VERSION ""

NS_ :

BS_:

BU_:
VAL_TABLE_ TIM_AuthErrorCode 39 "LwAPossibleBitMismatch" 38 "AuthenticationAbortedDueToGeneralPeerError" 37 "AuthenticationAbortedByPeerDueToError" 36 "ChallengeDataCorrupt" 35 "InvalidChallengeLength" 34 "FunctionFacilityNotCertified" 33 "RequestNotAllowed" 32 "Reserved_0x20" 31 "AuthenticationTimeout" 30 "CertificateTypeInvalid" 29 "DeviceCertificateRevoked" 28 "ManufacturerSeriesCertificateRevoked" 27 "ManufacturerCertificateRevoked" 26 "LabCertificateRevoked" 25 "RootCertificateRevoked" 24 "CertificateTypeMismatch" 23 "CertificateChainInvalid" 22 "ECU_CCID_Mismatch" 21 "NAME_Mismatch" 20 "ECC_PublicKeyValidationFailed" 19 "UnexpectedRestartAuthenticationBitSet" 18 "AuthenticationStatusInvalid" 17 "AuthenticationTypeNotSupported" 16 "AuthenticationStatusLost" 15 "DeviceCertificateDataCorrupt" 14 "ManufacturerSeriesCertificateDataCorrupt" 13 "ManufacturerCertificateDataCorrupt" 12 "TestLabCertificateDataCorrupt" 11 "RootCertificateDataCorrupt" 10 "InternalError" 9 "ChallengesDontMatch" 8 "DeviceCertificateSignatureInvalid" 7 "ManufacturerSeriesCertificateSignatureInvalid" 6 "ManufacturerCertificateSignatureInvalid" 5 "LabCertificateSignatureInvalid" 4 "RootCertificateSignatureInvalid" 3 "NotAuthenticationServerOrClient" 2 "CertificateFormatNotSupported" 1 "ParticipantBusy" 0 "NoError" ;
VAL_TABLE_ TIM_CertificateType 255 "NotAvailable" 6 "CRLCertificate" 5 "CRLSigningCertificate" 4 "DeviceCertificate" 3 "ManufacturerSeriesCertificate" 2 "ManufacturerCertificate" 1 "TestlabCertificate" 0 "AEFRootCertificate" ;
VAL_TABLE_ NetworkInterconnUnitParametrics 16 "NetworkInterconnectionUnitType" 15 "NumberOfPorts" 14 "UptimeSinceLastPowerOnReset " 13 "AverageNumOfMsgsFilteredPerSec" 12 "AverageNumOfMsgsForwardedPerSec" 11 "AverageNumOfMsgsReceivedPerSec" 10 "NumOfMsgsWithExcessTransitDelayTime " 9 "NumOfMsgsLostDueToBufferOverflow " 8 "AverageTransitDelayTime" 7 "MaxTransitDelayTime" 6 "MaxNumOfMsgsFilteredPerSec" 5 "MaxNumOfMsgsForwardedPerSec" 4 "MaxNumOfMsgsReceivedPerSec" 3 "NumberOfFilterDatabaseEntries" 2 "MaxFilterDatabaseSize" 1 "BufferSize" 0 "RequestAllParameters" ;
VAL_TABLE_ FMI 0 "Above normal (most severe)" 1 "Below normal (most severe)" 2 "Data erratic" 3 "Voltage above normal" 4 "Voltage below normal" 5 "Current below normal" 6 "Current above normal" 7 "Mechanical system not responding" 8 "Abnormal frequency" 9 "Abnormal update rate" 10 "Abnormal rate of change" 11 "Root cause not known" 12 "Bad intelligent device" 13 "Out of calibration" 14 "Special intstructions" 15 "Above normal (least severe)" 16 "Above normal (moderately severe)" 17 "Below normal (least severe)" 18 "Below normal (moderately severe)" 19 "Received network data in error" 31 "Not available" 20 "Data Drifted High" 21 "Data Drifted Low" ;

BO_ 2624585470 AUTH21: 16 Vector__XXX
 SG_ NumberOfAuthenticatedServers m9 : 8|8@1+ (1,0) [0|255] "" Vector__XXX
 SG_ LwAPossible m250 : 30|1@1+ (1,0) [0|0] "" Vector__XXX
 SG_ TestlabCertIsValid m250 : 29|1@1+ (1,0) [0|0] "" Vector__XXX
 SG_ ReStartAuth m250 : 31|1@1+ (1,0) [0|0] "" Vector__XXX
 SG_ ManufactSeriesCertIsValid m250 : 27|1@1+ (1,0) [0|0] "" Vector__XXX
 SG_ ManufactCertIsValid m250 : 28|1@1+ (1,0) [0|0] "" Vector__XXX
 SG_ DeviceCertIsValid m250 : 26|1@1+ (1,0) [0|0] "" Vector__XXX
 SG_ ChallengeSigned m250 : 25|1@1+ (1,0) [0|0] "" Vector__XXX
 SG_ AuthenticationStatus m250 : 16|4@1+ (1,0) [0|0] "" Vector__XXX
 SG_ ChallengeData m5 : 40|16@1+ (1,0) [0|0] "" Vector__XXX
 SG_ CertificateData m3 : 40|16@1+ (1,0) [0|0] "" Vector__XXX
 SG_ ErrorCode m3 : 8|8@1+ (1,0) [0|0] "" Vector__XXX
 SG_ CertType m2 : 32|8@1+ (1,0) [0|0] "" Vector__XXX
 SG_ CertificateFormat m2 : 24|8@1+ (1,0) [0|0] "" Vector__XXX
 SG_ AuthenticationType m2 : 20|4@1+ (1,0) [0|0] "" Vector__XXX
 SG_ MessageCode M : 0|8@1+ (1,0) [0|0] "" Vector__XXX

BO_ 2624651006 AUTH12: 16 Vector__XXX
 SG_ NumberOfAuthenticatedClients m8 : 8|8@1+ (1,0) [0|255] "" Vector__XXX
 SG_ AuthenticationStatus m249 : 16|4@1+ (1,0) [0|0] "" Vector__XXX
 SG_ ChallengeSigned m249 : 25|1@1+ (1,0) [0|0] "" Vector__XXX
 SG_ DeviceCertIsValid m249 : 26|1@1+ (1,0) [0|0] "" Vector__XXX
 SG_ ManufactSeriesCertIsValid m249 : 27|1@1+ (1,0) [0|0] "" Vector__XXX
 SG_ ManufactCertIsValid m249 : 28|1@1+ (1,0) [0|0] "" Vector__XXX
 SG_ TestlabCertIsValid m249 : 29|1@1+ (1,0) [0|0] "" Vector__XXX
 SG_ LwAPossible m249 : 30|1@1+ (1,0) [0|0] "" Vector__XXX
 SG_ ReStartAuth m249 : 31|1@1+ (1,0) [0|0] "" Vector__XXX
 SG_ ChallengeData m4 : 40|16@1+ (1,0) [0|0] "" Vector__XXX
 SG_ CertificateData m2 : 40|16@1+ (1,0) [0|0] "" Vector__XXX
 SG_ CertType m2 : 32|8@1+ (1,0) [0|0] "" Vector__XXX
 SG_ CertificateFormat m2 : 24|8@1+ (1,0) [0|0] "" Vector__XXX
 SG_ AuthenticationType m2 : 20|4@1+ (1,0) [0|0] "" Vector__XXX
 SG_ MessageCode M : 0|8@1+ (1,0) [0|0] "" Vector__XXX
 SG_ ErrorCode m2 : 8|8@1+ (1,0) [0|0] "" Vector__XXX

BO_ 2619670270 TIM21: 16 Vector__XXX
 SG_ CurvatureRequest m70 : 32|16@1+ (0.25,-8032) [-8032|8031.75] "1/km" Vector__XXX
 SG_ VehicleSpeedRequest m68 : 32|16@1+ (0.001,-32.128) [-32.127|32.127] "m/s" Vector__XXX
 SG_ HitchPosReq m66 : 32|16@1+ (0.01,0) [0|100] "%" Vector__XXX
 SG_ PTOSpeedRequest m64 : 32|16@1+ (0.125,-4016) [0|0] "1/min" Vector__XXX
 SG_ RequestCounter m1 : 8|4@1+ (1,0) [0|0] "" Vector__XXX
 SG_ AuxValveFlowReq m1 : 32|16@1+ (0.004,-128.512) [0|0] "%" Vector__XXX
 SG_ TIMClientState m249 : 20|4@1+ (1,0) [0|0] "" Vector__XXX
 SG_ ClientHearbeatCounter m249 : 8|8@1+ (1,0) [0|0] "" Vector__XXX
 SG_ TIMFunctionId_4 m245 : 64|8@1+ (1,0) [0|0] "" Vector__XXX
 SG_ TIMFunctionId_3 m245 : 48|8@1+ (1,0) [0|0] "" Vector__XXX
 SG_ TIMFunctionId_2 m245 : 32|8@1+ (1,0) [0|0] "" Vector__XXX
 SG_ TIMFunctionId_1 m245 : 16|8@1+ (1,0) [0|0] "" Vector__XXX
 SG_ NumOfTIMFunctions m245 : 8|8@1+ (1,0) [1|250] "" Vector__XXX
 SG_ RequestType_4 m245 : 77|3@1+ (1,0) [0|0] "" Vector__XXX
 SG_ RequestType_3 m245 : 61|3@1+ (1,0) [0|0] "" Vector__XXX
 SG_ RequestType_2 m245 : 45|3@1+ (1,0) [0|0] "" Vector__XXX
 SG_ RequestType_1 m245 : 29|3@1+ (1,0) [0|0] "" Vector__XXX
 SG_ MinimumTIMVersionNr m246 : 24|8@1+ (1,0) [0|0] "" Vector__XXX
 SG_ ImplementedTIMVersionNr m246 : 16|8@1+ (1,0) [0|0] "" Vector__XXX
 SG_ TIMMessageType m1 : 12|4@1+ (1,0) [0|0] "" Vector__XXX
 SG_ GroupFunctionValue M : 0|8@1+ (1,0) [0|0] "" Vector__XXX

BO_ 2619604734 TIM12: 16 Vector__XXX
 SG_ Curvature m70 : 32|16@1+ (0.25,-8032) [-8032|8031.75] "1/km" Vector__XXX
 SG_ GuidanceExitReasonCode m70 : 27|5@1+ (1,0) [0|0] "" Vector__XXX
 SG_ VehicleSpeed m68 : 32|16@1+ (0.001,-32.128) [-32.127|32.127] "m/s" Vector__XXX
 SG_ SpeedExitReasonCode m68 : 27|5@1+ (1,0) [0|0] "" Vector__XXX
 SG_ HitchPosition m66 : 32|16@1+ (0.01,0) [0|100] "%" Vector__XXX
 SG_ HitchExitReasonCode m66 : 27|5@1+ (1,0) [0|0] "" Vector__XXX
 SG_ PTOSpeed m64 : 32|16@1+ (0.125,-4016) [0|0] "1/min" Vector__XXX
 SG_ PTOExitReasonCode m64 : 27|5@1+ (1,0) [0|0] "" Vector__XXX
 SG_ TIMAuxValveFlow m1 : 32|16@1+ (0.004,-128.512) [0|0] "%" Vector__XXX
 SG_ FlowType m1 : 24|2@1+ (1,0) [0|0] "" Vector__XXX
 SG_ ReflectedRequestCounter m1 : 8|4@1+ (1,0) [0|0] "" Vector__XXX
 SG_ AuxValveExitReasonCode m1 : 27|5@1+ (1,0) [0|0] "" Vector__XXX
 SG_ AutomationStatus m1 : 16|4@1+ (1,0) [0|0] "" Vector__XXX
 SG_ TIMSystemOperationState m250 : 24|4@1+ (1,0) [0|15] "" Vector__XXX
 SG_ TIMServerState m250 : 28|4@1+ (1,0) [0|0] "" Vector__XXX
 SG_ TIMSystemState m250 : 16|4@1+ (1,0) [0|0] "" Vector__XXX
 SG_ TIMServerMasterIndication m250 : 20|4@1+ (1,0) [0|0] "" Vector__XXX
 SG_ ServerHeartbeatCounter m250 : 8|8@1+ (1,0) [0|0] "" Vector__XXX
 SG_ AssignmentResult_4 m245 : 77|3@1+ (1,0) [0|0] "" Vector__XXX
 SG_ AssignmentResult_3 m245 : 61|3@1+ (1,0) [0|0] "" Vector__XXX
 SG_ AssignmentResult_2 m245 : 45|3@1+ (1,0) [0|0] "" Vector__XXX
 SG_ AssignmentErrorReason_4 m245 : 72|5@1+ (1,0) [0|0] "" Vector__XXX
 SG_ AssignmentErrorReason_3 m245 : 56|5@1+ (1,0) [0|0] "" Vector__XXX
 SG_ AssignmentErrorReason_2 m245 : 40|5@1+ (1,0) [0|0] "" Vector__XXX
 SG_ AssignmentErrorReason_1 m245 : 24|5@1+ (1,0) [0|0] "" Vector__XXX
 SG_ AssignmentResult_1 m245 : 29|3@1+ (1,0) [0|0] "" Vector__XXX
 SG_ TIMFunctionId_4 m245 : 64|8@1+ (1,0) [0|0] "" Vector__XXX
 SG_ TIMFunctionId_3 m245 : 48|8@1+ (1,0) [0|0] "" Vector__XXX
 SG_ TIMFunctionId_2 m245 : 32|8@1+ (1,0) [0|0] "" Vector__XXX
 SG_ TIMFunctionId_1 m245 : 16|8@1+ (1,0) [0|0] "" Vector__XXX
 SG_ NumOfTIMFunctions m245 : 8|8@1+ (1,0) [1|250] "" Vector__XXX
 SG_ NumOfSuportedTIMFunctions m244 : 8|8@1+ (1,0) [1|250] "" Vector__XXX
 SG_ TIMConnectionVersion m246 : 16|8@1+ (1,0) [0|0] "" Vector__XXX
 SG_ ErrorCode m246 : 8|8@1+ (1,0) [0|0] "" Vector__XXX
 SG_ MinimumTIMVersionNr m248 : 24|8@1+ (1,0) [0|0] "" Vector__XXX
 SG_ ImplementedTIMVersionNr m248 : 16|8@1+ (1,0) [0|0] "" Vector__XXX
 SG_ BootTime m248 : 8|8@1+ (1,0) [0|0] "" Vector__XXX
 SG_ TIMMessageType m1 : 12|4@1+ (1,0) [0|0] "" Vector__XXX
 SG_ GroupFunctionValue M : 0|8@1+ (1,0) [0|0] "" Vector__XXX

BO_ 2314732542 GNSSPosDeltaHiPrecRapidUpdate: 8 Vector__XXX
 SG_ LongitudeDelta : 40|24@1- (10,0) [0|0] "µsec" Vector__XXX
 SG_ LatitudeDelta : 16|24@1- (10,0) [0|0] "µsec" Vector__XXX
 SG_ TimeDelta : 8|8@1+ (5,0) [0|0] "ms" Vector__XXX
 SG_ SequenceID : 0|8@1+ (1,0) [0|0] "" Vector__XXX

BO_ 2364597502 HB: 1 Vector__XXX
 SG_ HeartbeatSequenceNumber : 0|8@1+ (1,0) [0|0] "" Vector__XXX

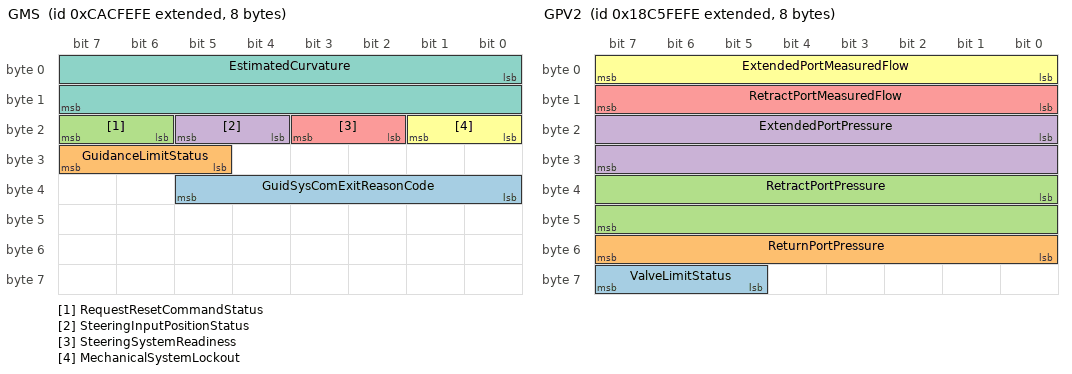
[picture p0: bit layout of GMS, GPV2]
BO_ 2360147710 GMS: 8 Vector__XXX
 SG_ GuidSysComExitReasonCode : 32|6@1+ (1,0) [0|63] "" Vector__XXX
 SG_ GuidanceLimitStatus : 29|3@1+ (1,0) [0|7] "" Vector__XXX
 SG_ RequestResetCommandStatus : 22|2@1+ (1,0) [0|3] "" Vector__XXX
 SG_ SteeringInputPositionStatus : 20|2@1+ (1,0) [0|3] "" Vector__XXX
 SG_ SteeringSystemReadiness : 18|2@1+ (1,0) [0|3] "" Vector__XXX
 SG_ MechanicalSystemLockout : 16|2@1+ (1,0) [0|3] "" Vector__XXX
 SG_ EstimatedCurvature : 0|16@1+ (0.25,-8032) [-8032|8031.75] "1/km" Vector__XXX

BO_ 2360213246 GSC: 8 Vector__XXX
 SG_ CurvatureCommandStatus : 16|2@1+ (1,0) [0|3] "" Vector__XXX
 SG_ CurvatureCommand : 0|16@1+ (0.25,-8032) [-8032|8031.75] "1/km" Vector__XXX

BO_ 2563047166 GPV3: 8 Vector__XXX
 SG_ FailSaveModeCmd : 22|2@1+ (1,0) [0|3] "" Vector__XXX
 SG_ StateCmd : 16|4@1+ (1,0) [0|15] "" Vector__XXX
 SG_ PortFlowCmd : 0|8@1+ (0.4,0) [0|100] "%" Vector__XXX

BO_ 2563112702 GPV2: 8 Vector__XXX
 SG_ ValveLimitStatus : 61|3@1+ (1,0) [0|7] "" Vector__XXX
 SG_ ReturnPortPressure : 48|8@1+ (16,0) [0|4000] "kPa" Vector__XXX
 SG_ RetractPortPressure : 32|16@1+ (5,0) [0|321275] "kPa" Vector__XXX
 SG_ ExtendedPortPressure : 16|16@1+ (5,0) [0|321275] "kPa" Vector__XXX
 SG_ RetractPortMeasuredFlow : 8|8@1+ (1,-125) [-125|125] "%" Vector__XXX
 SG_ ExtendedPortMeasuredFlow : 0|8@1+ (1,-125) [-125|125] "%" Vector__XXX

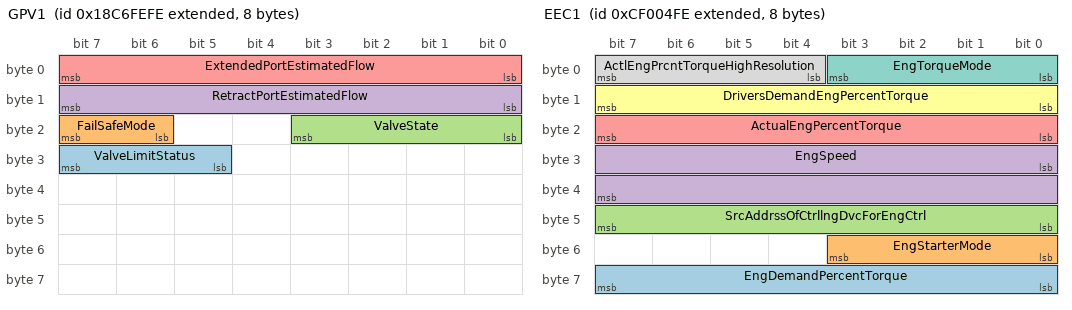
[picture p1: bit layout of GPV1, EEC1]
BO_ 2563178238 GPV1: 8 Vector__XXX
 SG_ ValveLimitStatus : 29|3@1+ (1,0) [0|7] "" Vector__XXX
 SG_ FailSafeMode : 22|2@1+ (1,0) [0|3] "" Vector__XXX
 SG_ ValveState : 16|4@1+ (1,0) [0|15] "" Vector__XXX
 SG_ RetractPortEstimatedFlow : 8|8@1+ (1,-125) [-125|125] "%" Vector__XXX
 SG_ ExtendedPortEstimatedFlow : 0|8@1+ (1,-125) [-125|125] "%" Vector__XXX

BO_ 2628452094 CFS: 9 Vector__XXX
 SG_ SA_ATTR_SupportsLongFilenames m51 : 21|1@1+ (1,0) [0|1] "" Vector__XXX
 SG_ SA_ATTR_VolumeSupportsHidden m51 : 18|1@1+ (1,0) [0|1] "" Vector__XXX
 SG_ SA_ATTR_VolumeIsRemovable m51 : 22|1@1+ (1,0) [0|1] "" Vector__XXX
 SG_ SA_ATTR_VolumeIsCaseSensitive m51 : 23|1@1+ (1,0) [0|1] "" Vector__XXX
 SG_ SA_ATTR_IsVolume m51 : 19|1@1+ (1,0) [0|1] "" Vector__XXX
 SG_ SA_ATTR_IsDirectory m51 : 20|1@1+ (1,0) [0|1] "" Vector__XXX
 SG_ VI_VolumeName m64 : 56|16@1+ (1,0) [0|65535] "" Vector__XXX
 SG_ VI_Flag_OverwriteExisting m64 : 48|1@1+ (1,0) [0|1] "" Vector__XXX
 SG_ MF_DestinationPathNameLength m48 : 40|16@1+ (1,0) [0|65535] "" Vector__XXX
 SG_ RF_ReportHiddenFiles m34 : 40|8@1+ (1,0) [0|255] "" Vector__XXX
 SG_ SF_Offset m33 : 32|32@1- (1,0) [-2147483648|2147483647] "" Vector__XXX
 SG_ RF_Count m34 : 24|16@1+ (1,0) [0|65535] "" Vector__XXX
 SG_ SF_PositionMode m33 : 24|8@1+ (1,0) [0|255] "" Vector__XXX
 SG_ OF_PathName m32 : 24|16@1+ (1,0) [0|65535] "" Vector__XXX
 SG_ MF_SourcePathNameLength m48 : 24|16@1+ (1,0) [0|65535] "" Vector__XXX
 SG_ WF_Count m35 : 24|16@1+ (1,0) [0|65535] "" Vector__XXX
 SG_ DF_PathName m49 : 24|16@1+ (1,0) [0|65535] "" Vector__XXX
 SG_ SA_PathName m51 : 24|16@1+ (1,0) [0|65535] "" Vector__XXX
 SG_ VI_Space m64 : 16|32@1+ (1,0) [0|4294967295] "" Vector__XXX
 SG_ OF_FlagExclusiveAccess m32 : 20|1@1+ (1,0) [0|1] "" Vector__XXX
 SG_ OF_FlagAppend m32 : 19|1@1+ (1,0) [0|1] "" Vector__XXX
 SG_ SA_ATTR_Hidden m51 : 17|1@1+ (1,0) [0|1] "" Vector__XXX
 SG_ OF_FlagCreateNew m32 : 18|1@1+ (1,0) [0|1] "" Vector__XXX
 SG_ MF_MoveModeRecursive m48 : 18|1@1+ (1,0) [0|1] "" Vector__XXX
 SG_ DF_DeleteModeRecursive m49 : 18|1@1+ (1,0) [0|1] "" Vector__XXX
 SG_ MF_MoveModeForce m48 : 17|1@1+ (1,0) [0|1] "" Vector__XXX
 SG_ DF_DeleteModeForce m49 : 17|1@1+ (1,0) [0|1] "" Vector__XXX
 SG_ VI_Flag_UsingSpaceSpecified m64 : 49|1@1+ (1,0) [0|1] "" Vector__XXX
 SG_ SA_ATTR_ReadOnly m51 : 16|1@1+ (1,0) [0|1] "" Vector__XXX
 SG_ CF_Handle m36 : 16|8@1+ (1,0) [0|255] "" Vector__XXX
 SG_ WF_Handle m35 : 16|8@1+ (1,0) [0|255] "" Vector__XXX
 SG_ RF_Handle m34 : 16|8@1+ (1,0) [0|255] "" Vector__XXX
 SG_ SF_Handle m33 : 16|8@1+ (1,0) [0|255] "" Vector__XXX
 SG_ OF_FlagReadWrite m32 : 16|2@1+ (1,0) [0|3] "" Vector__XXX
 SG_ CCD_PathName m17 : 16|16@1+ (1,0) [0|65535] "" Vector__XXX
 SG_ MF_MoveModeCopy m48 : 16|1@1+ (1,0) [0|1] "" Vector__XXX
 SG_ DF_DeleteMode m49 : 16|1@1+ (1,0) [0|1] "" Vector__XXX
 SG_ GA_PathName m50 : 16|16@1+ (1,0) [0|65535] "" Vector__XXX
 SG_ FDT_PathName m52 : 16|16@1+ (1,0) [0|65535] "" Vector__XXX
 SG_ VS_VolumeName m2 : 16|16@1+ (1,0) [0|0] "" Vector__XXX
 SG_ VS_RequestVolumeToPrepareForRemo m2 : 9|1@1- (1,0) [0|1] "" Vector__XXX
 SG_ CCD_TAN m17 : 8|8@1+ (1,0) [0|255] "" Vector__XXX
 SG_ GCD_TAN m16 : 8|8@1+ (1,0) [0|255] "" Vector__XXX
 SG_ FDT_TAN m52 : 8|8@1+ (1,0) [0|255] "" Vector__XXX
 SG_ SA_TAN m51 : 8|8@1+ (1,0) [0|255] "" Vector__XXX
 SG_ GA_TAN m50 : 8|8@1+ (1,0) [0|255] "" Vector__XXX
 SG_ RF_TAN m34 : 8|8@1+ (1,0) [0|255] "" Vector__XXX
 SG_ CF_TAN m36 : 8|8@1+ (1,0) [0|255] "" Vector__XXX
 SG_ WF_TAN m35 : 8|8@1+ (1,0) [0|255] "" Vector__XXX
 SG_ SF_TAN m33 : 8|8@1+ (1,0) [0|255] "" Vector__XXX
 SG_ OF_TAN m32 : 8|8@1+ (1,0) [0|255] "" Vector__XXX
 SG_ MF_TAN m48 : 8|8@1+ (1,0) [0|255] "" Vector__XXX
 SG_ DF_TAN m49 : 8|8@1+ (1,0) [0|255] "" Vector__XXX
 SG_ VI_TAN m64 : 8|8@1+ (1,0) [0|255] "" Vector__XXX
 SG_ VS_ReportVolumeUsedByClient m2 : 8|1@1+ (1,0) [0|1] "" Vector__XXX
 SG_ CM_VersionNumber m0 : 8|8@1+ (1,0) [0|255] "" Vector__XXX
 SG_ FSClientCommand M : 0|8@1+ (1,0) [0|255] "" Vector__XXX

BO_ 2628517630 FSC: 35 Vector__XXX
 SG_ OF_ATTR_VolumeSupportsHidden m32 : 34|1@1+ (1,0) [0|1] "" Vector__XXX
 SG_ GCD_PathName m16 : 88|16@1+ (1,0) [0|65535] "" Vector__XXX
 SG_ GCD_FreeSpace m16 : 56|32@1+ (512,0) [0|4294966744] "Bytes" Vector__XXX
 SG_ FDT_TimeHour m52 : 51|5@1+ (1,0) [0|23] "Hour" Vector__XXX
 SG_ FDT_TimeMinutes m52 : 45|6@1+ (1,0) [0|59] "Minutes" Vector__XXX
 SG_ FDT_TimeSeconds m52 : 40|5@1+ (2,0) [0|58] "Seconds" Vector__XXX
 SG_ OF_ATTR_VolumeIsCaseSensitive m32 : 39|1@1+ (1,0) [0|1] "" Vector__XXX
 SG_ OF_ATTR_VolumeIsRemovable m32 : 38|1@1+ (1,0) [0|1] "" Vector__XXX
 SG_ OF_ATTR_SupportsLongFilenames m32 : 37|1@1+ (1,0) [0|1] "" Vector__XXX
 SG_ OF_ATTR_IsDirectory m32 : 36|1@1+ (1,0) [0|1] "" Vector__XXX
 SG_ OF_ATTR_IsVolume m32 : 35|1@1+ (1,0) [0|1] "" Vector__XXX
 SG_ FDT_DateYear m52 : 33|7@1+ (1,1980) [1980|2107] "Year" Vector__XXX
 SG_ OF_ATTR_Hidden m32 : 33|1@1+ (1,0) [0|1] "" Vector__XXX
 SG_ SF_Position m33 : 32|32@1+ (1,0) [0|4294967295] "" Vector__XXX
 SG_ OF_ATTR_ReadOnly m32 : 32|1@1+ (1,0) [0|1] "" Vector__XXX
 SG_ GA_Size m50 : 32|32@1+ (1,0) [0|4294967295] "" Vector__XXX
 SG_ VS_VolumeName m2 : 32|16@1+ (1,0) [0|65535] "" Vector__XXX
 SG_ VI_VolumeIsCaseSensitive m64 : 31|1@1+ (1,0) [0|1] "" Vector__XXX
 SG_ GA_ATTR_VolumeIsCaseSensitive m50 : 31|1@1+ (1,0) [0|1] "" Vector__XXX
 SG_ VI_ATTR_VolumeRemovable m64 : 30|1@1+ (1,0) [0|1] "" Vector__XXX
 SG_ GA_ATTR_VolumeIsRemovable m50 : 30|1@1+ (1,0) [0|1] "" Vector__XXX
 SG_ VI_ATTR_SupportsLongFilenames m64 : 29|1@1+ (1,0) [0|1] "" Vector__XXX
 SG_ FDT_DateMonth m52 : 29|4@1+ (1,0) [0|12] "Month" Vector__XXX
 SG_ GA_ATTR_SupportsLongFilenames m50 : 29|1@1+ (1,0) [0|1] "" Vector__XXX
 SG_ GA_ATTR_IsDirectory m50 : 28|1@1+ (1,0) [0|1] "" Vector__XXX
 SG_ VI_ATTR_IsDirectory m64 : 28|1@1+ (1,0) [0|1] "" Vector__XXX
 SG_ VI_ATTR_IsVolume m64 : 27|1@1+ (1,0) [0|1] "" Vector__XXX
 SG_ GA_ATTR_IsVolume m50 : 27|1@1+ (1,0) [0|1] "" Vector__XXX
 SG_ VI_ATTR_VolumeSupportsHidden m64 : 26|1@1+ (1,0) [0|1] "" Vector__XXX
 SG_ GA_ATTR_VolumeSupportsHidden m50 : 26|1@1+ (1,0) [0|1] "" Vector__XXX
 SG_ VI_ATTR_Hidden m64 : 25|1@1+ (1,0) [0|1] "" Vector__XXX
 SG_ GA_ATTR_Hidden m50 : 25|1@1+ (1,0) [0|1] "" Vector__XXX
 SG_ VI_ATTR_ReadOnly m64 : 24|1@1+ (1,0) [0|1] "" Vector__XXX
 SG_ FDT_DateDay m52 : 24|5@1+ (1,0) [0|31] "Day" Vector__XXX
 SG_ GA_ATTR_ReadOnly m50 : 24|1@1+ (1,0) [0|1] "" Vector__XXX
 SG_ OF_Handle m32 : 24|8@1+ (1,0) [0|255] "" Vector__XXX
 SG_ GCD_TotalSpace m16 : 24|32@1+ (512,0) [0|4294966744] "Bytes" Vector__XXX
 SG_ RF_Count m34 : 24|16@1+ (1,0) [0|65535] "Bytes" Vector__XXX
 SG_ GSP_SupportMultipleVolumes m1 : 24|1@1+ (1,0) [0|255] "" Vector__XXX
 SG_ WF_Count m35 : 24|16@1+ (1,0) [0|65535] "" Vector__XXX
 SG_ VS_ErrorCode m2 : 24|8@1+ (1,0) [0|255] "" Vector__XXX
 SG_ FDT_ErrorCode m52 : 16|8@1+ (1,0) [0|255] "" Vector__XXX
 SG_ RF_ErrorCode m34 : 16|8@1+ (1,0) [0|255] "" Vector__XXX
 SG_ SF_ErrorCode m33 : 16|8@1+ (1,0) [0|255] "" Vector__XXX
 SG_ FSNumberOfOpenFiles m0 : 16|8@1- (1,0) [0|255] "" Vector__XXX
 SG_ OF_ErrorCode m32 : 16|8@1+ (1,0) [0|255] "" Vector__XXX
 SG_ WF_ErrorCode m35 : 16|8@1+ (1,0) [0|255] "" Vector__XXX
 SG_ CF_ErrorCode m36 : 16|8@1+ (1,0) [0|255] "" Vector__XXX
 SG_ MF_ErrorCode m48 : 16|8@1+ (1,0) [0|255] "" Vector__XXX
 SG_ GA_ErrorCode m50 : 16|8@1+ (1,0) [0|255] "" Vector__XXX
 SG_ SA_ErrorCode m51 : 16|8@1+ (1,0) [0|255] "" Vector__XXX
 SG_ GCD_ErrorCode m16 : 16|8@1+ (1,0) [0|255] "" Vector__XXX
 SG_ CCD_ErrorCode m17 : 16|8@1+ (1,0) [0|255] "" Vector__XXX
 SG_ GSP_MaxNrSimultaneousFilesOpen m1 : 16|8@1+ (1,0) [0|255] "" Vector__XXX
 SG_ DF_ErrorCode m49 : 16|8@1+ (1,0) [0|255] "" Vector__XXX
 SG_ VI_ErrorCode m64 : 16|8@1+ (1,0) [0|255] "" Vector__XXX
 SG_ VS_MaxTimeBeforeVolRemoval m2 : 16|8@1+ (1,0) [0|250] "min/bit" Vector__XXX
 SG_ FSBusyWriting m0 : 9|1@1+ (1,0) [0|1] "" Vector__XXX
 SG_ FSBusyReading m0 : 8|1@1+ (1,0) [0|1] "" Vector__XXX
 SG_ OF_TAN m32 : 8|8@1+ (1,0) [0|255] "" Vector__XXX
 SG_ SF_TAN m33 : 8|8@1+ (1,0) [0|255] "" Vector__XXX
 SG_ RF_TAN m34 : 8|8@1+ (1,0) [0|255] "" Vector__XXX
 SG_ WF_TAN m35 : 8|8@1+ (1,0) [0|255] "" Vector__XXX
 SG_ CF_TAN m36 : 8|8@1+ (1,0) [0|255] "" Vector__XXX
 SG_ MF_TAN m48 : 8|8@1+ (1,0) [0|255] "" Vector__XXX
 SG_ GA_TAN m50 : 8|8@1+ (1,0) [0|255] "" Vector__XXX
 SG_ SA_TAN m51 : 8|8@1+ (1,0) [0|255] "" Vector__XXX
 SG_ FDT_TAN m52 : 8|8@1+ (1,0) [0|255] "" Vector__XXX
 SG_ GCD_TAN m16 : 8|8@1+ (1,0) [0|255] "" Vector__XXX
 SG_ CCD_TAN m17 : 8|8@1+ (1,0) [0|255] "" Vector__XXX
 SG_ GSP_VersionNumber m1 : 8|8@1+ (1,0) [0|255] "" Vector__XXX
 SG_ DF_TAN m49 : 8|8@1+ (1,0) [0|255] "" Vector__XXX
 SG_ VI_TAN m64 : 8|8@1+ (1,0) [0|255] "" Vector__XXX
 SG_ VS_VolumeStatus m2 : 8|8@1+ (1,0) [0|3] "" Vector__XXX
 SG_ FSServerCommand M : 0|8@1+ (1,0) [0|255] "" Vector__XXX

BO_ 2364540158 EEC1: 8 Vector__XXX
 SG_ EngDemandPercentTorque : 56|8@1+ (1,-125) [-125|125] "%" Vector__XXX
 SG_ EngStarterMode : 48|4@1+ (1,0) [0|15] "" Vector__XXX
 SG_ SrcAddrssOfCtrllngDvcForEngCtrl : 40|8@1+ (1,0) [0|255] "" Vector__XXX
 SG_ EngSpeed : 24|16@1+ (0.125,0) [0|8031.875] "rpm" Vector__XXX
 SG_ ActualEngPercentTorque : 16|8@1+ (1,-125) [-125|125] "%" Vector__XXX
 SG_ DriversDemandEngPercentTorque : 8|8@1+ (1,-125) [-125|125] "%" Vector__XXX
 SG_ EngTorqueMode : 0|4@1+ (1,0) [0|15] "" Vector__XXX
 SG_ ActlEngPrcntTorqueHighResolution : 4|4@1+ (0.125,0) [0|0.875] "%" Vector__XXX

BO_ 2563243774 ETP_DT: 8 Vector__XXX
 SG_ Byte7 : 56|8@1+ (1,0) [0|255] "" Vector__XXX
 SG_ Byte6 : 48|8@1+ (1,0) [0|255] "" Vector__XXX
 SG_ Byte5 : 40|8@1+ (1,0) [0|255] "" Vector__XXX
 SG_ Byte4 : 32|8@1+ (1,0) [0|255] "" Vector__XXX
 SG_ Byte3 : 24|8@1+ (1,0) [0|255] "" Vector__XXX
 SG_ Byte2 : 16|8@1+ (1,0) [0|255] "" Vector__XXX
 SG_ Byte1 : 8|8@1+ (1,0) [0|255] "" Vector__XXX
 SG_ SequenceNumber : 0|8@1+ (1,0) [1|255] "" Vector__XXX

BO_ 2563309310 ETP_CM: 8 Vector__XXX
 SG_ PGNumber : 40|24@1+ (1,0) [0|16777200] "" Vector__XXX
 SG_ DataPacketOffset m22 : 16|24@1+ (1,0) [0|16777215] "" Vector__XXX
 SG_ NextPacketNumberToSend m21 : 16|24@1+ (1,0) [1|16777215] "" Vector__XXX
 SG_ NumberOfBytesTransfered m23 : 8|32@1+ (1,0) [1786|117440505] "" Vector__XXX
 SG_ NumberOfPacketsOffset m22 : 8|8@1+ (1,0) [1|255] "" Vector__XXX
 SG_ NumberOfPacketsToSend m21 : 8|8@1+ (1,0) [1|255] "" Vector__XXX
 SG_ NumberOfBytesToTransfer m20 : 8|32@1+ (1,0) [1786|117440505] "" Vector__XXX
 SG_ ControlByte M : 0|8@1+ (1,0) [0|255] "" Vector__XXX
 SG_ ConnectionAbortReason m255 : 8|8@1+ (1,0) [0|255] "" Vector__XXX

BO_ 2314732030 GNSSPositionRapidUpdate: 8 Vector__XXX
 SG_ Longitude : 32|32@1- (1E-007,0) [-180|180] "deg" Vector__XXX
 SG_ Latitude : 0|32@1- (1E-007,0) [-90|90] "deg" Vector__XXX

BO_ 2583168510 GNSSPositionData: 47 Vector__XXX
 SG_ AgeOfDGNSSCorrections1 : 360|16@1+ (0.01,0) [0|655.32] "sec" Vector__XXX
 SG_ ReferenceStationID1 : 348|12@1+ (1,0) [0|4095] "" Vector__XXX
 SG_ RefrenceStationType1 : 344|4@1+ (1,0) [0|15] "" Vector__XXX
 SG_ NumberOfReferenceStations : 336|8@1+ (1,0) [0|252] "" Vector__XXX
 SG_ GeoidalSeparation : 304|32@1- (0.01,0) [-21470000|21470000] "m" Vector__XXX
 SG_ PDOP : 288|16@1- (0.01,0) [-327.64|327.64] "" Vector__XXX
 SG_ HDOP : 272|16@1- (0.01,0) [-327.64|327.64] "" Vector__XXX
 SG_ NumberOfSVs : 264|8@1+ (1,0) [0|252] "" Vector__XXX
 SG_ GNSSIntegrity : 256|2@1+ (1,0) [0|3] "" Vector__XXX
 SG_ GNSSMethod : 252|4@1+ (1,0) [0|15] "" Vector__XXX
 SG_ TypeOfSystem : 248|4@1+ (1,0) [0|4] "" Vector__XXX
 SG_ Altitude : 184|64@1- (1E-006,0) [-9223372036854.78|9223372036854.78] "m" Vector__XXX
 SG_ Longitude : 120|64@1- (1E-016,0) [-180|180] "deg" Vector__XXX
 SG_ Latitude : 56|64@1- (1E-016,0) [-90|90] "deg" Vector__XXX
 SG_ PositionTime : 24|32@1+ (0.0001,0) [0|86401] "s" Vector__XXX
 SG_ PositionDate : 8|16@1+ (1,0) [0|65532] "day" Vector__XXX
 SG_ SequenceID : 0|8@1+ (1,0) [0|255] "" Vector__XXX

BO_ 2583299838 GNSSPseudoRangeNoiseStatistic: 15 Vector__XXX
 SG_ STDofAltError : 104|16@1+ (0.01,0) [0|655.32] "m" Vector__XXX
 SG_ STDofLonError : 88|16@1+ (0.01,0) [0|655.32] "m" Vector__XXX
 SG_ STDofLatError : 72|16@1+ (0.01,0) [0|655.32] "m" Vector__XXX
 SG_ OrientationOfMinorAxis : 56|16@1+ (0.0001,0) [0|6.2832] "rad" Vector__XXX
 SG_ STDofMinorAxis : 40|16@1+ (0.01,0) [0|655.32] "m" Vector__XXX
 SG_ STDofMajorAxis : 24|16@1+ (0.01,0) [0|655.32] "m" Vector__XXX
 SG_ RMSofPositionUncertainty : 8|16@1+ (0.01,0) [0|655.32] "m" Vector__XXX
 SG_ SequenceID : 0|8@1+ (1,0) [0|255] "" Vector__XXX

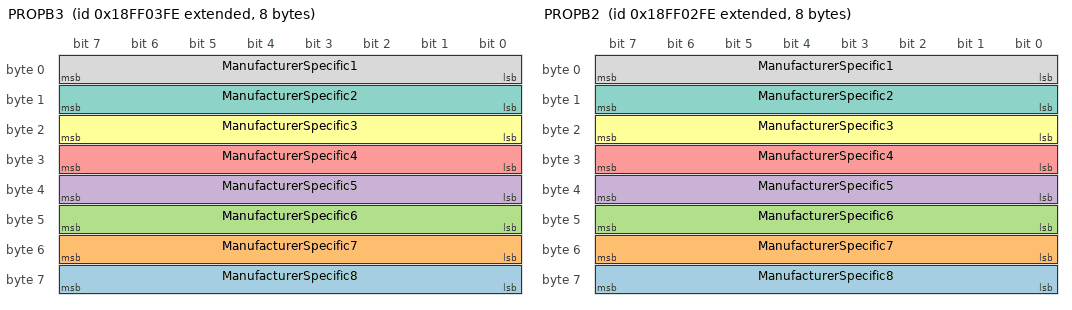
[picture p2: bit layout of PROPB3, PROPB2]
BO_ 2566849534 PROPB3: 8 Vector__XXX
 SG_ ManufacturerSpecific8 : 56|8@1+ (1,0) [0|255] "" Vector__XXX
 SG_ ManufacturerSpecific7 : 48|8@1+ (1,0) [0|255] "" Vector__XXX
 SG_ ManufacturerSpecific6 : 40|8@1+ (1,0) [0|255] "" Vector__XXX
 SG_ ManufacturerSpecific5 : 32|8@1+ (1,0) [0|255] "" Vector__XXX
 SG_ ManufacturerSpecific4 : 24|8@1+ (1,0) [0|255] "" Vector__XXX
 SG_ ManufacturerSpecific3 : 16|8@1+ (1,0) [0|255] "" Vector__XXX
 SG_ ManufacturerSpecific2 : 8|8@1+ (1,0) [0|255] "" Vector__XXX
 SG_ ManufacturerSpecific1 : 0|8@1+ (1,0) [0|255] "" Vector__XXX

BO_ 2566849278 PROPB2: 8 Vector__XXX
 SG_ ManufacturerSpecific8 : 56|8@1+ (1,0) [0|255] "" Vector__XXX
 SG_ ManufacturerSpecific7 : 48|8@1+ (1,0) [0|255] "" Vector__XXX
 SG_ ManufacturerSpecific6 : 40|8@1+ (1,0) [0|255] "" Vector__XXX
 SG_ ManufacturerSpecific5 : 32|8@1+ (1,0) [0|255] "" Vector__XXX
 SG_ ManufacturerSpecific4 : 24|8@1+ (1,0) [0|255] "" Vector__XXX
 SG_ ManufacturerSpecific3 : 16|8@1+ (1,0) [0|255] "" Vector__XXX
 SG_ ManufacturerSpecific2 : 8|8@1+ (1,0) [0|255] "" Vector__XXX
 SG_ ManufacturerSpecific1 : 0|8@1+ (1,0) [0|255] "" Vector__XXX

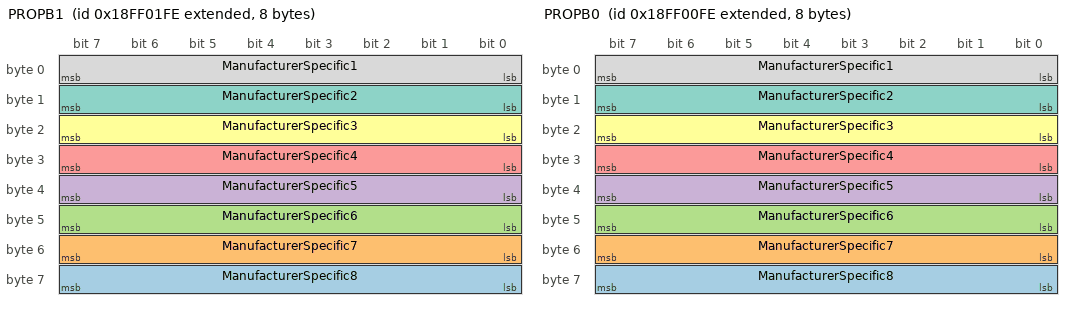
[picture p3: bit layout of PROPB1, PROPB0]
BO_ 2566849022 PROPB1: 8 Vector__XXX
 SG_ ManufacturerSpecific8 : 56|8@1+ (1,0) [0|255] "" Vector__XXX
 SG_ ManufacturerSpecific7 : 48|8@1+ (1,0) [0|255] "" Vector__XXX
 SG_ ManufacturerSpecific6 : 40|8@1+ (1,0) [0|255] "" Vector__XXX
 SG_ ManufacturerSpecific5 : 32|8@1+ (1,0) [0|255] "" Vector__XXX
 SG_ ManufacturerSpecific4 : 24|8@1+ (1,0) [0|255] "" Vector__XXX
 SG_ ManufacturerSpecific3 : 16|8@1+ (1,0) [0|255] "" Vector__XXX
 SG_ ManufacturerSpecific2 : 8|8@1+ (1,0) [0|255] "" Vector__XXX
 SG_ ManufacturerSpecific1 : 0|8@1+ (1,0) [0|255] "" Vector__XXX

BO_ 2566848766 PROPB0: 8 Vector__XXX
 SG_ ManufacturerSpecific8 : 56|8@1+ (1,0) [0|255] "" Vector__XXX
 SG_ ManufacturerSpecific7 : 48|8@1+ (1,0) [0|255] "" Vector__XXX
 SG_ ManufacturerSpecific6 : 40|8@1+ (1,0) [0|255] "" Vector__XXX
 SG_ ManufacturerSpecific5 : 32|8@1+ (1,0) [0|255] "" Vector__XXX
 SG_ ManufacturerSpecific4 : 24|8@1+ (1,0) [0|255] "" Vector__XXX
 SG_ ManufacturerSpecific3 : 16|8@1+ (1,0) [0|255] "" Vector__XXX
 SG_ ManufacturerSpecific2 : 8|8@1+ (1,0) [0|255] "" Vector__XXX
 SG_ ManufacturerSpecific1 : 0|8@1+ (1,0) [0|255] "" Vector__XXX

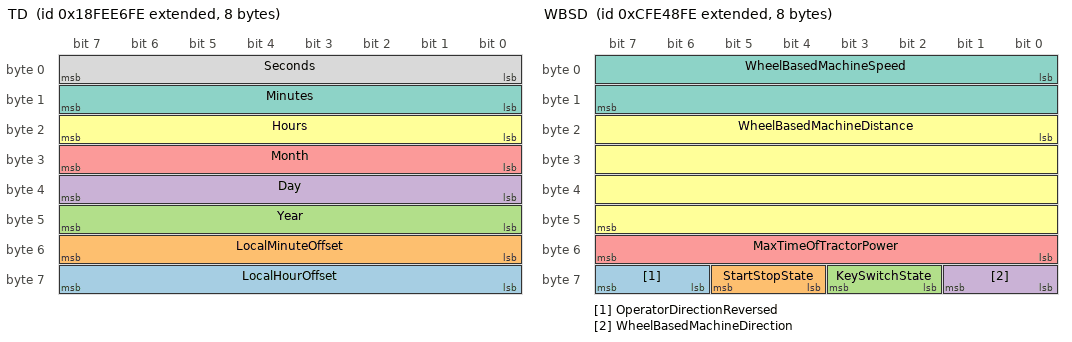
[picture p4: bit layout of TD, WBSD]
BO_ 2566842110 TD: 8 Vector__XXX
 SG_ LocalHourOffset : 56|8@1+ (1,-125) [-125|125] "hr" Vector__XXX
 SG_ LocalMinuteOffset : 48|8@1+ (1,-125) [-125|125] "mins" Vector__XXX
 SG_ Year : 40|8@1+ (1,1985) [1985|2235] "years" Vector__XXX
 SG_ Day : 32|8@1+ (0.25,0) [0|62.5] "days" Vector__XXX
 SG_ Month : 24|8@1+ (1,0) [0|250] "months" Vector__XXX
 SG_ Hours : 16|8@1+ (1,0) [0|250] "hr" Vector__XXX
 SG_ Minutes : 8|8@1+ (1,0) [0|250] "mins" Vector__XXX
 SG_ Seconds : 0|8@1+ (0.25,0) [0|62.5] "s" Vector__XXX

BO_ 2365475326 GBSD: 8 Vector__XXX
 SG_ GroundBasedMachineDirection : 56|2@1+ (1,0) [0|3] "" Vector__XXX
 SG_ GroundBasedMachineDistance : 16|32@1+ (0.001,0) [0|4211080] "m" Vector__XXX
 SG_ GroundBasedMachineSpeed : 0|16@1+ (0.001,0) [0|64.255] "m/s" Vector__XXX

BO_ 2365475070 WBSD: 8 Vector__XXX
 SG_ OperatorDirectionReversed : 62|2@1+ (1,0) [0|3] "" Vector__XXX
 SG_ StartStopState : 60|2@1+ (1,0) [0|4] "" Vector__XXX
 SG_ KeySwitchState : 58|2@1+ (1,0) [0|3] "" Vector__XXX
 SG_ WheelBasedMachineDirection : 56|2@1+ (1,0) [0|3] "" Vector__XXX
 SG_ MaxTimeOfTractorPower : 48|8@1+ (1,0) [0|250] "min" Vector__XXX
 SG_ WheelBasedMachineDistance : 16|32@1+ (0.001,0) [0|4211081.215] "m" Vector__XXX
 SG_ WheelBasedMachineSpeed : 0|16@1+ (0.001,0) [0|64.255] "m/s" Vector__XXX

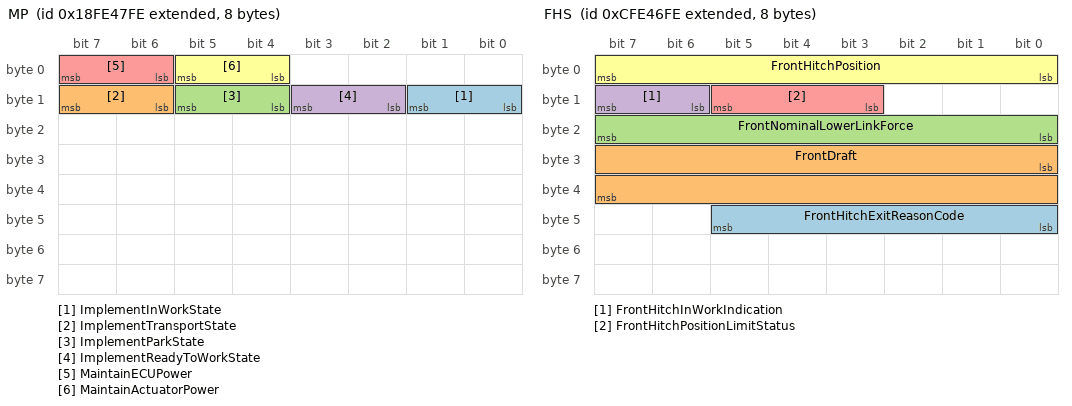
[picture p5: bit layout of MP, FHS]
BO_ 2566801406 MP: 8 Vector__XXX
 SG_ ImplementInWorkState : 8|2@1+ (1,0) [0|0] "" Vector__XXX
 SG_ ImplementTransportState : 14|2@1+ (1,0) [0|3] "" Vector__XXX
 SG_ ImplementParkState : 12|2@1+ (1,0) [0|3] "" Vector__XXX
 SG_ ImplementReadyToWorkState : 10|2@1+ (1,0) [0|3] "" Vector__XXX
 SG_ MaintainECUPower : 6|2@1+ (1,0) [0|0] "" Vector__XXX
 SG_ MaintainActuatorPower : 4|2@1+ (1,0) [0|3] "" Vector__XXX

BO_ 2365474558 FHS: 8 Vector__XXX
 SG_ FrontHitchExitReasonCode : 40|6@1+ (1,0) [0|63] "" Vector__XXX
 SG_ FrontDraft : 24|16@1+ (10,-320000) [-320000|322550] "N" Vector__XXX
 SG_ FrontNominalLowerLinkForce : 16|8@1+ (0.8,-100) [-100|100] "%" Vector__XXX
 SG_ FrontHitchInWorkIndication : 14|2@1+ (1,0) [0|3] "" Vector__XXX
 SG_ FrontHitchPositionLimitStatus : 11|3@1+ (1,0) [0|7] "" Vector__XXX
 SG_ FrontHitchPosition : 0|8@1+ (0.4,0) [0|100] "%" Vector__XXX

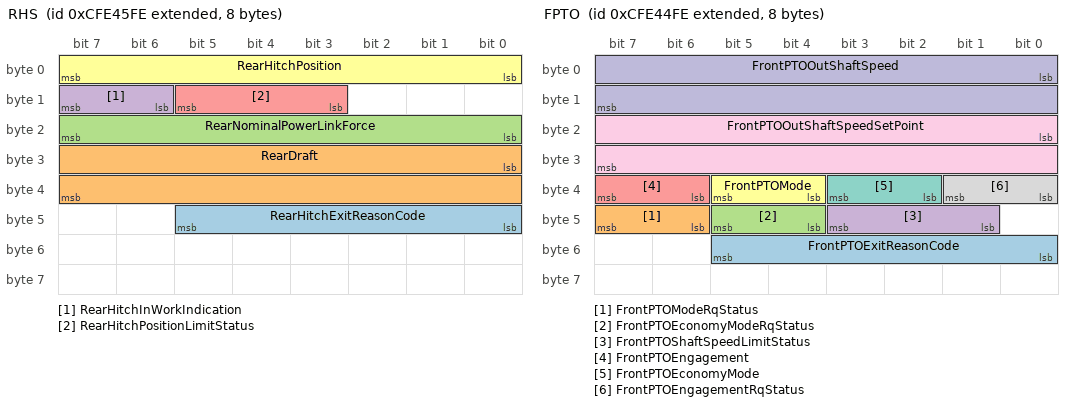
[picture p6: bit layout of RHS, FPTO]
BO_ 2365474302 RHS: 8 Vector__XXX
 SG_ RearHitchExitReasonCode : 40|6@1+ (1,0) [0|63] "" Vector__XXX
 SG_ RearDraft : 24|16@1+ (10,-320000) [-320000|322550] "N" Vector__XXX
 SG_ RearNominalPowerLinkForce : 16|8@1+ (0.8,-100) [-100|100] "%" Vector__XXX
 SG_ RearHitchInWorkIndication : 14|2@1+ (1,0) [0|3] "" Vector__XXX
 SG_ RearHitchPositionLimitStatus : 11|3@1+ (1,0) [0|7] "" Vector__XXX
 SG_ RearHitchPosition : 0|8@1+ (0.4,0) [0|100] "%" Vector__XXX

BO_ 2365474046 FPTO: 8 Vector__XXX
 SG_ FrontPTOExitReasonCode : 48|6@1+ (1,0) [0|63] "" Vector__XXX
 SG_ FrontPTOModeRqStatus : 46|2@1+ (1,0) [0|3] "" Vector__XXX
 SG_ FrontPTOEconomyModeRqStatus : 44|2@1+ (1,0) [0|3] "" Vector__XXX
 SG_ FrontPTOShaftSpeedLimitStatus : 41|3@1+ (1,0) [0|7] "" Vector__XXX
 SG_ FrontPTOEngagement : 38|2@1+ (1,0) [0|3] "" Vector__XXX
 SG_ FrontPTOMode : 36|2@1+ (1,0) [0|3] "" Vector__XXX
 SG_ FrontPTOEconomyMode : 34|2@1+ (1,0) [0|3] "" Vector__XXX
 SG_ FrontPTOEngagementRqStatus : 32|2@1+ (1,0) [0|3] "" Vector__XXX
 SG_ FrontPTOOutShaftSpeedSetPoint : 16|16@1+ (0.125,0) [0|8031.88] "1/min" Vector__XXX
 SG_ FrontPTOOutShaftSpeed : 0|16@1+ (0.125,0) [0|8031.88] "1/min" Vector__XXX

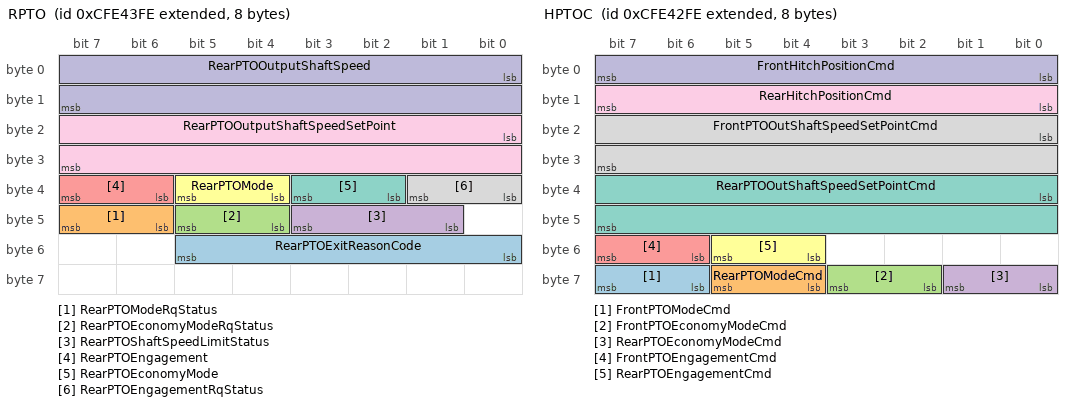
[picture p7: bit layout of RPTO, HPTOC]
BO_ 2365473790 RPTO: 8 Vector__XXX
 SG_ RearPTOExitReasonCode : 48|6@1+ (1,0) [0|63] "" Vector__XXX
 SG_ RearPTOModeRqStatus : 46|2@1+ (1,0) [0|3] "" Vector__XXX
 SG_ RearPTOEconomyModeRqStatus : 44|2@1+ (1,0) [0|3] "" Vector__XXX
 SG_ RearPTOShaftSpeedLimitStatus : 41|3@1+ (1,0) [0|7] "" Vector__XXX
 SG_ RearPTOEngagement : 38|2@1+ (1,0) [0|3] "" Vector__XXX
 SG_ RearPTOMode : 36|2@1+ (1,0) [0|3] "" Vector__XXX
 SG_ RearPTOEconomyMode : 34|2@1+ (1,0) [0|3] "" Vector__XXX
 SG_ RearPTOEngagementRqStatus : 32|2@1+ (1,0) [0|3] "" Vector__XXX
 SG_ RearPTOOutputShaftSpeedSetPoint : 16|16@1+ (0.125,0) [0|8031.88] "1/min" Vector__XXX
 SG_ RearPTOOutputShaftSpeed : 0|16@1+ (0.125,0) [0|8031.88] "1/min" Vector__XXX

BO_ 2365473534 HPTOC: 8 Vector__XXX
 SG_ FrontPTOModeCmd : 62|2@1+ (1,0) [0|3] "" Vector__XXX
 SG_ RearPTOModeCmd : 60|2@1+ (1,0) [0|3] "" Vector__XXX
 SG_ FrontPTOEconomyModeCmd : 58|2@1+ (1,0) [0|3] "" Vector__XXX
 SG_ RearPTOEconomyModeCmd : 56|2@1+ (1,0) [0|3] "" Vector__XXX
 SG_ FrontPTOEngagementCmd : 54|2@1+ (1,0) [0|3] "" Vector__XXX
 SG_ RearPTOEngagementCmd : 52|2@1+ (1,0) [0|3] "" Vector__XXX
 SG_ RearPTOOutShaftSpeedSetPointCmd : 32|16@1+ (0.125,0) [0|801.875] "1/min" Vector__XXX
 SG_ FrontPTOOutShaftSpeedSetPointCmd : 16|16@1+ (0.125,0) [0|8031.875] "1/min" Vector__XXX
 SG_ RearHitchPositionCmd : 8|8@1+ (0.4,0) [0|100] "%" Vector__XXX
 SG_ FrontHitchPositionCmd : 0|8@1+ (0.4,0) [0|100] "%" Vector__XXX

BO_ 2365473278 LCMD: 8 Vector__XXX
 SG_ ImplementRearWorkLightCmd : 62|2@1+ (1,0) [0|3] "" Vector__XXX
 SG_ ImplementLeftFacingWorkLightCmd : 60|2@1+ (1,0) [0|3] "" Vector__XXX
 SG_ ImplementRightFacingWorkLightCmd : 58|2@1+ (1,0) [0|3] "" Vector__XXX
 SG_ LightingDataRequestCmd : 56|2@1+ (1,0) [0|3] "" Vector__XXX
 SG_ ImplementLeftForwardLightCmd : 54|2@1+ (1,0) [0|3] "" Vector__XXX
 SG_ ImplementRightForwardLightCmd : 52|2@1+ (1,0) [0|3] "" Vector__XXX
 SG_ ImplementOEMOption1LightCmd : 50|2@1+ (1,0) [0|3] "" Vector__XXX
 SG_ ImplementOEMOption2LightCmd : 48|2@1+ (1,0) [0|3] "" Vector__XXX
 SG_ TractorFrontHighWorkLightCmd : 46|2@1+ (1,0) [0|3] "" Vector__XXX
 SG_ TractorFrontLowWorkLightCmd : 44|2@1+ (1,0) [0|3] "" Vector__XXX
 SG_ TractorSideHighWorkLightCmd : 42|2@1+ (1,0) [0|3] "" Vector__XXX
 SG_ TractorSideLowWorkLightCmd : 40|2@1+ (1,0) [0|3] "" Vector__XXX
 SG_ TractorRearHighWorkLightCmd : 38|2@1+ (1,0) [0|3] "" Vector__XXX
 SG_ TractorRearLowWorkLightCmd : 36|2@1+ (1,0) [0|3] "" Vector__XXX
 SG_ TractorUndersideWorkLightCmd : 34|2@1+ (1,0) [0|3] "" Vector__XXX
 SG_ RearFogLightCmd : 32|2@1+ (1,0) [0|3] "" Vector__XXX
 SG_ TractorMarkerLightCmd : 30|2@1+ (1,0) [0|3] "" Vector__XXX
 SG_ ImplementMarkerLightCmd : 28|2@1+ (1,0) [0|3] "" Vector__XXX
 SG_ TractorClearanceLightCmd : 26|2@1+ (1,0) [0|3] "" Vector__XXX
 SG_ ImplementClearanceLightCmd : 24|2@1+ (1,0) [0|3] "" Vector__XXX
 SG_ LeftStopLightCmd : 22|2@1+ (1,0) [0|3] "" Vector__XXX
 SG_ RightStopLightCmd : 20|2@1+ (1,0) [0|3] "" Vector__XXX
 SG_ CentreStopLightCmd : 18|2@1+ (1,0) [0|3] "" Vector__XXX
 SG_ BackUpLightAndAlarmHornCmd : 16|2@1+ (1,0) [0|3] "" Vector__XXX
 SG_ LeftTurnSignalLightCmd : 14|2@1+ (1,0) [0|3] "" Vector__XXX
 SG_ RightTurnSignalLightCmd : 12|2@1+ (1,0) [0|3] "" Vector__XXX
 SG_ RotatingBeaconLightCmd : 10|2@1+ (1,0) [0|3] "" Vector__XXX
 SG_ TractorFrontFogLightCmd : 8|2@1+ (1,0) [0|3] "" Vector__XXX
 SG_ HighBeamHeadLightCmd : 6|2@1+ (1,0) [0|3] "" Vector__XXX
 SG_ LowBeamHeadLightCmd : 4|2@1+ (1,0) [0|3] "" Vector__XXX
 SG_ AlternateHeadLightCmd : 2|2@1+ (1,0) [0|3] "" Vector__XXX
 SG_ DaytimeRunningLightCmd : 0|2@1+ (1,0) [0|3] "" Vector__XXX

BO_ 2566799614 LID: 8 Vector__XXX
 SG_ ImplementRearWorkLightData : 62|2@1+ (1,0) [0|3] "" Vector__XXX
 SG_ ImplLeftFacingWorkLightData : 60|2@1+ (1,0) [0|3] "" Vector__XXX
 SG_ ImplRightFacingWorkLightData : 58|2@1+ (1,0) [0|3] "" Vector__XXX
 SG_ ImplementLeftForwardLightData : 54|2@1+ (1,0) [0|3] "" Vector__XXX
 SG_ ImplementRightForwardLightData : 52|2@1+ (1,0) [0|3] "" Vector__XXX
 SG_ ImplementOEMOption1LightData : 50|2@1+ (1,0) [0|3] "" Vector__XXX
 SG_ ImplementOEMOption2LightData : 48|2@1+ (1,0) [0|3] "" Vector__XXX
 SG_ TractorFrontHighWorkLightData : 46|2@1+ (1,0) [0|3] "" Vector__XXX
 SG_ TractorFrontLowWorkLightData : 44|2@1+ (1,0) [0|3] "" Vector__XXX
 SG_ TractorSideHighWorkLightData : 42|2@1+ (1,0) [0|3] "" Vector__XXX
 SG_ TractorSideLowWorkLightData : 40|2@1+ (1,0) [0|3] "" Vector__XXX
 SG_ TractorRearHighWorkLightData : 38|2@1+ (1,0) [0|3] "" Vector__XXX
 SG_ TractorRearLowWorkLightData : 36|2@1+ (1,0) [0|3] "" Vector__XXX
 SG_ TractorUndersideWorkLightData : 34|2@1+ (1,0) [0|3] "" Vector__XXX
 SG_ RearFogLightData : 32|2@1+ (1,0) [0|3] "" Vector__XXX
 SG_ TractorMarkerLightData : 30|2@1+ (1,0) [0|3] "" Vector__XXX
 SG_ ImplementMarkerLightData : 28|2@1+ (1,0) [0|3] "" Vector__XXX
 SG_ TractorClearanceLightData : 26|2@1+ (1,0) [0|3] "" Vector__XXX
 SG_ ImplementClearanceLightData : 24|2@1+ (1,0) [0|3] "" Vector__XXX
 SG_ LefttStopLightData : 22|2@1+ (1,0) [0|3] "" Vector__XXX
 SG_ RightStopLightData : 20|2@1+ (1,0) [0|3] "" Vector__XXX
 SG_ CentreStopLightData : 18|2@1+ (1,0) [0|3] "" Vector__XXX
 SG_ BackUpLightAndAlarmHornData : 16|2@1+ (1,0) [0|3] "" Vector__XXX
 SG_ LeftTurnSignalLightData : 14|2@1+ (1,0) [0|3] "" Vector__XXX
 SG_ RightTurnSignalLightData : 12|2@1+ (1,0) [0|3] "" Vector__XXX
 SG_ RotationBeaconLightData : 10|2@1+ (1,0) [0|3] "" Vector__XXX
 SG_ TractorFrontFogLightData : 8|2@1+ (1,0) [0|3] "" Vector__XXX
 SG_ HighBeamHeadLightData : 6|2@1+ (1,0) [0|3] "" Vector__XXX
 SG_ LowBeamHeadLightData : 4|2@1+ (1,0) [0|3] "" Vector__XXX
 SG_ AlternateHeadLightData : 2|2@1+ (1,0) [0|3] "" Vector__XXX
 SG_ DaytimeRunningLightData : 0|2@1+ (1,0) [0|3] "" Vector__XXX

BO_ 2365472766 AV15C: 8 Vector__XXX
 SG_ Valve15FailSaveModeCmd : 22|2@1+ (1,0) [0|3] "" Vector__XXX
 SG_ Valve15StateCmd : 16|4@1+ (1,0) [0|15] "" Vector__XXX
 SG_ Valve15PortFlowCmd : 0|8@1+ (0.4,0) [0|100] "%" Vector__XXX

BO_ 2365472510 AV14C: 8 Vector__XXX
 SG_ Valve14FailSaveModeCmd : 22|2@1+ (1,0) [0|3] "" Vector__XXX
 SG_ Valve14StateCmd : 16|4@1+ (1,0) [0|15] "" Vector__XXX
 SG_ Valve14PortFlowCmd : 0|8@1+ (0.4,0) [0|100] "%" Vector__XXX

BO_ 2365472254 AV13C: 8 Vector__XXX
 SG_ Valve13FailSaveModeCmd : 22|2@1+ (1,0) [0|3] "" Vector__XXX
 SG_ Valve13StateCmd : 16|4@1+ (1,0) [0|15] "" Vector__XXX
 SG_ Valve13PortFlowCmd : 0|8@1+ (0.4,0) [0|100] "%" Vector__XXX

BO_ 2365471998 AV12C: 8 Vector__XXX
 SG_ Valve12FailSaveModeCmd : 22|2@1+ (1,0) [0|3] "" Vector__XXX
 SG_ Valve12StateCmd : 16|4@1+ (1,0) [0|15] "" Vector__XXX
 SG_ Valve12PortFlowCmd : 0|8@1+ (0.4,0) [0|100] "%" Vector__XXX

BO_ 2365471742 AV11C: 8 Vector__XXX
 SG_ Valve11FailSaveModeCmd : 22|2@1+ (1,0) [0|3] "" Vector__XXX
 SG_ Valve11StateCmd : 16|4@1+ (1,0) [0|15] "" Vector__XXX
 SG_ Valve11PortFlowCmd : 0|8@1+ (0.4,0) [0|100] "%" Vector__XXX

BO_ 2365471486 AV10C: 8 Vector__XXX
 SG_ Valve10FailSaveModeCmd : 22|2@1+ (1,0) [0|3] "" Vector__XXX
 SG_ Valve10StateCmd : 16|4@1+ (1,0) [0|15] "" Vector__XXX
 SG_ Valve10PortFlowCmd : 0|8@1+ (0.4,0) [0|100] "%" Vector__XXX

BO_ 2365471230 AV09C: 8 Vector__XXX
 SG_ Valve9FailSaveModeCmd : 22|2@1+ (1,0) [0|3] "" Vector__XXX
 SG_ Valve9StateCmd : 16|4@1+ (1,0) [0|15] "" Vector__XXX
 SG_ Valve9PortFlowCmd : 0|8@1+ (0.4,0) [0|100] "%" Vector__XXX

BO_ 2365470974 AV08C: 8 Vector__XXX
 SG_ Valve8FailSaveModeCmd : 22|2@1+ (1,0) [0|3] "" Vector__XXX
 SG_ Valve8StateCmd : 16|4@1+ (1,0) [0|15] "" Vector__XXX
 SG_ Valve8PortFlowCmd : 0|8@1+ (0.4,0) [0|100] "%" Vector__XXX

BO_ 2365470718 AV07C: 8 Vector__XXX
 SG_ Valve7FailSaveModeCmd : 22|2@1+ (1,0) [0|3] "" Vector__XXX
 SG_ Valve7StateCmd : 16|4@1+ (1,0) [0|15] "" Vector__XXX
 SG_ Valve7PortFlowCmd : 0|8@1+ (0.4,0) [0|100] "%" Vector__XXX

BO_ 2365470462 AV06C: 8 Vector__XXX
 SG_ Valve6FailSaveModeCmd : 22|2@1+ (1,0) [0|3] "" Vector__XXX
 SG_ Valve6StateCmd : 16|4@1+ (1,0) [0|15] "" Vector__XXX
 SG_ Valve6PortFlowCmd : 0|8@1+ (0.4,0) [0|100] "%" Vector__XXX

BO_ 2365470206 AV05C: 8 Vector__XXX
 SG_ Valve5FailSaveModeCmd : 22|2@1+ (1,0) [0|3] "" Vector__XXX
 SG_ Valve5StateCmd : 16|4@1+ (1,0) [0|15] "" Vector__XXX
 SG_ Valve5PortFlowCmd : 0|8@1+ (0.4,0) [0|100] "%" Vector__XXX

BO_ 2365469950 AV04C: 8 Vector__XXX
 SG_ Valve4FailSaveModeCmd : 22|2@1+ (1,0) [0|3] "" Vector__XXX
 SG_ Valve4StateCmd : 16|4@1+ (1,0) [0|15] "" Vector__XXX
 SG_ Valve4PortFlowCmd : 0|8@1+ (0.4,0) [0|100] "%" Vector__XXX

BO_ 2365469694 AV03C: 8 Vector__XXX
 SG_ Valve3FailSaveModeCmd : 22|2@1+ (1,0) [0|3] "" Vector__XXX
 SG_ Valve3StateCmd : 16|4@1+ (1,0) [0|15] "" Vector__XXX
 SG_ Valve3PortFlowCmd : 0|8@1+ (0.4,0) [0|100] "%" Vector__XXX

BO_ 2365469438 AV02C: 8 Vector__XXX
 SG_ Valve2FailSaveModeCmd : 22|2@1+ (1,0) [0|3] "" Vector__XXX
 SG_ Valve2StateCmd : 16|4@1+ (1,0) [0|15] "" Vector__XXX
 SG_ Valve2PortFlowCmd : 0|8@1+ (0.4,0) [0|100] "%" Vector__XXX

BO_ 2365469182 AV01C: 8 Vector__XXX
 SG_ Valve1FailSaveModeCmd : 22|2@1+ (1,0) [0|3] "" Vector__XXX
 SG_ Valve1StateCmd : 16|4@1+ (1,0) [0|15] "" Vector__XXX
 SG_ Valve1PortFlowCmd : 0|8@1+ (0.4,0) [0|100] "%" Vector__XXX

BO_ 2365468926 AV00C: 8 Vector__XXX
 SG_ Valve0FailSaveModeCmd : 22|2@1+ (1,0) [0|3] "" Vector__XXX
 SG_ Valve0StateCmd : 16|4@1+ (1,0) [0|15] "" Vector__XXX
 SG_ Valve0PortFlowCmd : 0|8@1+ (0.4,0) [0|100] "%" Vector__XXX

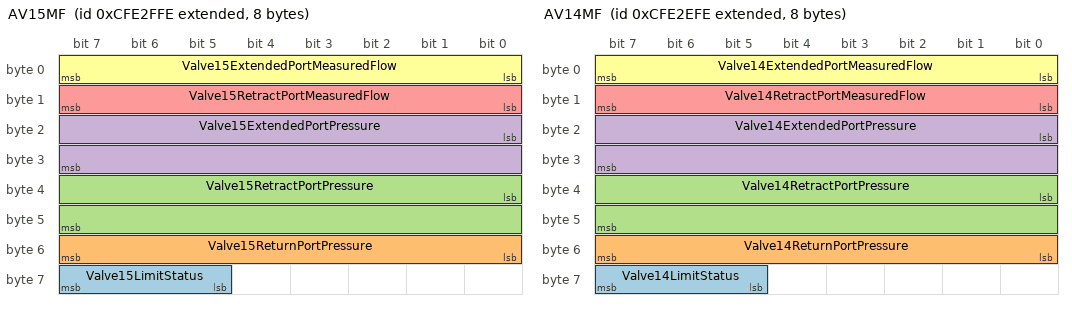
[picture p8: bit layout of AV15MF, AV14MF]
BO_ 2365468670 AV15MF: 8 Vector__XXX
 SG_ Valve15LimitStatus : 61|3@1+ (1,0) [0|7] "" Vector__XXX
 SG_ Valve15ReturnPortPressure : 48|8@1+ (16,0) [0|4000] "kPa" Vector__XXX
 SG_ Valve15RetractPortPressure : 32|16@1+ (5,0) [0|321275] "kPa" Vector__XXX
 SG_ Valve15ExtendedPortPressure : 16|16@1+ (5,0) [0|321275] "kPa" Vector__XXX
 SG_ Valve15RetractPortMeasuredFlow : 8|8@1+ (1,-125) [-125|125] "%" Vector__XXX
 SG_ Valve15ExtendedPortMeasuredFlow : 0|8@1+ (1,-125) [-125|125] "%" Vector__XXX

BO_ 2365468414 AV14MF: 8 Vector__XXX
 SG_ Valve14LimitStatus : 61|3@1+ (1,0) [0|7] "" Vector__XXX
 SG_ Valve14ReturnPortPressure : 48|8@1+ (16,0) [0|4000] "kPa" Vector__XXX
 SG_ Valve14RetractPortPressure : 32|16@1+ (5,0) [0|321275] "kPa" Vector__XXX
 SG_ Valve14ExtendedPortPressure : 16|16@1+ (5,0) [0|321275] "kPa" Vector__XXX
 SG_ Valve14RetractPortMeasuredFlow : 8|8@1+ (1,-125) [-125|125] "%" Vector__XXX
 SG_ Valve14ExtendedPortMeasuredFlow : 0|8@1+ (1,-125) [-125|125] "%" Vector__XXX

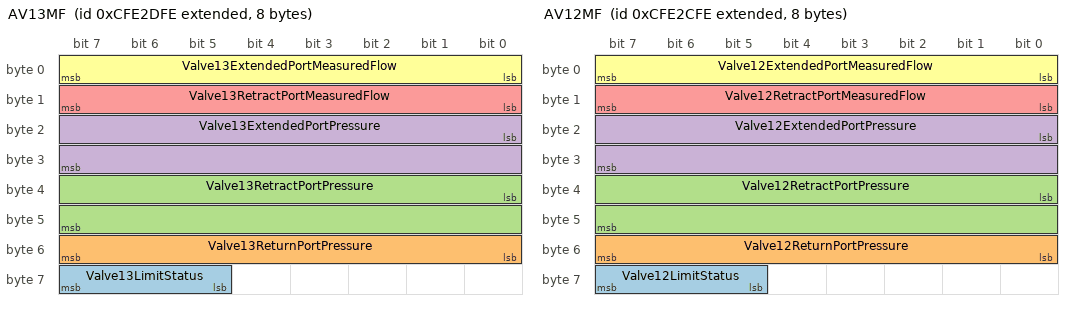
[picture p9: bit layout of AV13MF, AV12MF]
BO_ 2365468158 AV13MF: 8 Vector__XXX
 SG_ Valve13LimitStatus : 61|3@1+ (1,0) [0|7] "" Vector__XXX
 SG_ Valve13ReturnPortPressure : 48|8@1+ (16,0) [0|4000] "kPa" Vector__XXX
 SG_ Valve13RetractPortPressure : 32|16@1+ (5,0) [0|321275] "kPa" Vector__XXX
 SG_ Valve13ExtendedPortPressure : 16|16@1+ (5,0) [0|321275] "kPa" Vector__XXX
 SG_ Valve13RetractPortMeasuredFlow : 8|8@1+ (1,-125) [-125|125] "%" Vector__XXX
 SG_ Valve13ExtendedPortMeasuredFlow : 0|8@1+ (1,-125) [-125|125] "%" Vector__XXX

BO_ 2365467902 AV12MF: 8 Vector__XXX
 SG_ Valve12LimitStatus : 61|3@1+ (1,0) [0|7] "" Vector__XXX
 SG_ Valve12ReturnPortPressure : 48|8@1+ (16,0) [0|4000] "kPa" Vector__XXX
 SG_ Valve12RetractPortPressure : 32|16@1+ (5,0) [0|321275] "kPa" Vector__XXX
 SG_ Valve12ExtendedPortPressure : 16|16@1+ (5,0) [0|321275] "kPa" Vector__XXX
 SG_ Valve12RetractPortMeasuredFlow : 8|8@1+ (1,-125) [-125|125] "%" Vector__XXX
 SG_ Valve12ExtendedPortMeasuredFlow : 0|8@1+ (1,-125) [-125|125] "%" Vector__XXX

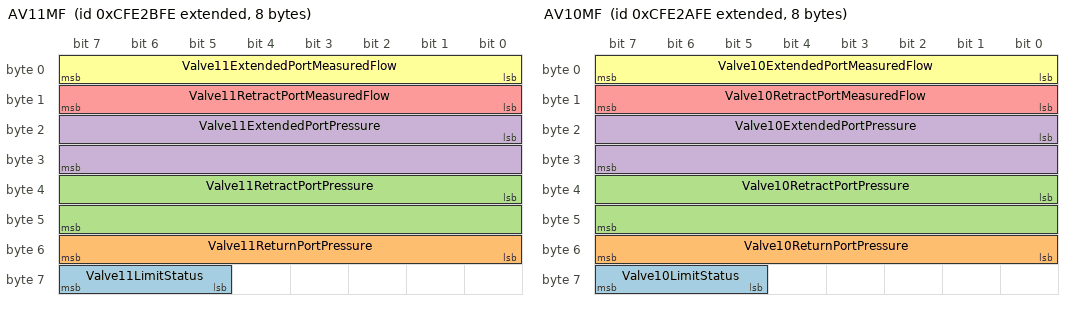
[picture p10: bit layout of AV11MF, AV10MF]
BO_ 2365467646 AV11MF: 8 Vector__XXX
 SG_ Valve11LimitStatus : 61|3@1+ (1,0) [0|7] "" Vector__XXX
 SG_ Valve11ReturnPortPressure : 48|8@1+ (16,0) [0|4000] "kPa" Vector__XXX
 SG_ Valve11RetractPortPressure : 32|16@1+ (5,0) [0|321275] "kPa" Vector__XXX
 SG_ Valve11ExtendedPortPressure : 16|16@1+ (5,0) [0|321275] "kPa" Vector__XXX
 SG_ Valve11RetractPortMeasuredFlow : 8|8@1+ (1,-125) [-125|125] "%" Vector__XXX
 SG_ Valve11ExtendedPortMeasuredFlow : 0|8@1+ (1,-125) [-125|125] "%" Vector__XXX

BO_ 2365467390 AV10MF: 8 Vector__XXX
 SG_ Valve10LimitStatus : 61|3@1+ (1,0) [0|7] "" Vector__XXX
 SG_ Valve10ReturnPortPressure : 48|8@1+ (16,0) [0|4000] "kPa" Vector__XXX
 SG_ Valve10RetractPortPressure : 32|16@1+ (5,0) [0|321275] "kPa" Vector__XXX
 SG_ Valve10ExtendedPortPressure : 16|16@1+ (5,0) [0|321275] "kPa" Vector__XXX
 SG_ Valve10RetractPortMeasuredFlow : 8|8@1+ (1,-125) [-125|125] "%" Vector__XXX
 SG_ Valve10ExtendedPortMeasuredFlow : 0|8@1+ (1,-125) [-125|125] "%" Vector__XXX

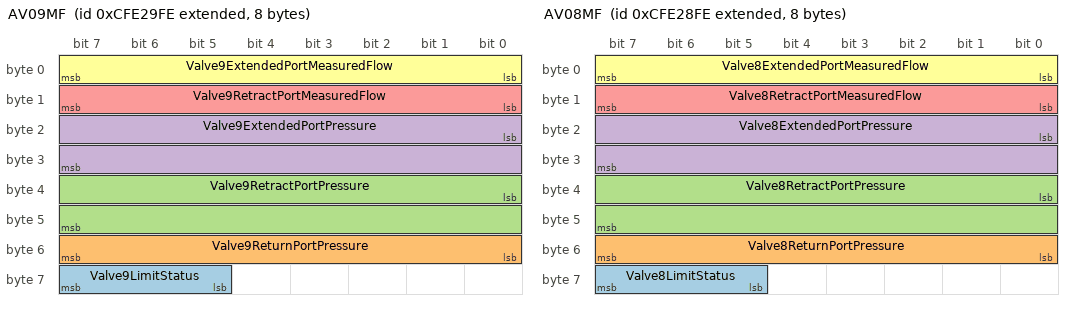
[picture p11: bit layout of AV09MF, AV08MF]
BO_ 2365467134 AV09MF: 8 Vector__XXX
 SG_ Valve9LimitStatus : 61|3@1+ (1,0) [0|7] "" Vector__XXX
 SG_ Valve9ReturnPortPressure : 48|8@1+ (16,0) [0|4000] "kPa" Vector__XXX
 SG_ Valve9RetractPortPressure : 32|16@1+ (5,0) [0|321275] "kPa" Vector__XXX
 SG_ Valve9ExtendedPortPressure : 16|16@1+ (5,0) [0|321275] "kPa" Vector__XXX
 SG_ Valve9RetractPortMeasuredFlow : 8|8@1+ (1,-125) [-125|125] "%" Vector__XXX
 SG_ Valve9ExtendedPortMeasuredFlow : 0|8@1+ (1,-125) [-125|125] "%" Vector__XXX

BO_ 2365466878 AV08MF: 8 Vector__XXX
 SG_ Valve8LimitStatus : 61|3@1+ (1,0) [0|7] "" Vector__XXX
 SG_ Valve8ReturnPortPressure : 48|8@1+ (16,0) [0|4000] "kPa" Vector__XXX
 SG_ Valve8RetractPortPressure : 32|16@1+ (5,0) [0|321275] "kPa" Vector__XXX
 SG_ Valve8ExtendedPortPressure : 16|16@1+ (5,0) [0|321275] "kPa" Vector__XXX
 SG_ Valve8RetractPortMeasuredFlow : 8|8@1+ (1,-125) [-125|125] "%" Vector__XXX
 SG_ Valve8ExtendedPortMeasuredFlow : 0|8@1+ (1,-125) [-125|125] "%" Vector__XXX

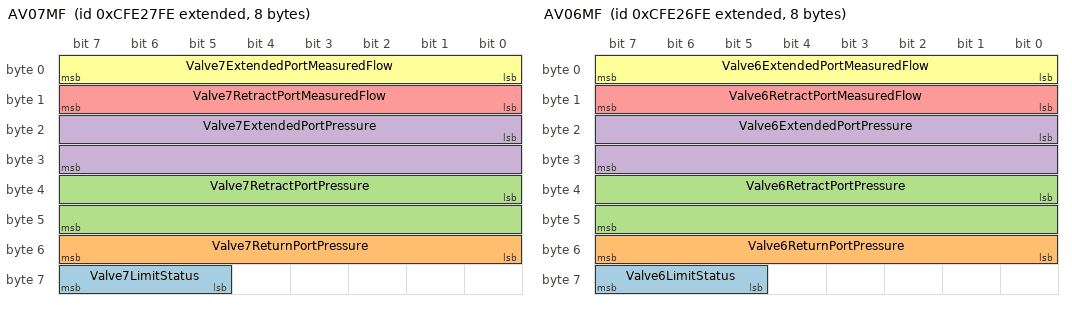
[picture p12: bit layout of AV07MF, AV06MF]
BO_ 2365466622 AV07MF: 8 Vector__XXX
 SG_ Valve7LimitStatus : 61|3@1+ (1,0) [0|7] "" Vector__XXX
 SG_ Valve7ReturnPortPressure : 48|8@1+ (16,0) [0|4000] "kPa" Vector__XXX
 SG_ Valve7RetractPortPressure : 32|16@1+ (5,0) [0|321275] "kPa" Vector__XXX
 SG_ Valve7ExtendedPortPressure : 16|16@1+ (5,0) [0|321275] "kPa" Vector__XXX
 SG_ Valve7RetractPortMeasuredFlow : 8|8@1+ (1,-125) [-125|125] "%" Vector__XXX
 SG_ Valve7ExtendedPortMeasuredFlow : 0|8@1+ (1,-125) [-125|125] "%" Vector__XXX

BO_ 2365466366 AV06MF: 8 Vector__XXX
 SG_ Valve6LimitStatus : 61|3@1+ (1,0) [0|7] "" Vector__XXX
 SG_ Valve6ReturnPortPressure : 48|8@1+ (16,0) [0|4000] "kPa" Vector__XXX
 SG_ Valve6RetractPortPressure : 32|16@1+ (5,0) [0|321275] "kPa" Vector__XXX
 SG_ Valve6ExtendedPortPressure : 16|16@1+ (5,0) [0|321275] "kPa" Vector__XXX
 SG_ Valve6RetractPortMeasuredFlow : 8|8@1+ (1,-125) [-125|125] "%" Vector__XXX
 SG_ Valve6ExtendedPortMeasuredFlow : 0|8@1+ (1,-125) [-125|125] "%" Vector__XXX

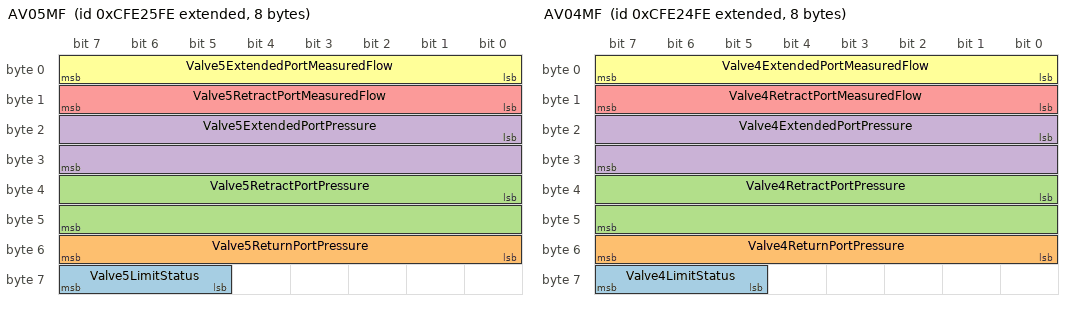
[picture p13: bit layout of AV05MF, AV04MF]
BO_ 2365466110 AV05MF: 8 Vector__XXX
 SG_ Valve5LimitStatus : 61|3@1+ (1,0) [0|7] "" Vector__XXX
 SG_ Valve5ReturnPortPressure : 48|8@1+ (16,0) [0|4000] "kPa" Vector__XXX
 SG_ Valve5RetractPortPressure : 32|16@1+ (5,0) [0|321275] "kPa" Vector__XXX
 SG_ Valve5ExtendedPortPressure : 16|16@1+ (5,0) [0|321275] "kPa" Vector__XXX
 SG_ Valve5RetractPortMeasuredFlow : 8|8@1+ (1,-125) [-125|125] "%" Vector__XXX
 SG_ Valve5ExtendedPortMeasuredFlow : 0|8@1+ (1,-125) [-125|125] "%" Vector__XXX

BO_ 2365465854 AV04MF: 8 Vector__XXX
 SG_ Valve4LimitStatus : 61|3@1+ (1,0) [0|7] "" Vector__XXX
 SG_ Valve4ReturnPortPressure : 48|8@1+ (16,0) [0|4000] "kPa" Vector__XXX
 SG_ Valve4RetractPortPressure : 32|16@1+ (5,0) [0|321275] "kPa" Vector__XXX
 SG_ Valve4ExtendedPortPressure : 16|16@1+ (5,0) [0|321275] "kPa" Vector__XXX
 SG_ Valve4RetractPortMeasuredFlow : 8|8@1+ (1,-125) [-125|125] "%" Vector__XXX
 SG_ Valve4ExtendedPortMeasuredFlow : 0|8@1+ (1,-125) [-125|125] "%" Vector__XXX

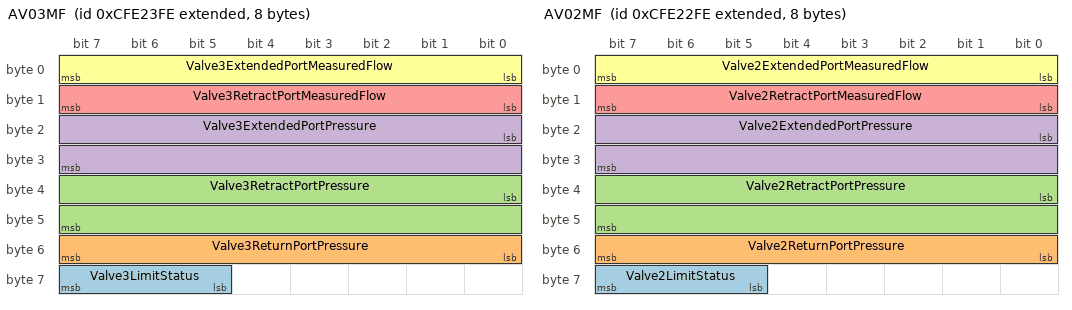
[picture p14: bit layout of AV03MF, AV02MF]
BO_ 2365465598 AV03MF: 8 Vector__XXX
 SG_ Valve3LimitStatus : 61|3@1+ (1,0) [0|7] "" Vector__XXX
 SG_ Valve3ReturnPortPressure : 48|8@1+ (16,0) [0|4000] "kPa" Vector__XXX
 SG_ Valve3RetractPortPressure : 32|16@1+ (5,0) [0|321275] "kPa" Vector__XXX
 SG_ Valve3ExtendedPortPressure : 16|16@1+ (5,0) [0|321275] "kPa" Vector__XXX
 SG_ Valve3RetractPortMeasuredFlow : 8|8@1+ (1,-125) [-125|125] "%" Vector__XXX
 SG_ Valve3ExtendedPortMeasuredFlow : 0|8@1+ (1,-125) [-125|125] "%" Vector__XXX

BO_ 2365465342 AV02MF: 8 Vector__XXX
 SG_ Valve2LimitStatus : 61|3@1+ (1,0) [0|7] "" Vector__XXX
 SG_ Valve2ReturnPortPressure : 48|8@1+ (16,0) [0|4000] "kPa" Vector__XXX
 SG_ Valve2RetractPortPressure : 32|16@1+ (5,0) [0|321275] "kPa" Vector__XXX
 SG_ Valve2ExtendedPortPressure : 16|16@1+ (5,0) [0|321275] "kPa" Vector__XXX
 SG_ Valve2RetractPortMeasuredFlow : 8|8@1+ (1,-125) [-125|125] "%" Vector__XXX
 SG_ Valve2ExtendedPortMeasuredFlow : 0|8@1+ (1,-125) [-125|125] "%" Vector__XXX

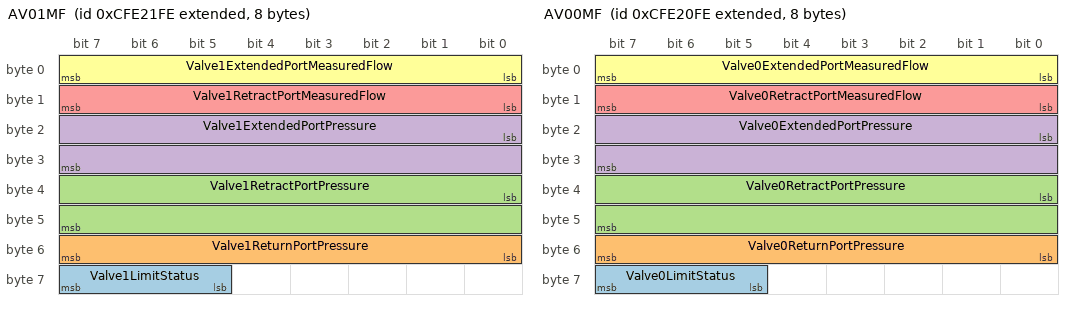
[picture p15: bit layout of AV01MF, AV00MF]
BO_ 2365465086 AV01MF: 8 Vector__XXX
 SG_ Valve1LimitStatus : 61|3@1+ (1,0) [0|7] "" Vector__XXX
 SG_ Valve1ReturnPortPressure : 48|8@1+ (16,0) [0|4000] "kPa" Vector__XXX
 SG_ Valve1RetractPortPressure : 32|16@1+ (5,0) [0|321275] "kPa" Vector__XXX
 SG_ Valve1ExtendedPortPressure : 16|16@1+ (5,0) [0|321275] "kPa" Vector__XXX
 SG_ Valve1RetractPortMeasuredFlow : 8|8@1+ (1,-125) [-125|125] "%" Vector__XXX
 SG_ Valve1ExtendedPortMeasuredFlow : 0|8@1+ (1,-125) [-125|125] "%" Vector__XXX

BO_ 2365464830 AV00MF: 8 Vector__XXX
 SG_ Valve0LimitStatus : 61|3@1+ (1,0) [0|7] "" Vector__XXX
 SG_ Valve0ReturnPortPressure : 48|8@1+ (16,0) [0|4000] "kPa" Vector__XXX
 SG_ Valve0RetractPortPressure : 32|16@1+ (5,0) [0|321275] "kPa" Vector__XXX
 SG_ Valve0ExtendedPortPressure : 16|16@1+ (5,0) [0|321275] "kPa" Vector__XXX
 SG_ Valve0RetractPortMeasuredFlow : 8|8@1+ (1,-125) [-125|125] "%" Vector__XXX
 SG_ Valve0ExtendedPortMeasuredFlow : 0|8@1+ (1,-125) [-125|125] "%" Vector__XXX

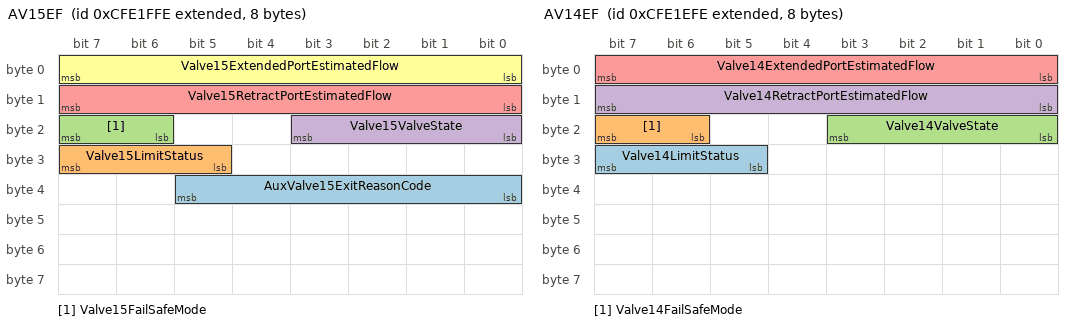
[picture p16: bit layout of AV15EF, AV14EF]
BO_ 2365464574 AV15EF: 8 Vector__XXX
 SG_ AuxValve15ExitReasonCode : 32|6@1+ (1,0) [0|63] "" Vector__XXX
 SG_ Valve15LimitStatus : 29|3@1+ (1,0) [0|7] "" Vector__XXX
 SG_ Valve15FailSafeMode : 22|2@1+ (1,0) [0|3] "" Vector__XXX
 SG_ Valve15ValveState : 16|4@1+ (1,0) [0|15] "" Vector__XXX
 SG_ Valve15RetractPortEstimatedFlow : 8|8@1+ (1,-125) [-125|125] "%" Vector__XXX
 SG_ Valve15ExtendedPortEstimatedFlow : 0|8@1+ (1,-125) [-125|125] "%" Vector__XXX

BO_ 2365464318 AV14EF: 8 Vector__XXX
 SG_ Valve14LimitStatus : 29|3@1+ (1,0) [0|7] "" Vector__XXX
 SG_ Valve14FailSafeMode : 22|2@1+ (1,0) [0|3] "" Vector__XXX
 SG_ Valve14ValveState : 16|4@1+ (1,0) [0|15] "" Vector__XXX
 SG_ Valve14RetractPortEstimatedFlow : 8|8@1+ (1,-125) [-125|125] "%" Vector__XXX
 SG_ Valve14ExtendedPortEstimatedFlow : 0|8@1+ (1,-125) [-125|125] "%" Vector__XXX

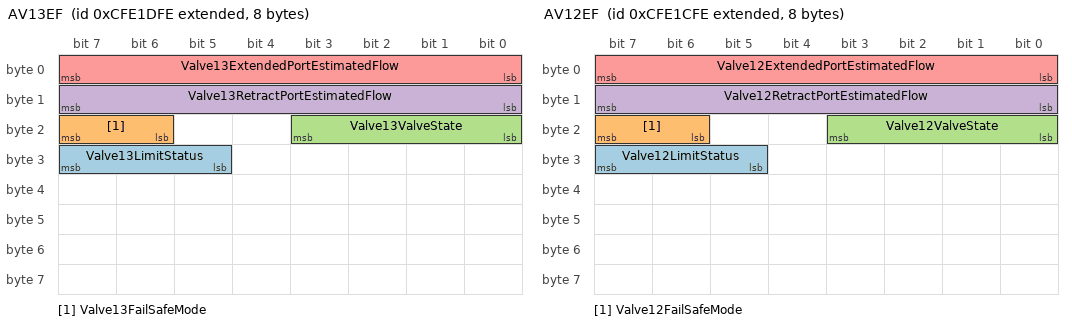
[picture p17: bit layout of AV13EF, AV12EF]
BO_ 2365464062 AV13EF: 8 Vector__XXX
 SG_ Valve13LimitStatus : 29|3@1+ (1,0) [0|7] "" Vector__XXX
 SG_ Valve13FailSafeMode : 22|2@1+ (1,0) [0|3] "" Vector__XXX
 SG_ Valve13ValveState : 16|4@1+ (1,0) [0|15] "" Vector__XXX
 SG_ Valve13RetractPortEstimatedFlow : 8|8@1+ (1,-125) [-125|125] "%" Vector__XXX
 SG_ Valve13ExtendedPortEstimatedFlow : 0|8@1+ (1,-125) [-125|125] "%" Vector__XXX

BO_ 2365463806 AV12EF: 8 Vector__XXX
 SG_ Valve12LimitStatus : 29|3@1+ (1,0) [0|7] "" Vector__XXX
 SG_ Valve12FailSafeMode : 22|2@1+ (1,0) [0|3] "" Vector__XXX
 SG_ Valve12ValveState : 16|4@1+ (1,0) [0|15] "" Vector__XXX
 SG_ Valve12RetractPortEstimatedFlow : 8|8@1+ (1,-125) [-125|125] "%" Vector__XXX
 SG_ Valve12ExtendedPortEstimatedFlow : 0|8@1+ (1,-125) [-125|125] "%" Vector__XXX

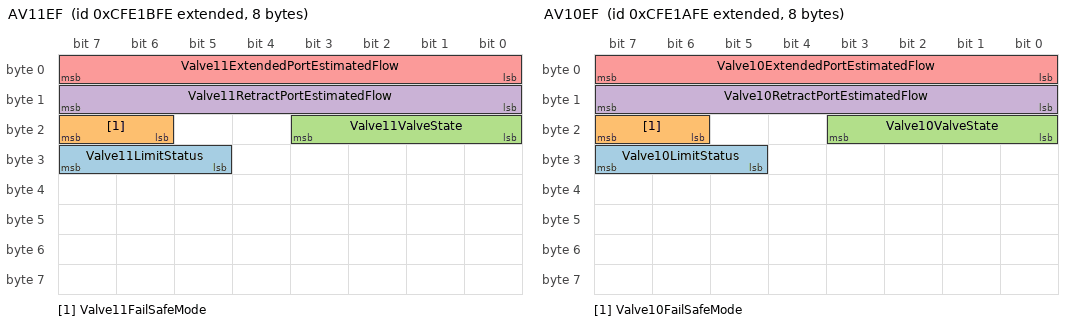
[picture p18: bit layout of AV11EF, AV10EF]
BO_ 2365463550 AV11EF: 8 Vector__XXX
 SG_ Valve11LimitStatus : 29|3@1+ (1,0) [0|7] "" Vector__XXX
 SG_ Valve11FailSafeMode : 22|2@1+ (1,0) [0|3] "" Vector__XXX
 SG_ Valve11ValveState : 16|4@1+ (1,0) [0|15] "" Vector__XXX
 SG_ Valve11RetractPortEstimatedFlow : 8|8@1+ (1,-125) [-125|125] "%" Vector__XXX
 SG_ Valve11ExtendedPortEstimatedFlow : 0|8@1+ (1,-125) [-125|125] "%" Vector__XXX

BO_ 2365463294 AV10EF: 8 Vector__XXX
 SG_ Valve10LimitStatus : 29|3@1+ (1,0) [0|7] "" Vector__XXX
 SG_ Valve10FailSafeMode : 22|2@1+ (1,0) [0|3] "" Vector__XXX
 SG_ Valve10ValveState : 16|4@1+ (1,0) [0|15] "" Vector__XXX
 SG_ Valve10RetractPortEstimatedFlow : 8|8@1+ (1,-125) [-125|125] "%" Vector__XXX
 SG_ Valve10ExtendedPortEstimatedFlow : 0|8@1+ (1,-125) [-125|125] "%" Vector__XXX

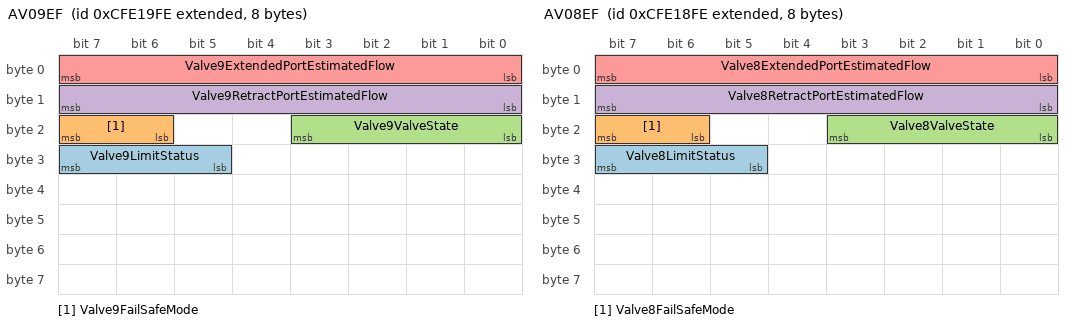
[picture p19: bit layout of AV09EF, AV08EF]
BO_ 2365463038 AV09EF: 8 Vector__XXX
 SG_ Valve9LimitStatus : 29|3@1+ (1,0) [0|7] "" Vector__XXX
 SG_ Valve9FailSafeMode : 22|2@1+ (1,0) [0|3] "" Vector__XXX
 SG_ Valve9ValveState : 16|4@1+ (1,0) [0|15] "" Vector__XXX
 SG_ Valve9RetractPortEstimatedFlow : 8|8@1+ (1,-125) [-125|125] "%" Vector__XXX
 SG_ Valve9ExtendedPortEstimatedFlow : 0|8@1+ (1,-125) [-125|125] "%" Vector__XXX

BO_ 2365462782 AV08EF: 8 Vector__XXX
 SG_ Valve8LimitStatus : 29|3@1+ (1,0) [0|7] "" Vector__XXX
 SG_ Valve8FailSafeMode : 22|2@1+ (1,0) [0|3] "" Vector__XXX
 SG_ Valve8ValveState : 16|4@1+ (1,0) [0|15] "" Vector__XXX
 SG_ Valve8RetractPortEstimatedFlow : 8|8@1+ (1,-125) [-125|125] "%" Vector__XXX
 SG_ Valve8ExtendedPortEstimatedFlow : 0|8@1+ (1,-125) [-125|125] "%" Vector__XXX

BO_ 2365462526 AV07EF: 8 Vector__XXX
 SG_ Valve7LimitStatus : 29|3@1+ (1,0) [0|7] "" Vector__XXX
 SG_ Valve7FailSafeMode : 22|2@1+ (1,0) [0|3] "" Vector__XXX
 SG_ Valve7ValveState : 16|4@1+ (1,0) [0|15] "" Vector__XXX
 SG_ Valve7RetractPortEstimatedFlow : 8|8@1+ (1,-125) [-125|125] "%" Vector__XXX
 SG_ Valve7ExtendedPortEstimatedFlow : 0|8@1+ (1,-125) [-125|125] "%" Vector__XXX

BO_ 2365462270 AV06EF: 8 Vector__XXX
 SG_ Valve6LimitStatus : 29|3@1+ (1,0) [0|7] "" Vector__XXX
 SG_ Valve6FailSafeMode : 22|2@1+ (1,0) [0|3] "" Vector__XXX
 SG_ Valve6ValveState : 16|4@1+ (1,0) [0|15] "" Vector__XXX
 SG_ Valve6RetractPortEstimatedFlow : 8|8@1+ (1,-125) [-125|125] "%" Vector__XXX
 SG_ Valve6ExtendedPortEstimatedFlow : 0|8@1+ (1,-125) [-125|125] "%" Vector__XXX

BO_ 2365462014 AV05EF: 8 Vector__XXX
 SG_ Valve5LimitStatus : 29|3@1+ (1,0) [0|7] "" Vector__XXX
 SG_ Valve5FailSafeMode : 22|2@1+ (1,0) [0|3] "" Vector__XXX
 SG_ Valve5ValveState : 16|4@1+ (1,0) [0|15] "" Vector__XXX
 SG_ Valve5RetractPortEstimatedFlow : 8|8@1+ (1,-125) [-125|125] "%" Vector__XXX
 SG_ Valve5ExtendedPortEstimatedFlow : 0|8@1+ (1,-125) [-125|125] "%" Vector__XXX

BO_ 2365461758 AV04EF: 8 Vector__XXX
 SG_ Valve4LimitStatus : 29|3@1+ (1,0) [0|7] "" Vector__XXX
 SG_ Valve4FailSafeMode : 22|2@1+ (1,0) [0|3] "" Vector__XXX
 SG_ Valve4ValveState : 16|4@1+ (1,0) [0|15] "" Vector__XXX
 SG_ Valve4RetractPortEstimatedFlow : 8|8@1+ (1,-125) [-125|125] "%" Vector__XXX
 SG_ Valve4ExtendedPortEstimatedFlow : 0|8@1+ (1,-125) [-125|125] "%" Vector__XXX

BO_ 2365461502 AV03EF: 8 Vector__XXX
 SG_ Valve3LimitStatus : 29|3@1+ (1,0) [0|7] "" Vector__XXX
 SG_ Valve3FailSafeMode : 22|2@1+ (1,0) [0|3] "" Vector__XXX
 SG_ Valve3ValveState : 16|4@1+ (1,0) [0|15] "" Vector__XXX
 SG_ Valve3RetractPortEstimatedFlow : 8|8@1+ (1,-125) [-125|125] "%" Vector__XXX
 SG_ Valve3ExtendedPortEstimatedFlow : 0|8@1+ (1,-125) [-125|125] "%" Vector__XXX

BO_ 2365461246 AV02EF: 8 Vector__XXX
 SG_ Valve2LimitStatus : 29|3@1+ (1,0) [0|7] "" Vector__XXX
 SG_ Valve2FailSafeMode : 22|2@1+ (1,0) [0|3] "" Vector__XXX
 SG_ Valve2ValveState : 16|4@1+ (1,0) [0|15] "" Vector__XXX
 SG_ Valve2RetractPortEstimatedFlow : 8|8@1+ (1,-125) [-125|125] "%" Vector__XXX
 SG_ Valve2ExtendedPortEstimatedFlow : 0|8@1+ (1,-125) [-125|125] "%" Vector__XXX

CM_ BO_ 2624585470 "TIM message: Authentication client to Authentication server";
CM_ BO_ 2624651006 "TIM message: Authentication server to Authentication client";
CM_ BO_ 2619670270 "TIM message: TIM client to TIM server";
CM_ BO_ 2619604734 "TIM message: TIM server to TIM client";
CM_ BO_ 2314732542 "This PGN is intended for applications where very high precision and very fast update rates are needed for position data 
and only has meaning when it is associated (via the Sequence ID field) with another PGN.";
CM_ SG_ 2314732542 SequenceID "An upward counting number used to tie related information together between different PGNs.";
CM_ BO_ 2360147710 "Guidance Machine Status: It provides information and status from the steering control system to the guidance system.";
CM_ SG_ 2360147710 GuidSysComExitReasonCode "Parameter used to indicate why the guidance system cannot currently accept remote commands or has most 
recently stopped accepting remote commands. ";
CM_ SG_ 2360147710 GuidanceLimitStatus "Parameter used to report the Tractor ECU's present limit status associated with guidance commands that are 
persistent (i.e. not transient/temporary/one-shot). ";
CM_ SG_ 2360147710 RequestResetCommandStatus "The machine steering system request to the automatic guidance system to change Curvature Command Status state.";
CM_ SG_ 2360147710 SteeringInputPositionStatus "The machine steering system indicates if manual steering is in correct position for guidance to function.";
CM_ SG_ 2360147710 SteeringSystemReadiness "The machine steering system indicates that it is free from faults that would preclude guidance system operation.";
CM_ SG_ 2360147710 MechanicalSystemLockout "The state of a lockout switch that allows operators to disable automatic steering system functions.";
CM_ SG_ 2360147710 EstimatedCurvature "The machine steering system's estimate of the curvature of the current turn.";
CM_ BO_ 2360213246 "Guidance System Command";
CM_ SG_ 2360213246 CurvatureCommandStatus "This parameter indicates whether the guidance system is attempting to control steering with this command.";
CM_ SG_ 2360213246 CurvatureCommand "Desired course curvature over ground that a machine's steering system is required to achieve.";
CM_ BO_ 2563047166 "General Purpose valve command";
CM_ BO_ 2563112702 "General Purpose valve measured flow";
CM_ SG_ 2563112702 ValveLimitStatus "Parameter used to report the tractor ECUs present limit status associated with a parameter whose commands are persistent";
CM_ BO_ 2563178238 "General purpose valve estimated flow";
CM_ SG_ 2563178238 ValveLimitStatus "Parameter used to report the tractor ECUs present limit status associated with a parameter whose commands are persistent";
CM_ BO_ 2628452094 "Client (ECU) to File Server message";
CM_ SG_ 2628452094 SA_ATTR_SupportsLongFilenames "SetFile Attribute 'Volume supports long filenames'";
CM_ SG_ 2628452094 SA_ATTR_VolumeSupportsHidden "SetFile Attribute 'Volume supports hidden attribute'";
CM_ SG_ 2628452094 SA_ATTR_VolumeIsRemovable "SetFile Attribute 'Volume is not removable'";
CM_ SG_ 2628452094 SA_ATTR_VolumeIsCaseSensitive "SetFile Attribute 'Volume is case-sensitive'";
CM_ SG_ 2628452094 SA_ATTR_IsVolume "SetFile Attribute 'Handle specifies a volume'";
CM_ SG_ 2628452094 SA_ATTR_IsDirectory "SetFile Attribute 'Handle specifies a directory'";
CM_ SG_ 2628452094 VI_VolumeName "Length of path name string for Initailize Volume Request";
CM_ SG_ 2628452094 VI_Flag_OverwriteExisting "Create a new volume if not yet existing (fails if existing volume)";
CM_ SG_ 2628452094 MF_DestinationPathNameLength "Length of destination path name string for Move File";
CM_ SG_ 2628452094 RF_ReportHiddenFiles "Report Hidden Files";
CM_ SG_ 2628452094 SF_Offset "Offset for Seek File";
CM_ SG_ 2628452094 RF_Count "Number of bytes or number of directory entries to be read";
CM_ SG_ 2628452094 SF_PositionMode "Position Mode for Seek File";
CM_ SG_ 2628452094 OF_PathName "Length of path name string for Open File";
CM_ SG_ 2628452094 MF_SourcePathNameLength "Length of source path name string for Move File";
CM_ SG_ 2628452094 WF_Count "Byte count of data to be written to file";
CM_ SG_ 2628452094 DF_PathName "Length of path name string for Delete File";
CM_ SG_ 2628452094 SA_PathName "Length of path name string for Set File Attributes";
CM_ SG_ 2628452094 VI_Space "The space in units of 512";
CM_ SG_ 2628452094 OF_FlagExclusiveAccess "Open file with exclusive access (fails if already open)";
CM_ SG_ 2628452094 OF_FlagAppend "Open file for appending data to the end of the file";
CM_ SG_ 2628452094 SA_ATTR_Hidden "SetFile Attribute 'Hidden'";
CM_ SG_ 2628452094 OF_FlagCreateNew "Create a new file if not yet existing";
CM_ SG_ 2628452094 MF_MoveModeRecursive "Recursive mode for Move File";
CM_ SG_ 2628452094 DF_DeleteModeRecursive "Recursive mode for Move File";
CM_ SG_ 2628452094 MF_MoveModeForce "Force mode for Move File";
CM_ SG_ 2628452094 DF_DeleteModeForce "Force mode for Move File";
CM_ SG_ 2628452094 VI_Flag_UsingSpaceSpecified "Create volume using space specified";
CM_ SG_ 2628452094 SA_ATTR_ReadOnly "SetFile Attribute Read-Only";
CM_ SG_ 2628452094 CF_Handle "Handle for Close File";
CM_ SG_ 2628452094 WF_Handle "Handle for Write File";
CM_ SG_ 2628452094 RF_Handle "Handle for Read File";
CM_ SG_ 2628452094 SF_Handle "Handle for Seek File";
CM_ SG_ 2628452094 OF_FlagReadWrite "Read/Write/Both/Directory Flag for Open File";
CM_ SG_ 2628452094 CCD_PathName "Length of path name string for Change Current Directory";
CM_ SG_ 2628452094 MF_MoveModeCopy "Copy mode for Move File";
CM_ SG_ 2628452094 DF_DeleteMode "Copy mode for Move File";
CM_ SG_ 2628452094 GA_PathName "Length of path name string for Get File Attributes";
CM_ SG_ 2628452094 FDT_PathName "Length of path name string for Get File Date and Time";
CM_ SG_ 2628452094 CCD_TAN "Transaction Number for Change Default Directory";
CM_ SG_ 2628452094 GCD_TAN "Transaction Number for Get Default Directory";
CM_ SG_ 2628452094 FDT_TAN "Transaction Number for Get File Data & Time";
CM_ SG_ 2628452094 SA_TAN "Transaction Number for Set File Attribute";
CM_ SG_ 2628452094 GA_TAN "Transaction Number for Get File Attribute";
CM_ SG_ 2628452094 RF_TAN "Transaction Number for Read File";
CM_ SG_ 2628452094 CF_TAN "Transaction Number for Close File";
CM_ SG_ 2628452094 WF_TAN "Transaction Number for Write File";
CM_ SG_ 2628452094 SF_TAN "Transaction Number for Seek File";
CM_ SG_ 2628452094 OF_TAN "Transaction Number for Open File";
CM_ SG_ 2628452094 MF_TAN "Transaction Number for Move File";
CM_ SG_ 2628452094 DF_TAN "Transaction Number for Delete File";
CM_ SG_ 2628452094 VI_TAN "Transaction Number for Initailize Volume Request";
CM_ SG_ 2628452094 FSClientCommand "File Server - Client Command";
CM_ BO_ 2628517630 "File Server to Client (ECU) message";
CM_ SG_ 2628517630 GCD_PathName "Length of path name string for Get Current Directory";
CM_ SG_ 2628517630 GCD_FreeSpace "Free Volume Space for Get Current Directory";
CM_ SG_ 2628517630 FDT_TimeHour "Hour of File Time";
CM_ SG_ 2628517630 FDT_TimeMinutes "Minutes of File Time";
CM_ SG_ 2628517630 FDT_TimeSeconds "Day of File Time";
CM_ SG_ 2628517630 FDT_DateYear "Year of File Date";
CM_ SG_ 2628517630 SF_Position "Position of Seek File response";
CM_ SG_ 2628517630 GA_Size "The number of bytes in a file.";
CM_ SG_ 2628517630 GA_ATTR_VolumeIsCaseSensitive "GetFileAttribute attribute 'Volume is case-sensitive'";
CM_ SG_ 2628517630 GA_ATTR_VolumeIsRemovable "GetFileAttribute attribute 'Volume is not removable'";
CM_ SG_ 2628517630 FDT_DateMonth "Month of File Date";
CM_ SG_ 2628517630 GA_ATTR_SupportsLongFilenames "GetFileAttribute attribute 'Volume supports long filenames'";
CM_ SG_ 2628517630 GA_ATTR_IsDirectory "GetFileAttribute attribute 'Handle specifies a directory'";
CM_ SG_ 2628517630 VI_ATTR_IsDirectory "File Attribute DirectoryFile Attribute DirectoryFile Attribute DirectoryFile Attribute Directory";
CM_ SG_ 2628517630 GA_ATTR_IsVolume "GetFileAttribute attribute 'Handle specifies a volume'";
CM_ SG_ 2628517630 GA_ATTR_VolumeSupportsHidden "GetFileAttribute attribute 'Volume supports hidden attribute'";
CM_ SG_ 2628517630 GA_ATTR_Hidden "GetFileAttribute attribute 'Hidden'";
CM_ SG_ 2628517630 FDT_DateDay "Day of File Date";
CM_ SG_ 2628517630 GA_ATTR_ReadOnly "GetFileAttribute attribute 'Read-Only'";
CM_ SG_ 2628517630 OF_Handle "Handle for Open File";
CM_ SG_ 2628517630 GCD_TotalSpace "Total Volume Space for Get Current Directory";
CM_ SG_ 2628517630 RF_Count "Number of read bytes or number of read directory entries";
CM_ SG_ 2628517630 GSP_SupportMultipleVolumes "File Server Capabilities for Get File Server Properties";
CM_ SG_ 2628517630 WF_Count "Number of written bytes";
CM_ SG_ 2628517630 FDT_ErrorCode "Error Code for Get File Data & Time";
CM_ SG_ 2628517630 RF_ErrorCode "Error Code for Read File";
CM_ SG_ 2628517630 SF_ErrorCode "ErrorCode for Seek File";
CM_ SG_ 2628517630 FSNumberOfOpenFiles "Number of open files";
CM_ SG_ 2628517630 OF_ErrorCode "Error Code for Open File";
CM_ SG_ 2628517630 WF_ErrorCode "Error Code for Write File";
CM_ SG_ 2628517630 CF_ErrorCode "Error Code for Close File";
CM_ SG_ 2628517630 MF_ErrorCode "Error Code for Move File";
CM_ SG_ 2628517630 GA_ErrorCode "Error Code for Get File Attribute";
CM_ SG_ 2628517630 SA_ErrorCode "Error Code for Set File Attribute";
CM_ SG_ 2628517630 GCD_ErrorCode "ErrorCode for Get Current Directory";
CM_ SG_ 2628517630 CCD_ErrorCode "Error Code for Change Current Directory";
CM_ SG_ 2628517630 GSP_MaxNrSimultaneousFilesOpen "The number of files that can maximally be opened simultaneous at the File Server.";
CM_ SG_ 2628517630 DF_ErrorCode "Error Code for Delete File";
CM_ SG_ 2628517630 VI_ErrorCode "Error Code for Volume Initialization";
CM_ SG_ 2628517630 FSBusyWriting "Busy writing";
CM_ SG_ 2628517630 FSBusyReading "Busy reading";
CM_ SG_ 2628517630 OF_TAN "Transaction Number for Open File";
CM_ SG_ 2628517630 SF_TAN "Transaction Number for Seek File";
CM_ SG_ 2628517630 RF_TAN "Transaction Number for Rename File";
CM_ SG_ 2628517630 WF_TAN "Transaction Number for Write File";
CM_ SG_ 2628517630 CF_TAN "Transaction Number for Close File";
CM_ SG_ 2628517630 MF_TAN "Transaction Number for Move File";
CM_ SG_ 2628517630 GA_TAN "Transaction Number for Get File Attributes";
CM_ SG_ 2628517630 SA_TAN "Transaction Number for Set File Attributes";
CM_ SG_ 2628517630 FDT_TAN "Transaction Number for Get File Data & Time";
CM_ SG_ 2628517630 GCD_TAN "Transaction Number for Get Current Directory";
CM_ SG_ 2628517630 CCD_TAN "Transaction Number for Change Current Directory";
CM_ SG_ 2628517630 GSP_VersionNumber "The version of ISO11783-13 that this File Server meets.";
CM_ SG_ 2628517630 DF_TAN "Transaction Number for Delete File";
CM_ SG_ 2628517630 VI_TAN "Transaction Number for Volume Initialization";
CM_ SG_ 2628517630 FSServerCommand "File Server Command";
CM_ BO_ 2364540158 "Electronic Engine Controller #1";
CM_ SG_ 2364540158 EngStarterMode "There are several phases in a starting action and different reasons why a start cannot take place.";
CM_ SG_ 2364540158 SrcAddrssOfCtrllngDvcForEngCtrl "The source address of the SAE J1939 device currently controlling the engine.";
CM_ SG_ 2364540158 ActualEngPercentTorque "The calculated output torque of the engine.";
CM_ SG_ 2364540158 DriversDemandEngPercentTorque "The requested torque output of the engine by the driver.";
CM_ SG_ 2364540158 EngTorqueMode "State signal which indicates which engine torque mode is currently generating, limiting, or controlling the torque.";
CM_ SG_ 2364540158 ActlEngPrcntTorqueHighResolution "This parameter displays an additional torque in percent of the reference engine torque.";
CM_ BO_ 2563243774 "Extended TP (Data)";
CM_ BO_ 2563309310 "Extended TP (Command)";
CM_ BO_ 2314732030 "This PGN provides latitude and longitude referenced to WGS84";
CM_ BO_ 2583168510 "This PGN conveys a comprehensive set of Global Navigation Satellite System (GNSS) parameters, including position 
information
";
CM_ SG_ 2583168510 AgeOfDGNSSCorrections1 "Age of Differential corrections";
CM_ SG_ 2583168510 ReferenceStationID1 "Reference Station ID";
CM_ SG_ 2583168510 NumberOfReferenceStations "Numeric count, event counter, sequence counter";
CM_ SG_ 2583168510 GeoidalSeparation "The difference between the earth ellipsoid and mean-sea-level (geoid) defined by the reference datum used in the position solution ' -' = mean-sea-level below ellipsoid
";
CM_ SG_ 2583168510 PDOP "Dilution of Precision (DOP) indicates the contribution of satellite configuration geometry to positioning error
";
CM_ SG_ 2583168510 HDOP "Dilution of Precision (DOP) indicates the contribution of satellite configuration geometry to positioning error
";
CM_ SG_ 2583168510 NumberOfSVs "Numeric count, event counter, sequence counter";
CM_ SG_ 2583168510 Altitude "Altitude referenced to WGS-84";
CM_ SG_ 2583168510 Longitude "Longitude referenced to WGS-84";
CM_ SG_ 2583168510 Latitude "Latitude referenced to WGS-84";
CM_ SG_ 2583168510 PositionTime "24 hour clock, 0 =  midnight,  time is in UTC";
CM_ SG_ 2583168510 PositionDate "Days since January 1, 1970,  Date is relative to UTC Time";
CM_ SG_ 2583168510 SequenceID "An upward counting number used to tie related information together between different PGNs.
";
CM_ BO_ 2583299838 "GNSS pseudorange measurement noise statistics can be translated in the position domain in order to give statistical measures 
of the quality of the position solution. Intended for use with a Receiver Autonomous Integrity Monitoring (RAIM) application.
";
CM_ SG_ 2583299838 STDofAltError "Error distances expressed in meters";
CM_ SG_ 2583299838 STDofLonError "Error distances expressed in meters";
CM_ SG_ 2583299838 STDofLatError "Error distances expressed in meters.";
CM_ SG_ 2583299838 OrientationOfMinorAxis "Degrees clockwise relative to True North.";
CM_ SG_ 2583299838 STDofMinorAxis "Error distances expressed in meters.";
CM_ SG_ 2583299838 STDofMajorAxis "Error distances expressed in meters.";
CM_ SG_ 2583299838 RMSofPositionUncertainty "Error distances expressed in meters.";
CM_ SG_ 2583299838 SequenceID "An upward counting number used to tie related information together between different PGNs.
";
CM_ BO_ 2566849534 "Proprietary B3";
CM_ BO_ 2566849278 "Proprietary B2";
CM_ BO_ 2566849022 "Proprietary B1";
CM_ BO_ 2566848766 "Proprietary B0";
CM_ BO_ 2566842110 "Time/Date";
CM_ SG_ 2566842110 LocalHourOffset "The hour component of the offset between the UTC (Universal Time Coordinate) time and date and a local time zone time ...";
CM_ SG_ 2566842110 LocalMinuteOffset "The minute component of the offset between the UTC time and date and a local time zone time and date.  This is the ...";
CM_ SG_ 2566842110 Day "The day component of the current calendar date.  This should be reported as the day component of the current date at ...";
CM_ SG_ 2566842110 Hours "The hour component of the current time of day.  This should be reported as the hour component of the current time at ...";
CM_ SG_ 2566842110 Minutes "The minutes component of the current time of day.  This should be reported as the minutes component of the current time ...";
CM_ BO_ 2365475326 "Ground-based Speed and Distance";
CM_ BO_ 2365475070 "Wheel-based Speed and Distance";
CM_ SG_ 2365475070 OperatorDirectionReversed "This parameter indicates whether the reported direction is reversed from the perspective of the operator.";
CM_ BO_ 2566801406 "Message sent by any ECU connected to the implement bus requesting that the Tractor ECU not switch off 
the power for 2 s after it has received the wheel-based speed and distance message indicating that the 
ignition has been switched off. ";
CM_ SG_ 2566801406 ImplementInWorkState "Indicates that an implement is connected to a tractor or power unit and is in work state.";
CM_ BO_ 2365474558 "Secondary or Front Hitch Status";
CM_ SG_ 2365474558 FrontHitchExitReasonCode "This parameter is used to indicate why the front hitch cannot accept remote commands or has most recently 
stopped accepting remote commands. ";
CM_ SG_ 2365474558 FrontHitchPositionLimitStatus "Parameter used to report the tractor ECUs present limit status associated with a parameter whose commands are persistent";
CM_ BO_ 2365474302 "Primary or Rear Hitch Status";
CM_ SG_ 2365474302 RearHitchExitReasonCode "This parameter is used to indicate why the rear hitch cannot accept remote commands or has most recently 
stopped accepting remote commands. ";
CM_ SG_ 2365474302 RearHitchPositionLimitStatus "Parameter used to report the tractor ECUs present limit status associated with a parameter whose commands are persistent";
CM_ BO_ 2365474046 "Pprovides the measurement of the current secondary or front power take-off (PTO) output shaft parameters.";
CM_ SG_ 2365474046 FrontPTOExitReasonCode "This parameter is used to indicate why the front PTO cannot accept remote commands or has most recently 
stopped accepting remote commands.";
CM_ SG_ 2365474046 FrontPTOModeRqStatus "Parameter used to report the tractor ECUs status associated with a parameter whose requests are transient.";
CM_ SG_ 2365474046 FrontPTOEconomyModeRqStatus "Parameter used to report the tractor ECUs status associated with a parameter whose requests are transient.";
CM_ SG_ 2365474046 FrontPTOShaftSpeedLimitStatus "Parameter used to report the tractor ECUs present limit status associated with a parameter whose commands are persistent";
CM_ SG_ 2365474046 FrontPTOEngagementRqStatus "Parameter used to report the tractor ECUs status associated with a parameter whose requests are transient.";
CM_ BO_ 2365473790 "Provides the measurement of the current primary or rear power take-off (PTO) output shaft parameters.
";
CM_ SG_ 2365473790 RearPTOExitReasonCode "This parameter is used to indicate why the rear PTO cannot accept remote commands or has most recently 
stopped accepting remote commands.";
CM_ SG_ 2365473790 RearPTOModeRqStatus "Parameter used to report the tractor ECUs status associated with a parameter whose requests are transient.";
CM_ SG_ 2365473790 RearPTOEconomyModeRqStatus "Parameter used to report the tractor ECUs status associated with a parameter whose requests are transient.";
CM_ SG_ 2365473790 RearPTOShaftSpeedLimitStatus "Parameter used to report the tractor ECUs present limit status associated with a parameter whose commands are persistent";
CM_ SG_ 2365473790 RearPTOEngagementRqStatus "Parameter used to report the tractor ECUs status associated with a parameter whose requests are transient.";
CM_ BO_ 2365473534 "Hitch and PTO Commands";
CM_ BO_ 2365473278 "Lighting Command";
CM_ BO_ 2566799614 "Lighting Data";
CM_ BO_ 2365472766 "Auxiliary Valve Command";
CM_ BO_ 2365472510 "Auxiliary Valve Command";
CM_ BO_ 2365472254 "Auxiliary Valve Command";
CM_ BO_ 2365471998 "Auxiliary Valve Command";
CM_ BO_ 2365471742 "Auxiliary Valve Command";
CM_ BO_ 2365471486 "Auxiliary Valve Command";
CM_ BO_ 2365471230 "Auxiliary Valve Command";
CM_ BO_ 2365470974 "Auxiliary Valve Command";
CM_ BO_ 2365470718 "Auxiliary Valve Command";
CM_ BO_ 2365470462 "Auxiliary Valve Command";
CM_ BO_ 2365470206 "Auxiliary Valve Command";
CM_ BO_ 2365469950 "Auxiliary Valve Command";
CM_ BO_ 2365469694 "Auxiliary Valve Command";
CM_ BO_ 2365469438 "Auxiliary Valve Command";
CM_ BO_ 2365469182 "Auxiliary Valve Command";
CM_ BO_ 2365468926 "Auxiliary Valve Command";
CM_ BO_ 2365468670 "Auxiliary valve measured flow";
CM_ SG_ 2365468670 Valve15LimitStatus "Parameter used to report the tractor ECUs present limit status associated with a parameter whose commands are persistent";
CM_ BO_ 2365468414 "Auxiliary valve measured flow";
CM_ SG_ 2365468414 Valve14LimitStatus "Parameter used to report the tractor ECUs present limit status associated with a parameter whose commands are persistent";
CM_ BO_ 2365468158 "Auxiliary valve measured flow";
CM_ SG_ 2365468158 Valve13LimitStatus "Parameter used to report the tractor ECUs present limit status associated with a parameter whose commands are persistent";
CM_ BO_ 2365467902 "Auxiliary valve measured flow";
CM_ SG_ 2365467902 Valve12LimitStatus "Parameter used to report the tractor ECUs present limit status associated with a parameter whose commands are persistent";
CM_ BO_ 2365467646 "Auxiliary valve measured flow";
CM_ SG_ 2365467646 Valve11LimitStatus "Parameter used to report the tractor ECUs present limit status associated with a parameter whose commands are persistent";
CM_ BO_ 2365467390 "Auxiliary valve measured flow";
CM_ SG_ 2365467390 Valve10LimitStatus "Parameter used to report the tractor ECUs present limit status associated with a parameter whose commands are persistent";
CM_ BO_ 2365467134 "Auxiliary valve measured flow";
CM_ SG_ 2365467134 Valve9LimitStatus "Parameter used to report the tractor ECUs present limit status associated with a parameter whose commands are persistent";
CM_ BO_ 2365466878 "Auxiliary valve measured flow";
CM_ SG_ 2365466878 Valve8LimitStatus "Parameter used to report the tractor ECUs present limit status associated with a parameter whose commands are persistent";
CM_ BO_ 2365466622 "Auxiliary valve measured flow";
CM_ SG_ 2365466622 Valve7LimitStatus "Parameter used to report the tractor ECUs present limit status associated with a parameter whose commands are persistent";
CM_ BO_ 2365466366 "Auxiliary valve measured flow";
CM_ SG_ 2365466366 Valve6LimitStatus "Parameter used to report the tractor ECUs present limit status associated with a parameter whose commands are persistent";
CM_ BO_ 2365466110 "Auxiliary valve measured flow";
CM_ SG_ 2365466110 Valve5LimitStatus "Parameter used to report the tractor ECUs present limit status associated with a parameter whose commands are persistent";
CM_ BO_ 2365465854 "Auxiliary valve measured flow";
CM_ SG_ 2365465854 Valve4LimitStatus "Parameter used to report the tractor ECUs present limit status associated with a parameter whose commands are persistent";
CM_ BO_ 2365465598 "Auxiliary valve measured flow";
CM_ SG_ 2365465598 Valve3LimitStatus "Parameter used to report the tractor ECUs present limit status associated with a parameter whose commands are persistent";
CM_ BO_ 2365465342 "Auxiliary valve measured flow";
CM_ SG_ 2365465342 Valve2LimitStatus "Parameter used to report the tractor ECUs present limit status associated with a parameter whose commands are persistent";
CM_ BO_ 2365465086 "Auxiliary valve measured flow";
CM_ SG_ 2365465086 Valve1LimitStatus "Parameter used to report the tractor ECUs present limit status associated with a parameter whose commands are persistent";
CM_ BO_ 2365464830 "Auxiliary valve measured flow";
CM_ SG_ 2365464830 Valve0LimitStatus "Parameter used to report the tractor ECUs present limit status associated with a parameter whose commands are persistent";
CM_ BO_ 2365464574 "Esimated flow of auxiliary valve number 0 ";
CM_ SG_ 2365464574 AuxValve15ExitReasonCode "This parameter is used to indicate why the auxiliary valve 15 cannot accept remote commands or has most 
recently stopped accepting remote commands.";
CM_ SG_ 2365464574 Valve15LimitStatus "Parameter used to report the tractor ECUs present limit status associated with a parameter whose commands are persistent";
CM_ BO_ 2365464318 "Esimated flow of auxiliary valve number 0 ";
CM_ SG_ 2365464318 Valve14LimitStatus "Parameter used to report the tractor ECUs present limit status associated with a parameter whose commands are persistent";
CM_ BO_ 2365464062 "Esimated flow of auxiliary valve number 0 ";
CM_ SG_ 2365464062 Valve13LimitStatus "Parameter used to report the tractor ECUs present limit status associated with a parameter whose commands are persistent";
CM_ BO_ 2365463806 "Esimated flow of auxiliary valve number 0 ";
CM_ SG_ 2365463806 Valve12LimitStatus "Parameter used to report the tractor ECUs present limit status associated with a parameter whose commands are persistent";
CM_ BO_ 2365463550 "Esimated flow of auxiliary valve number 0 ";
CM_ SG_ 2365463550 Valve11LimitStatus "Parameter used to report the tractor ECUs present limit status associated with a parameter whose commands are persistent";
CM_ BO_ 2365463294 "Esimated flow of auxiliary valve number 0 ";
CM_ SG_ 2365463294 Valve10LimitStatus "Parameter used to report the tractor ECUs present limit status associated with a parameter whose commands are persistent";
CM_ BO_ 2365463038 "Esimated flow of auxiliary valve number 0 ";
CM_ SG_ 2365463038 Valve9LimitStatus "Parameter used to report the tractor ECUs present limit status associated with a parameter whose commands are persistent";
CM_ BO_ 2365462782 "Esimated flow of auxiliary valve number 0 ";
CM_ SG_ 2365462782 Valve8LimitStatus "Parameter used to report the tractor ECUs present limit status associated with a parameter whose commands are persistent";
CM_ BO_ 2365462526 "Esimated flow of auxiliary valve number 0 ";
CM_ SG_ 2365462526 Valve7LimitStatus "Parameter used to report the tractor ECUs present limit status associated with a parameter whose commands are persistent";
CM_ BO_ 2365462270 "Esimated flow of auxiliary valve number 0 ";
CM_ SG_ 2365462270 Valve6LimitStatus "Parameter used to report the tractor ECUs present limit status associated with a parameter whose commands are persistent";
CM_ BO_ 2365462014 "Esimated flow of auxiliary valve number 0 ";
CM_ SG_ 2365462014 Valve5LimitStatus "Parameter used to report the tractor ECUs present limit status associated with a parameter whose commands are persistent";
CM_ BO_ 2365461758 "Esimated flow of auxiliary valve number 0 ";
CM_ SG_ 2365461758 Valve4LimitStatus "Parameter used to report the tractor ECUs present limit status associated with a parameter whose commands are persistent";
CM_ BO_ 2365461502 "Esimated flow of auxiliary valve number 0 ";
CM_ SG_ 2365461502 Valve3LimitStatus "Parameter used to report the tractor ECUs present limit status associated with a parameter whose commands are persistent";
CM_ BO_ 2365461246 "Esimated flow of auxiliary valve number 0 ";
CM_ SG_ 2365461246 Valve2LimitStatus "Parameter used to report the tractor ECUs present limit status associated with a parameter whose commands are persistent";
BA_DEF_  "ISO11783_11_SpecVersion" STRING ;
BA_DEF_  "ISO11783_7_SpecVersion" STRING ;
BA_DEF_  "ISO11783_6_SpecVersion" STRING ;
BA_DEF_ SG_  "DDI" INT 0 65535;
BA_DEF_ BO_  "SingleFrame" INT 0 1;
BA_DEF_  "ProtocolType" STRING ;
BA_DEF_  "BusType" STRING ;
BA_DEF_  "ISO11783_TIM_SpecVersion" STRING ;
BA_DEF_ BU_  "NmStationAddress" INT 0 255;
BA_DEF_ BO_  "VFrameFormat" ENUM  "StandardCAN","ExtendedCAN","reserved","J1939PG","vector_leerstring";
BA_DEF_ BO_  "GenMsgSendType" ENUM  "cyclic","NotUsed","IfActive","NotUsed","NotUsed","NotUsed","NotUsed","NotUsed","noMsgSendType","vector_leerstring";
BA_DEF_ BO_  "GenMsgCycleTime" INT 0 3600000;
BA_DEF_ BO_  "GenMsgRequestable" INT 0 1;
BA_DEF_ BO_  "GenMsgCycleTimeFast" INT 0 3600000;
BA_DEF_ SG_  "SPN" INT 0 524287;
BA_DEF_  "DatabaseVersion" STRING ;
BA_DEF_ SG_  "GenSigSendType" ENUM  "Cyclic","OnWrite","OnWriteWithRepetition","OnChange","OnChangeWithRepetition","IfActive","IfActiveWithRepetition","NoSigSendType";
BA_DEF_ SG_  "SigType" ENUM  "Default","Range","RangeSigned","ASCII","Discrete","Control","ReferencePGN","DTC","StringDelimiter","StringLength","StringLengthControl","MessageCounter","MessageChecksum";
BA_DEF_  "ISO11783_12_SpecVersion" STRING ;
BA_DEF_  "ISO11783_13_SpecVersion" STRING ;
BA_DEF_ SG_  "GenSigStartValue" INT -2147483648 2147483647;
BA_DEF_ BU_  "ISO11783IOPVersion" ENUM  "0","1","2","3","4";
BA_DEF_ BU_  "ISO11783PDDVersion" ENUM  "0","1","2","3";
BA_DEF_ SG_  "SystemSignalLongSymbol" STRING ;
BA_DEF_DEF_  "ISO11783_11_SpecVersion" "";
BA_DEF_DEF_  "ISO11783_7_SpecVersion" "";
BA_DEF_DEF_  "ISO11783_6_SpecVersion" "";
BA_DEF_DEF_  "DDI" 0;
BA_DEF_DEF_  "SingleFrame" 1;
BA_DEF_DEF_  "ProtocolType" "";
BA_DEF_DEF_  "BusType" "";
BA_DEF_DEF_  "ISO11783_TIM_SpecVersion" "";
BA_DEF_DEF_  "NmStationAddress" 254;
BA_DEF_DEF_  "VFrameFormat" "J1939PG";
BA_DEF_DEF_  "GenMsgSendType" "noMsgSendType";
BA_DEF_DEF_  "GenMsgCycleTime" 0;
BA_DEF_DEF_  "GenMsgRequestable" 1;
BA_DEF_DEF_  "GenMsgCycleTimeFast" 0;
BA_DEF_DEF_  "SPN" 0;
BA_DEF_DEF_  "DatabaseVersion" "";
BA_DEF_DEF_  "GenSigSendType" "NoSigSendType";
BA_DEF_DEF_  "SigType" "Default";
BA_DEF_DEF_  "ISO11783_12_SpecVersion" "";
BA_DEF_DEF_  "ISO11783_13_SpecVersion" "";
BA_DEF_DEF_  "GenSigStartValue" 0;
BA_DEF_DEF_  "ISO11783IOPVersion" "3";
BA_DEF_DEF_  "ISO11783PDDVersion" "3";
BA_DEF_DEF_  "SystemSignalLongSymbol" "";
BA_ "ISO11783_12_SpecVersion" "2013-01-29 IS (ISO/TC 23/SC 19)";
BA_ "DatabaseVersion" "7.5 SP2";
BA_ "ProtocolType" "ISO11783";
BA_ "ISO11783_6_SpecVersion" "2010-05-11 FDIS";
BA_ "ISO11783_7_SpecVersion" "2009-01-29 FDIS";
BA_ "ISO11783_11_SpecVersion" "2007-04-01 IS";
BA_ "BusType" "CAN";
BA_ "ISO11783_13_SpecVersion" "2010-01-29 2007 With Amendments ";
BA_ "ISO11783_TIM_SpecVersion" "AEF 023 DIG 0_07 ISOBUS - ISOBUS Automation Principles";
BA_ "GenMsgSendType" BO_ 2364597502 0;
BA_ "GenMsgCycleTime" BO_ 2364597502 100;
BA_ "GenMsgSendType" BO_ 2360147710 8.48332452797837E-317;
BA_ "GenMsgCycleTime" BO_ 2360147710 100;
BA_ "GenMsgSendType" BO_ 2360213246 8.48390950170305E-317;
BA_ "GenMsgCycleTime" BO_ 2360213246 100;
BA_ "GenMsgSendType" BO_ 2563047166 8.48466048148473E-317;
BA_ "GenMsgCycleTime" BO_ 2563047166 1000;
BA_ "GenMsgSendType" BO_ 2563112702 8.48555770469758E-317;
BA_ "GenMsgCycleTime" BO_ 2563112702 100;
BA_ "GenMsgSendType" BO_ 2563178238 8.48652212083826E-317;
BA_ "GenMsgCycleTime" BO_ 2563178238 100;
BA_ "GenMsgSendType" BO_ 2314732030 8.51951780093012E-317;
BA_ "GenMsgCycleTime" BO_ 2314732030 100;
BA_ "GenMsgSendType" BO_ 2583168510 8.52390115134002E-317;
BA_ "GenMsgCycleTime" BO_ 2583168510 100;
BA_ "SingleFrame" BO_ 2583168510 0;
BA_ "GenMsgSendType" BO_ 2583299838 8.52558097453588E-317;
BA_ "GenMsgCycleTime" BO_ 2583299838 1000;
BA_ "SingleFrame" BO_ 2583299838 0;
BA_ "GenMsgSendType" BO_ 2566849534 8.52715012702708E-317;
BA_ "GenMsgCycleTime" BO_ 2566849534 100;
BA_ "GenMsgSendType" BO_ 2566849278 8.52871927951827E-317;
BA_ "GenMsgCycleTime" BO_ 2566849278 100;
BA_ "GenMsgSendType" BO_ 2566849022 8.53028843200946E-317;
BA_ "GenMsgCycleTime" BO_ 2566849022 100;
BA_ "GenMsgSendType" BO_ 2566848766 8.53185758450065E-317;
BA_ "GenMsgCycleTime" BO_ 2566848766 100;
BA_ "GenMsgSendType" BO_ 2365475326 8.53594844804822E-317;
BA_ "GenMsgCycleTime" BO_ 2365475326 100;
BA_ "GenMsgSendType" BO_ 2365475070 8.53733973690691E-317;
BA_ "GenMsgCycleTime" BO_ 2365475070 100;
BA_ "GenMsgCycleTime" BO_ 2566801406 100;
BA_ "GenMsgSendType" BO_ 2365474558 8.53967963180561E-317;
BA_ "GenMsgCycleTime" BO_ 2365474558 100;
BA_ "GenMsgSendType" BO_ 2365474302 8.54054523481712E-317;
BA_ "GenMsgCycleTime" BO_ 2365474302 100;
BA_ "GenMsgSendType" BO_ 2365474046 2;
BA_ "GenMsgCycleTime" BO_ 2365474046 100;
BA_ "GenMsgSendType" BO_ 2365473790 2;
BA_ "GenMsgCycleTime" BO_ 2365473790 100;
BA_ "GenMsgSendType" BO_ 2365473534 8.54526850239137E-317;
BA_ "GenMsgCycleTime" BO_ 2365473534 1000;
BA_ "GenMsgCycleTime" BO_ 2365473278 100;
BA_ "GenMsgCycleTime" BO_ 2566799614 100;
BA_ "GenMsgSendType" BO_ 2365472766 8.56219716768047E-317;
BA_ "GenMsgCycleTime" BO_ 2365472766 1000;
BA_ "GenMsgSendType" BO_ 2365472510 8.56296395756282E-317;
BA_ "GenMsgCycleTime" BO_ 2365472510 1000;
BA_ "GenMsgSendType" BO_ 2365472254 8.56373074744516E-317;
BA_ "GenMsgCycleTime" BO_ 2365472254 1000;
BA_ "GenMsgSendType" BO_ 2365471998 8.56449753732751E-317;
BA_ "GenMsgCycleTime" BO_ 2365471998 1000;
BA_ "GenMsgSendType" BO_ 2365471742 8.56526432720985E-317;
BA_ "GenMsgCycleTime" BO_ 2365471742 1000;
BA_ "GenMsgSendType" BO_ 2365471486 8.5660311170922E-317;
BA_ "GenMsgCycleTime" BO_ 2365471486 1000;
BA_ "GenMsgSendType" BO_ 2365471230 8.56679790697454E-317;
BA_ "GenMsgCycleTime" BO_ 2365471230 1000;
BA_ "GenMsgSendType" BO_ 2365470974 8.56756469685689E-317;
BA_ "GenMsgCycleTime" BO_ 2365470974 1000;
BA_ "GenMsgSendType" BO_ 2365470718 8.5683354392644E-317;
BA_ "GenMsgCycleTime" BO_ 2365470718 1000;
BA_ "GenMsgSendType" BO_ 2365470462 8.56910222914675E-317;
BA_ "GenMsgCycleTime" BO_ 2365470462 1000;
BA_ "GenMsgSendType" BO_ 2365470206 8.56986901902909E-317;
BA_ "GenMsgCycleTime" BO_ 2365470206 1000;
BA_ "GenMsgSendType" BO_ 2365469950 8.57063976143661E-317;
BA_ "GenMsgCycleTime" BO_ 2365469950 1000;
BA_ "GenMsgSendType" BO_ 2365469694 8.57140655131895E-317;
BA_ "GenMsgCycleTime" BO_ 2365469694 1000;
BA_ "GenMsgSendType" BO_ 2365469438 8.5721733412013E-317;
BA_ "GenMsgCycleTime" BO_ 2365469438 1000;
BA_ "GenMsgSendType" BO_ 2365469182 8.57294013108364E-317;
BA_ "GenMsgCycleTime" BO_ 2365469182 1000;
BA_ "GenMsgSendType" BO_ 2365468926 8.57370692096599E-317;
BA_ "GenMsgCycleTime" BO_ 2365468926 1000;
BA_ "GenMsgSendType" BO_ 2365468670 8.5746199542795E-317;
BA_ "GenMsgCycleTime" BO_ 2365468670 100;
BA_ "GenMsgSendType" BO_ 2365468414 8.57553298759302E-317;
BA_ "GenMsgCycleTime" BO_ 2365468414 100;
BA_ "GenMsgSendType" BO_ 2365468158 8.5764499734317E-317;
BA_ "GenMsgCycleTime" BO_ 2365468158 100;
BA_ "GenMsgSendType" BO_ 2365467902 8.57736300674521E-317;
BA_ "GenMsgCycleTime" BO_ 2365467902 100;
BA_ "GenMsgSendType" BO_ 2365467646 8.57827604005873E-317;
BA_ "GenMsgCycleTime" BO_ 2365467646 100;
BA_ "GenMsgSendType" BO_ 2365467390 8.57918907337224E-317;
BA_ "GenMsgCycleTime" BO_ 2365467390 100;
BA_ "GenMsgSendType" BO_ 2365467134 8.58010210668576E-317;
BA_ "GenMsgCycleTime" BO_ 2365467134 100;
BA_ "GenMsgSendType" BO_ 2365466878 8.58101513999927E-317;
BA_ "GenMsgCycleTime" BO_ 2365466878 100;
BA_ "GenMsgSendType" BO_ 2365466622 8.58192817331279E-317;
BA_ "GenMsgCycleTime" BO_ 2365466622 100;
BA_ "GenMsgSendType" BO_ 2365466366 8.58284515915147E-317;
BA_ "GenMsgCycleTime" BO_ 2365466366 100;
BA_ "GenMsgSendType" BO_ 2365466110 8.58375819246498E-317;
BA_ "GenMsgCycleTime" BO_ 2365466110 100;
BA_ "GenMsgSendType" BO_ 2365465854 8.5846712257785E-317;
BA_ "GenMsgCycleTime" BO_ 2365465854 100;
BA_ "GenMsgSendType" BO_ 2365465598 8.58558425909201E-317;
BA_ "GenMsgCycleTime" BO_ 2365465598 100;
BA_ "GenMsgSendType" BO_ 2365465342 8.58649729240553E-317;
BA_ "GenMsgCycleTime" BO_ 2365465342 100;
BA_ "GenMsgSendType" BO_ 2365465086 8.58741032571904E-317;
BA_ "GenMsgCycleTime" BO_ 2365465086 100;
BA_ "GenMsgSendType" BO_ 2365464830 8.58832335903256E-317;
BA_ "GenMsgCycleTime" BO_ 2365464830 100;
BA_ "GenMsgSendType" BO_ 2365464574 8.5893154428494E-317;
BA_ "GenMsgCycleTime" BO_ 2365464574 100;
BA_ "GenMsgSendType" BO_ 2365464318 8.59030752666625E-317;
BA_ "GenMsgCycleTime" BO_ 2365464318 100;
BA_ "GenMsgSendType" BO_ 2365464062 8.5912996104831E-317;
BA_ "GenMsgCycleTime" BO_ 2365464062 100;
BA_ "GenMsgSendType" BO_ 2365463806 8.59229169429995E-317;
BA_ "GenMsgCycleTime" BO_ 2365463806 100;
BA_ "GenMsgSendType" BO_ 2365463550 8.5932837781168E-317;
BA_ "GenMsgCycleTime" BO_ 2365463550 100;
BA_ "GenMsgSendType" BO_ 2365463294 8.59427586193365E-317;
BA_ "GenMsgCycleTime" BO_ 2365463294 100;
BA_ "GenMsgSendType" BO_ 2365463038 8.5952679457505E-317;
BA_ "GenMsgCycleTime" BO_ 2365463038 100;
BA_ "GenMsgSendType" BO_ 2365462782 8.59626002956735E-317;
BA_ "GenMsgCycleTime" BO_ 2365462782 100;
BA_ "GenMsgSendType" BO_ 2365462526 8.5972521133842E-317;
BA_ "GenMsgCycleTime" BO_ 2365462526 100;
BA_ "GenMsgSendType" BO_ 2365462270 8.59824419720105E-317;
BA_ "GenMsgCycleTime" BO_ 2365462270 100;
BA_ "GenMsgSendType" BO_ 2365462014 8.5992362810179E-317;
BA_ "GenMsgCycleTime" BO_ 2365462014 100;
BA_ "GenMsgSendType" BO_ 2365461758 8.60022836483475E-317;
BA_ "GenMsgCycleTime" BO_ 2365461758 100;
BA_ "GenMsgSendType" BO_ 2365461502 8.60122044865159E-317;
BA_ "GenMsgCycleTime" BO_ 2365461502 100;
BA_ "GenMsgSendType" BO_ 2365461246 8.60221253246844E-317;
BA_ "GenMsgCycleTime" BO_ 2365461246 100;
BA_ "SigType" SG_ 2624585470 ChallengeData 9;
BA_ "SigType" SG_ 2624585470 CertificateData 9;
BA_ "SigType" SG_ 2624651006 ChallengeData 9;
BA_ "SigType" SG_ 2624651006 CertificateData 9;
BA_ "SigType" SG_ 2619670270 CurvatureRequest 1;
BA_ "GenSigStartValue" SG_ 2619670270 CurvatureRequest 32128;
BA_ "SigType" SG_ 2619670270 VehicleSpeedRequest 1;
BA_ "GenSigStartValue" SG_ 2619670270 VehicleSpeedRequest 32128;
BA_ "SigType" SG_ 2619670270 HitchPosReq 1;
BA_ "SigType" SG_ 2619670270 PTOSpeedRequest 1;
BA_ "GenSigStartValue" SG_ 2619670270 PTOSpeedRequest 32128;
BA_ "SigType" SG_ 2619670270 AuxValveFlowReq 1;
BA_ "GenSigStartValue" SG_ 2619670270 AuxValveFlowReq 32128;
BA_ "GenSigStartValue" SG_ 2619670270 NumOfTIMFunctions 1;
BA_ "SigType" SG_ 2619604734 Curvature 1;
BA_ "GenSigStartValue" SG_ 2619604734 Curvature 32128;
BA_ "SigType" SG_ 2619604734 VehicleSpeed 1;
BA_ "GenSigStartValue" SG_ 2619604734 VehicleSpeed 32128;
BA_ "SigType" SG_ 2619604734 HitchPosition 1;
BA_ "SigType" SG_ 2619604734 PTOSpeed 1;
BA_ "GenSigStartValue" SG_ 2619604734 PTOSpeed 32128;
BA_ "SigType" SG_ 2619604734 TIMAuxValveFlow 1;
BA_ "GenSigStartValue" SG_ 2619604734 TIMAuxValveFlow 32128;
BA_ "GenSigStartValue" SG_ 2619604734 NumOfTIMFunctions 1;
BA_ "GenSigStartValue" SG_ 2619604734 NumOfSuportedTIMFunctions 1;
BA_ "SPN" SG_ 2364597502 HeartbeatSequenceNumber 7345;
BA_ "SigType" SG_ 2364597502 HeartbeatSequenceNumber 1;
BA_ "SPN" SG_ 2360147710 GuidSysComExitReasonCode 5725;
BA_ "SPN" SG_ 2360147710 GuidanceLimitStatus 5726;
BA_ "SigType" SG_ 2360147710 RequestResetCommandStatus 4;
BA_ "SPN" SG_ 2360147710 RequestResetCommandStatus 5240;
BA_ "SigType" SG_ 2360147710 SteeringInputPositionStatus 4;
BA_ "SPN" SG_ 2360147710 SteeringInputPositionStatus 5241;
BA_ "SigType" SG_ 2360147710 SteeringSystemReadiness 4;
BA_ "SPN" SG_ 2360147710 SteeringSystemReadiness 5242;
BA_ "SigType" SG_ 2360147710 MechanicalSystemLockout 4;
BA_ "SPN" SG_ 2360147710 MechanicalSystemLockout 5243;
BA_ "SigType" SG_ 2360147710 EstimatedCurvature 1;
BA_ "SPN" SG_ 2360147710 EstimatedCurvature 5238;
BA_ "SigType" SG_ 2360213246 CurvatureCommandStatus 4;
BA_ "SPN" SG_ 2360213246 CurvatureCommandStatus 5239;
BA_ "SigType" SG_ 2360213246 CurvatureCommand 1;
BA_ "SPN" SG_ 2360213246 CurvatureCommand 5237;
BA_ "SigType" SG_ 2563047166 FailSaveModeCmd 4;
BA_ "SPN" SG_ 2563047166 StateCmd 2933;
BA_ "SPN" SG_ 2563047166 PortFlowCmd 2944;
BA_ "SigType" SG_ 2563047166 PortFlowCmd 1;
BA_ "SPN" SG_ 2563112702 ValveLimitStatus 5192;
BA_ "SPN" SG_ 2563112702 ReturnPortPressure 2943;
BA_ "SigType" SG_ 2563112702 ReturnPortPressure 1;
BA_ "SPN" SG_ 2563112702 RetractPortPressure 2942;
BA_ "SigType" SG_ 2563112702 RetractPortPressure 1;
BA_ "SPN" SG_ 2563112702 ExtendedPortPressure 2941;
BA_ "SigType" SG_ 2563112702 ExtendedPortPressure 1;
BA_ "SPN" SG_ 2563112702 RetractPortMeasuredFlow 2938;
BA_ "SigType" SG_ 2563112702 RetractPortMeasuredFlow 1;
BA_ "SPN" SG_ 2563112702 ExtendedPortMeasuredFlow 2937;
BA_ "SigType" SG_ 2563112702 ExtendedPortMeasuredFlow 1;
BA_ "SPN" SG_ 2563178238 ValveLimitStatus 5193;
BA_ "SPN" SG_ 2563178238 FailSafeMode 2934;
BA_ "SigType" SG_ 2563178238 FailSafeMode 4;
BA_ "SPN" SG_ 2563178238 ValveState 2932;
BA_ "SPN" SG_ 2563178238 RetractPortEstimatedFlow 2940;
BA_ "SigType" SG_ 2563178238 RetractPortEstimatedFlow 1;
BA_ "SPN" SG_ 2563178238 ExtendedPortEstimatedFlow 2939;
BA_ "SigType" SG_ 2563178238 ExtendedPortEstimatedFlow 1;
BA_ "SigType" SG_ 2628452094 VI_VolumeName 9;
BA_ "SigType" SG_ 2628452094 OF_PathName 9;
BA_ "SigType" SG_ 2628452094 DF_PathName 9;
BA_ "SigType" SG_ 2628452094 SA_PathName 9;
BA_ "SigType" SG_ 2628452094 CCD_PathName 9;
BA_ "SigType" SG_ 2628452094 GA_PathName 9;
BA_ "SigType" SG_ 2628452094 FDT_PathName 9;
BA_ "SigType" SG_ 2628452094 VS_VolumeName 8;
BA_ "SystemSignalLongSymbol" SG_ 2628452094 VS_RequestVolumeToPrepareForRemo "VS_RequestVolumeToPrepareForRemoval";
BA_ "SigType" SG_ 2628517630 GCD_PathName 9;
BA_ "SigType" SG_ 2628517630 VS_VolumeName 9;
BA_ "SPN" SG_ 2364540158 EngDemandPercentTorque 2432;
BA_ "SigType" SG_ 2364540158 EngDemandPercentTorque 1;
BA_ "SPN" SG_ 2364540158 EngStarterMode 1675;
BA_ "SPN" SG_ 2364540158 SrcAddrssOfCtrllngDvcForEngCtrl 1483;
BA_ "SPN" SG_ 2364540158 EngSpeed 190;
BA_ "SigType" SG_ 2364540158 EngSpeed 1;
BA_ "SPN" SG_ 2364540158 ActualEngPercentTorque 513;
BA_ "SigType" SG_ 2364540158 ActualEngPercentTorque 1;
BA_ "SPN" SG_ 2364540158 DriversDemandEngPercentTorque 512;
BA_ "SigType" SG_ 2364540158 DriversDemandEngPercentTorque 1;
BA_ "SPN" SG_ 2364540158 EngTorqueMode 899;
BA_ "SPN" SG_ 2364540158 ActlEngPrcntTorqueHighResolution 4154;
BA_ "SigType" SG_ 2563243774 Byte7 1;
BA_ "SigType" SG_ 2563243774 Byte6 1;
BA_ "SigType" SG_ 2563243774 Byte5 1;
BA_ "SigType" SG_ 2563243774 Byte4 1;
BA_ "SigType" SG_ 2563243774 Byte3 1;
BA_ "SigType" SG_ 2563243774 Byte2 1;
BA_ "SigType" SG_ 2563243774 Byte1 1;
BA_ "SigType" SG_ 2563243774 SequenceNumber 1;
BA_ "GenSigStartValue" SG_ 2563243774 SequenceNumber 1;
BA_ "SigType" SG_ 2563309310 PGNumber 6;
BA_ "SigType" SG_ 2563309310 DataPacketOffset 1;
BA_ "SigType" SG_ 2563309310 NextPacketNumberToSend 1;
BA_ "GenSigStartValue" SG_ 2563309310 NextPacketNumberToSend 1;
BA_ "SigType" SG_ 2563309310 NumberOfBytesTransfered 1;
BA_ "GenSigStartValue" SG_ 2563309310 NumberOfBytesTransfered 1786;
BA_ "SigType" SG_ 2563309310 NumberOfPacketsOffset 1;
BA_ "GenSigStartValue" SG_ 2563309310 NumberOfPacketsOffset 1;
BA_ "SigType" SG_ 2563309310 NumberOfPacketsToSend 1;
BA_ "GenSigStartValue" SG_ 2563309310 NumberOfPacketsToSend 1;
BA_ "SigType" SG_ 2563309310 NumberOfBytesToTransfer 1;
BA_ "GenSigStartValue" SG_ 2563309310 NumberOfBytesToTransfer 1786;
BA_ "SigType" SG_ 2563309310 ControlByte 1;
BA_ "SigType" SG_ 2583168510 AgeOfDGNSSCorrections1 1;
BA_ "SigType" SG_ 2583168510 ReferenceStationID1 1;
BA_ "SigType" SG_ 2583168510 NumberOfReferenceStations 1;
BA_ "SigType" SG_ 2583168510 GeoidalSeparation 2;
BA_ "SigType" SG_ 2583168510 PDOP 2;
BA_ "SigType" SG_ 2583168510 HDOP 2;
BA_ "SigType" SG_ 2583168510 NumberOfSVs 1;
BA_ "SigType" SG_ 2583168510 GNSSIntegrity 4;
BA_ "SigType" SG_ 2583168510 PositionTime 1;
BA_ "SigType" SG_ 2583168510 PositionDate 1;
BA_ "SigType" SG_ 2583168510 SequenceID 1;
BA_ "SigType" SG_ 2583299838 STDofAltError 1;
BA_ "SigType" SG_ 2583299838 STDofLonError 1;
BA_ "SigType" SG_ 2583299838 STDofLatError 1;
BA_ "SigType" SG_ 2583299838 OrientationOfMinorAxis 1;
BA_ "SigType" SG_ 2583299838 STDofMinorAxis 1;
BA_ "SigType" SG_ 2583299838 STDofMajorAxis 1;
BA_ "SigType" SG_ 2583299838 RMSofPositionUncertainty 1;
BA_ "SigType" SG_ 2583299838 SequenceID 1;
BA_ "SigType" SG_ 2566849534 ManufacturerSpecific8 1;
BA_ "SigType" SG_ 2566849534 ManufacturerSpecific7 1;
BA_ "SigType" SG_ 2566849534 ManufacturerSpecific6 1;
BA_ "SigType" SG_ 2566849534 ManufacturerSpecific5 1;
BA_ "SigType" SG_ 2566849534 ManufacturerSpecific4 1;
BA_ "SigType" SG_ 2566849534 ManufacturerSpecific3 1;
BA_ "SigType" SG_ 2566849534 ManufacturerSpecific2 1;
BA_ "SigType" SG_ 2566849534 ManufacturerSpecific1 1;
BA_ "SigType" SG_ 2566849278 ManufacturerSpecific8 1;
BA_ "SigType" SG_ 2566849278 ManufacturerSpecific7 1;
BA_ "SigType" SG_ 2566849278 ManufacturerSpecific6 1;
BA_ "SigType" SG_ 2566849278 ManufacturerSpecific5 1;
BA_ "SigType" SG_ 2566849278 ManufacturerSpecific4 1;
BA_ "SigType" SG_ 2566849278 ManufacturerSpecific3 1;
BA_ "SigType" SG_ 2566849278 ManufacturerSpecific2 1;
BA_ "SigType" SG_ 2566849278 ManufacturerSpecific1 1;
BA_ "SigType" SG_ 2566849022 ManufacturerSpecific8 1;
BA_ "SigType" SG_ 2566849022 ManufacturerSpecific7 1;
BA_ "SigType" SG_ 2566849022 ManufacturerSpecific6 1;
BA_ "SigType" SG_ 2566849022 ManufacturerSpecific5 1;
BA_ "SigType" SG_ 2566849022 ManufacturerSpecific4 1;
BA_ "SigType" SG_ 2566849022 ManufacturerSpecific3 1;
BA_ "SigType" SG_ 2566849022 ManufacturerSpecific2 1;
BA_ "SigType" SG_ 2566849022 ManufacturerSpecific1 1;
BA_ "SigType" SG_ 2566848766 ManufacturerSpecific8 1;
BA_ "SigType" SG_ 2566848766 ManufacturerSpecific7 1;
BA_ "SigType" SG_ 2566848766 ManufacturerSpecific6 1;
BA_ "SigType" SG_ 2566848766 ManufacturerSpecific5 1;
BA_ "SigType" SG_ 2566848766 ManufacturerSpecific4 1;
BA_ "SigType" SG_ 2566848766 ManufacturerSpecific3 1;
BA_ "SigType" SG_ 2566848766 ManufacturerSpecific2 1;
BA_ "SigType" SG_ 2566848766 ManufacturerSpecific1 1;
BA_ "SigType" SG_ 2566842110 LocalHourOffset 1;
BA_ "SPN" SG_ 2566842110 LocalHourOffset 1602;
BA_ "SigType" SG_ 2566842110 LocalMinuteOffset 1;
BA_ "SPN" SG_ 2566842110 LocalMinuteOffset 1601;
BA_ "SigType" SG_ 2566842110 Year 1;
BA_ "SPN" SG_ 2566842110 Year 964;
BA_ "SigType" SG_ 2566842110 Day 1;
BA_ "SPN" SG_ 2566842110 Day 962;
BA_ "SigType" SG_ 2566842110 Month 1;
BA_ "SPN" SG_ 2566842110 Month 963;
BA_ "SigType" SG_ 2566842110 Hours 1;
BA_ "SPN" SG_ 2566842110 Hours 961;
BA_ "SigType" SG_ 2566842110 Minutes 1;
BA_ "SPN" SG_ 2566842110 Minutes 960;
BA_ "SigType" SG_ 2566842110 Seconds 1;
BA_ "SPN" SG_ 2566842110 Seconds 959;
BA_ "SigType" SG_ 2365475326 GroundBasedMachineDirection 4;
BA_ "SPN" SG_ 2365475326 GroundBasedMachineDirection 1861;
BA_ "SigType" SG_ 2365475326 GroundBasedMachineDistance 1;
BA_ "SPN" SG_ 2365475326 GroundBasedMachineDistance 1860;
BA_ "SigType" SG_ 2365475326 GroundBasedMachineSpeed 1;
BA_ "SPN" SG_ 2365475326 GroundBasedMachineSpeed 1859;
BA_ "SigType" SG_ 2365475070 OperatorDirectionReversed 5;
BA_ "SPN" SG_ 2365475070 OperatorDirectionReversed 5244;
BA_ "SigType" SG_ 2365475070 StartStopState 4;
BA_ "SPN" SG_ 2365475070 StartStopState 5203;
BA_ "SigType" SG_ 2365475070 KeySwitchState 4;
BA_ "SPN" SG_ 2365475070 KeySwitchState 1865;
BA_ "SigType" SG_ 2365475070 WheelBasedMachineDirection 4;
BA_ "SPN" SG_ 2365475070 WheelBasedMachineDirection 1864;
BA_ "SigType" SG_ 2365475070 MaxTimeOfTractorPower 1;
BA_ "SPN" SG_ 2365475070 MaxTimeOfTractorPower 1866;
BA_ "SigType" SG_ 2365475070 WheelBasedMachineDistance 1;
BA_ "SPN" SG_ 2365475070 WheelBasedMachineDistance 1863;
BA_ "SigType" SG_ 2365475070 WheelBasedMachineSpeed 1;
BA_ "SPN" SG_ 2365475070 WheelBasedMachineSpeed 1862;
BA_ "SPN" SG_ 2566801406 ImplementInWorkState 7447;
BA_ "SigType" SG_ 2566801406 ImplementInWorkState 4;
BA_ "SigType" SG_ 2566801406 ImplementTransportState 4;
BA_ "SPN" SG_ 2566801406 ImplementTransportState 1869;
BA_ "SigType" SG_ 2566801406 ImplementParkState 4;
BA_ "SPN" SG_ 2566801406 ImplementParkState 1870;
BA_ "SigType" SG_ 2566801406 ImplementReadyToWorkState 4;
BA_ "SPN" SG_ 2566801406 ImplementReadyToWorkState 1871;
BA_ "SigType" SG_ 2566801406 MaintainECUPower 4;
BA_ "SPN" SG_ 2566801406 MaintainECUPower 1867;
BA_ "SigType" SG_ 2566801406 MaintainActuatorPower 4;
BA_ "SPN" SG_ 2566801406 MaintainActuatorPower 1868;
BA_ "SPN" SG_ 2365474558 FrontHitchExitReasonCode 5816;
BA_ "SigType" SG_ 2365474558 FrontDraft 1;
BA_ "SPN" SG_ 2365474558 FrontDraft 1878;
BA_ "SigType" SG_ 2365474558 FrontNominalLowerLinkForce 1;
BA_ "SPN" SG_ 2365474558 FrontNominalLowerLinkForce 1880;
BA_ "SigType" SG_ 2365474558 FrontHitchInWorkIndication 4;
BA_ "SPN" SG_ 2365474558 FrontHitchInWorkIndication 1876;
BA_ "SPN" SG_ 2365474558 FrontHitchPositionLimitStatus 5150;
BA_ "SigType" SG_ 2365474558 FrontHitchPosition 1;
BA_ "SPN" SG_ 2365474558 FrontHitchPosition 1872;
BA_ "SPN" SG_ 2365474302 RearHitchExitReasonCode 5819;
BA_ "SigType" SG_ 2365474302 RearDraft 1;
BA_ "SPN" SG_ 2365474302 RearDraft 1879;
BA_ "SigType" SG_ 2365474302 RearNominalPowerLinkForce 1;
BA_ "SPN" SG_ 2365474302 RearNominalPowerLinkForce 1881;
BA_ "SigType" SG_ 2365474302 RearHitchInWorkIndication 4;
BA_ "SPN" SG_ 2365474302 RearHitchInWorkIndication 1877;
BA_ "SPN" SG_ 2365474302 RearHitchPositionLimitStatus 5151;
BA_ "SigType" SG_ 2365474302 RearHitchPosition 1;
BA_ "SPN" SG_ 2365474302 RearHitchPosition 1873;
BA_ "SPN" SG_ 2365474046 FrontPTOExitReasonCode 5817;
BA_ "SigType" SG_ 2365474046 FrontPTOModeRqStatus 4;
BA_ "SPN" SG_ 2365474046 FrontPTOModeRqStatus 5153;
BA_ "SigType" SG_ 2365474046 FrontPTOEconomyModeRqStatus 4;
BA_ "SPN" SG_ 2365474046 FrontPTOEconomyModeRqStatus 5154;
BA_ "SPN" SG_ 2365474046 FrontPTOShaftSpeedLimitStatus 5155;
BA_ "SigType" SG_ 2365474046 FrontPTOEngagement 4;
BA_ "SPN" SG_ 2365474046 FrontPTOEngagement 1888;
BA_ "SigType" SG_ 2365474046 FrontPTOMode 4;
BA_ "SPN" SG_ 2365474046 FrontPTOMode 1889;
BA_ "SigType" SG_ 2365474046 FrontPTOEconomyMode 4;
BA_ "SPN" SG_ 2365474046 FrontPTOEconomyMode 1891;
BA_ "SigType" SG_ 2365474046 FrontPTOEngagementRqStatus 4;
BA_ "SPN" SG_ 2365474046 FrontPTOEngagementRqStatus 5152;
BA_ "SigType" SG_ 2365474046 FrontPTOOutShaftSpeedSetPoint 1;
BA_ "SPN" SG_ 2365474046 FrontPTOOutShaftSpeedSetPoint 1884;
BA_ "SigType" SG_ 2365474046 FrontPTOOutShaftSpeed 1;
BA_ "SPN" SG_ 2365474046 FrontPTOOutShaftSpeed 1882;
BA_ "SPN" SG_ 2365473790 RearPTOExitReasonCode 5820;
BA_ "SigType" SG_ 2365473790 RearPTOModeRqStatus 4;
BA_ "SPN" SG_ 2365473790 RearPTOModeRqStatus 5157;
BA_ "SigType" SG_ 2365473790 RearPTOEconomyModeRqStatus 4;
BA_ "SPN" SG_ 2365473790 RearPTOEconomyModeRqStatus 5158;
BA_ "SPN" SG_ 2365473790 RearPTOShaftSpeedLimitStatus 5159;
BA_ "SigType" SG_ 2365473790 RearPTOEngagement 4;
BA_ "SPN" SG_ 2365473790 RearPTOEngagement 2408;
BA_ "SigType" SG_ 2365473790 RearPTOMode 4;
BA_ "SPN" SG_ 2365473790 RearPTOMode 1890;
BA_ "SigType" SG_ 2365473790 RearPTOEconomyMode 4;
BA_ "SPN" SG_ 2365473790 RearPTOEconomyMode 1892;
BA_ "SigType" SG_ 2365473790 RearPTOEngagementRqStatus 4;
BA_ "SPN" SG_ 2365473790 RearPTOEngagementRqStatus 5156;
BA_ "SigType" SG_ 2365473790 RearPTOOutputShaftSpeedSetPoint 1;
BA_ "SPN" SG_ 2365473790 RearPTOOutputShaftSpeedSetPoint 1885;
BA_ "SigType" SG_ 2365473790 RearPTOOutputShaftSpeed 1;
BA_ "SPN" SG_ 2365473790 RearPTOOutputShaftSpeed 1883;
BA_ "SigType" SG_ 2365473534 FrontPTOModeCmd 4;
BA_ "SPN" SG_ 2365473534 FrontPTOModeCmd 1895;
BA_ "SigType" SG_ 2365473534 RearPTOModeCmd 4;
BA_ "SPN" SG_ 2365473534 RearPTOModeCmd 1896;
BA_ "SigType" SG_ 2365473534 FrontPTOEconomyModeCmd 4;
BA_ "SPN" SG_ 2365473534 FrontPTOEconomyModeCmd 1897;
BA_ "SigType" SG_ 2365473534 RearPTOEconomyModeCmd 4;
BA_ "SPN" SG_ 2365473534 RearPTOEconomyModeCmd 1898;
BA_ "SigType" SG_ 2365473534 FrontPTOEngagementCmd 4;
BA_ "SPN" SG_ 2365473534 FrontPTOEngagementCmd 1893;
BA_ "SigType" SG_ 2365473534 RearPTOEngagementCmd 4;
BA_ "SPN" SG_ 2365473534 RearPTOEngagementCmd 1894;
BA_ "SigType" SG_ 2365473534 RearPTOOutShaftSpeedSetPointCmd 1;
BA_ "SPN" SG_ 2365473534 RearPTOOutShaftSpeedSetPointCmd 1887;
BA_ "SigType" SG_ 2365473534 FrontPTOOutShaftSpeedSetPointCmd 1;
BA_ "SPN" SG_ 2365473534 FrontPTOOutShaftSpeedSetPointCmd 1886;
BA_ "SigType" SG_ 2365473534 RearHitchPositionCmd 1;
BA_ "SPN" SG_ 2365473534 RearHitchPositionCmd 1875;
BA_ "SigType" SG_ 2365473534 FrontHitchPositionCmd 1;
BA_ "SPN" SG_ 2365473534 FrontHitchPositionCmd 1874;
BA_ "SPN" SG_ 2365473278 ImplementRearWorkLightCmd 2405;
BA_ "SigType" SG_ 2365473278 ImplementRearWorkLightCmd 4;
BA_ "SPN" SG_ 2365473278 ImplementLeftFacingWorkLightCmd 2399;
BA_ "SigType" SG_ 2365473278 ImplementLeftFacingWorkLightCmd 4;
BA_ "SPN" SG_ 2365473278 ImplementRightFacingWorkLightCmd 2401;
BA_ "SigType" SG_ 2365473278 ImplementRightFacingWorkLightCmd 4;
BA_ "SPN" SG_ 2365473278 LightingDataRequestCmd 2393;
BA_ "SigType" SG_ 2365473278 LightingDataRequestCmd 4;
BA_ "SPN" SG_ 2365473278 ImplementLeftForwardLightCmd 2597;
BA_ "SigType" SG_ 2365473278 ImplementLeftForwardLightCmd 4;
BA_ "SPN" SG_ 2365473278 ImplementRightForwardLightCmd 2406;
BA_ "SigType" SG_ 2365473278 ImplementRightForwardLightCmd 4;
BA_ "SPN" SG_ 2365473278 ImplementOEMOption1LightCmd 2395;
BA_ "SigType" SG_ 2365473278 ImplementOEMOption1LightCmd 4;
BA_ "SPN" SG_ 2365473278 ImplementOEMOption2LightCmd 2397;
BA_ "SigType" SG_ 2365473278 ImplementOEMOption2LightCmd 4;
BA_ "SPN" SG_ 2365473278 TractorFrontHighWorkLightCmd 2355;
BA_ "SigType" SG_ 2365473278 TractorFrontHighWorkLightCmd 4;
BA_ "SPN" SG_ 2365473278 TractorFrontLowWorkLightCmd 2353;
BA_ "SigType" SG_ 2365473278 TractorFrontLowWorkLightCmd 4;
BA_ "SPN" SG_ 2365473278 TractorSideHighWorkLightCmd 2365;
BA_ "SigType" SG_ 2365473278 TractorSideHighWorkLightCmd 4;
BA_ "SPN" SG_ 2365473278 TractorSideLowWorkLightCmd 2363;
BA_ "SigType" SG_ 2365473278 TractorSideLowWorkLightCmd 4;
BA_ "SPN" SG_ 2365473278 TractorRearHighWorkLightCmd 2361;
BA_ "SigType" SG_ 2365473278 TractorRearHighWorkLightCmd 4;
BA_ "SPN" SG_ 2365473278 TractorRearLowWorkLightCmd 2359;
BA_ "SigType" SG_ 2365473278 TractorRearLowWorkLightCmd 4;
BA_ "SPN" SG_ 2365473278 TractorUndersideWorkLightCmd 2357;
BA_ "SigType" SG_ 2365473278 TractorUndersideWorkLightCmd 4;
BA_ "SPN" SG_ 2365473278 RearFogLightCmd 2389;
BA_ "SigType" SG_ 2365473278 RearFogLightCmd 4;
BA_ "SPN" SG_ 2365473278 TractorMarkerLightCmd 2377;
BA_ "SigType" SG_ 2365473278 TractorMarkerLightCmd 4;
BA_ "SPN" SG_ 2365473278 ImplementMarkerLightCmd 2379;
BA_ "SigType" SG_ 2365473278 ImplementMarkerLightCmd 4;
BA_ "SPN" SG_ 2365473278 TractorClearanceLightCmd 2381;
BA_ "SigType" SG_ 2365473278 TractorClearanceLightCmd 4;
BA_ "SPN" SG_ 2365473278 ImplementClearanceLightCmd 2383;
BA_ "SigType" SG_ 2365473278 ImplementClearanceLightCmd 4;
BA_ "SPN" SG_ 2365473278 LeftStopLightCmd 2371;
BA_ "SigType" SG_ 2365473278 LeftStopLightCmd 4;
BA_ "SPN" SG_ 2365473278 RightStopLightCmd 2373;
BA_ "SigType" SG_ 2365473278 RightStopLightCmd 4;
BA_ "SPN" SG_ 2365473278 CentreStopLightCmd 2375;
BA_ "SigType" SG_ 2365473278 CentreStopLightCmd 4;
BA_ "SPN" SG_ 2365473278 BackUpLightAndAlarmHornCmd 2391;
BA_ "SigType" SG_ 2365473278 BackUpLightAndAlarmHornCmd 4;
BA_ "SPN" SG_ 2365473278 LeftTurnSignalLightCmd 2367;
BA_ "SigType" SG_ 2365473278 LeftTurnSignalLightCmd 4;
BA_ "SPN" SG_ 2365473278 RightTurnSignalLightCmd 2369;
BA_ "SigType" SG_ 2365473278 RightTurnSignalLightCmd 4;
BA_ "SPN" SG_ 2365473278 RotatingBeaconLightCmd 2385;
BA_ "SigType" SG_ 2365473278 RotatingBeaconLightCmd 4;
BA_ "SPN" SG_ 2365473278 TractorFrontFogLightCmd 2387;
BA_ "SigType" SG_ 2365473278 TractorFrontFogLightCmd 4;
BA_ "SPN" SG_ 2365473278 HighBeamHeadLightCmd 2347;
BA_ "SigType" SG_ 2365473278 HighBeamHeadLightCmd 4;
BA_ "SPN" SG_ 2365473278 LowBeamHeadLightCmd 2349;
BA_ "SigType" SG_ 2365473278 LowBeamHeadLightCmd 4;
BA_ "SPN" SG_ 2365473278 AlternateHeadLightCmd 2351;
BA_ "SigType" SG_ 2365473278 AlternateHeadLightCmd 4;
BA_ "SPN" SG_ 2365473278 DaytimeRunningLightCmd 2403;
BA_ "SigType" SG_ 2365473278 DaytimeRunningLightCmd 4;
BA_ "SPN" SG_ 2566799614 ImplementRearWorkLightData 2394;
BA_ "SigType" SG_ 2566799614 ImplementRearWorkLightData 4;
BA_ "SPN" SG_ 2566799614 ImplLeftFacingWorkLightData 2400;
BA_ "SigType" SG_ 2566799614 ImplLeftFacingWorkLightData 4;
BA_ "SPN" SG_ 2566799614 ImplRightFacingWorkLightData 2402;
BA_ "SigType" SG_ 2566799614 ImplRightFacingWorkLightData 4;
BA_ "SPN" SG_ 2566799614 ImplementLeftForwardLightData 2598;
BA_ "SigType" SG_ 2566799614 ImplementLeftForwardLightData 4;
BA_ "SPN" SG_ 2566799614 ImplementRightForwardLightData 2407;
BA_ "SigType" SG_ 2566799614 ImplementRightForwardLightData 4;
BA_ "SPN" SG_ 2566799614 ImplementOEMOption1LightData 2396;
BA_ "SigType" SG_ 2566799614 ImplementOEMOption1LightData 4;
BA_ "SPN" SG_ 2566799614 ImplementOEMOption2LightData 2398;
BA_ "SigType" SG_ 2566799614 ImplementOEMOption2LightData 4;
BA_ "SPN" SG_ 2566799614 TractorFrontHighWorkLightData 2356;
BA_ "SigType" SG_ 2566799614 TractorFrontHighWorkLightData 4;
BA_ "SPN" SG_ 2566799614 TractorFrontLowWorkLightData 2354;
BA_ "SigType" SG_ 2566799614 TractorFrontLowWorkLightData 4;
BA_ "SPN" SG_ 2566799614 TractorSideHighWorkLightData 2366;
BA_ "SigType" SG_ 2566799614 TractorSideHighWorkLightData 4;
BA_ "SPN" SG_ 2566799614 TractorSideLowWorkLightData 2364;
BA_ "SigType" SG_ 2566799614 TractorSideLowWorkLightData 4;
BA_ "SPN" SG_ 2566799614 TractorRearHighWorkLightData 2362;
BA_ "SigType" SG_ 2566799614 TractorRearHighWorkLightData 4;
BA_ "SPN" SG_ 2566799614 TractorRearLowWorkLightData 2360;
BA_ "SigType" SG_ 2566799614 TractorRearLowWorkLightData 4;
BA_ "SPN" SG_ 2566799614 TractorUndersideWorkLightData 2358;
BA_ "SigType" SG_ 2566799614 TractorUndersideWorkLightData 4;
BA_ "SPN" SG_ 2566799614 RearFogLightData 2390;
BA_ "SigType" SG_ 2566799614 RearFogLightData 4;
BA_ "SPN" SG_ 2566799614 TractorMarkerLightData 2378;
BA_ "SigType" SG_ 2566799614 TractorMarkerLightData 4;
BA_ "SPN" SG_ 2566799614 ImplementMarkerLightData 2380;
BA_ "SigType" SG_ 2566799614 ImplementMarkerLightData 4;
BA_ "SPN" SG_ 2566799614 TractorClearanceLightData 2382;
BA_ "SigType" SG_ 2566799614 TractorClearanceLightData 4;
BA_ "SPN" SG_ 2566799614 ImplementClearanceLightData 2384;
BA_ "SigType" SG_ 2566799614 ImplementClearanceLightData 4;
BA_ "SPN" SG_ 2566799614 LefttStopLightData 2372;
BA_ "SigType" SG_ 2566799614 LefttStopLightData 4;
BA_ "SPN" SG_ 2566799614 RightStopLightData 2374;
BA_ "SigType" SG_ 2566799614 RightStopLightData 4;
BA_ "SPN" SG_ 2566799614 CentreStopLightData 2376;
BA_ "SigType" SG_ 2566799614 CentreStopLightData 4;
BA_ "SPN" SG_ 2566799614 BackUpLightAndAlarmHornData 2392;
BA_ "SigType" SG_ 2566799614 BackUpLightAndAlarmHornData 4;
BA_ "SPN" SG_ 2566799614 LeftTurnSignalLightData 2368;
BA_ "SigType" SG_ 2566799614 LeftTurnSignalLightData 4;
BA_ "SPN" SG_ 2566799614 RightTurnSignalLightData 2370;
BA_ "SigType" SG_ 2566799614 RightTurnSignalLightData 4;
BA_ "SPN" SG_ 2566799614 RotationBeaconLightData 2386;
BA_ "SigType" SG_ 2566799614 RotationBeaconLightData 4;
BA_ "SPN" SG_ 2566799614 TractorFrontFogLightData 2388;
BA_ "SigType" SG_ 2566799614 TractorFrontFogLightData 4;
BA_ "SPN" SG_ 2566799614 HighBeamHeadLightData 2348;
BA_ "SigType" SG_ 2566799614 HighBeamHeadLightData 4;
BA_ "SPN" SG_ 2566799614 LowBeamHeadLightData 2350;
BA_ "SigType" SG_ 2566799614 LowBeamHeadLightData 4;
BA_ "SPN" SG_ 2566799614 AlternateHeadLightData 2352;
BA_ "SigType" SG_ 2566799614 AlternateHeadLightData 4;
BA_ "SPN" SG_ 2566799614 DaytimeRunningLightData 2404;
BA_ "SigType" SG_ 2566799614 DaytimeRunningLightData 4;
BA_ "SPN" SG_ 2365472766 Valve15FailSaveModeCmd 2345;
BA_ "SigType" SG_ 2365472766 Valve15FailSaveModeCmd 4;
BA_ "SPN" SG_ 2365472766 Valve15StateCmd 2344;
BA_ "SPN" SG_ 2365472766 Valve15PortFlowCmd 2343;
BA_ "SigType" SG_ 2365472766 Valve15PortFlowCmd 1;
BA_ "SPN" SG_ 2365472510 Valve14FailSaveModeCmd 2333;
BA_ "SigType" SG_ 2365472510 Valve14FailSaveModeCmd 4;
BA_ "SPN" SG_ 2365472510 Valve14StateCmd 2332;
BA_ "SPN" SG_ 2365472510 Valve14PortFlowCmd 2331;
BA_ "SigType" SG_ 2365472510 Valve14PortFlowCmd 1;
BA_ "SPN" SG_ 2365472254 Valve13FailSaveModeCmd 2321;
BA_ "SigType" SG_ 2365472254 Valve13FailSaveModeCmd 4;
BA_ "SPN" SG_ 2365472254 Valve13StateCmd 2320;
BA_ "SPN" SG_ 2365472254 Valve13PortFlowCmd 2319;
BA_ "SigType" SG_ 2365472254 Valve13PortFlowCmd 1;
BA_ "SPN" SG_ 2365471998 Valve12FailSaveModeCmd 2309;
BA_ "SigType" SG_ 2365471998 Valve12FailSaveModeCmd 4;
BA_ "SPN" SG_ 2365471998 Valve12StateCmd 2308;
BA_ "SPN" SG_ 2365471998 Valve12PortFlowCmd 2307;
BA_ "SigType" SG_ 2365471998 Valve12PortFlowCmd 1;
BA_ "SPN" SG_ 2365471742 Valve11FailSaveModeCmd 2297;
BA_ "SigType" SG_ 2365471742 Valve11FailSaveModeCmd 4;
BA_ "SPN" SG_ 2365471742 Valve11StateCmd 2296;
BA_ "SPN" SG_ 2365471742 Valve11PortFlowCmd 2295;
BA_ "SigType" SG_ 2365471742 Valve11PortFlowCmd 1;
BA_ "SPN" SG_ 2365471486 Valve10FailSaveModeCmd 2285;
BA_ "SigType" SG_ 2365471486 Valve10FailSaveModeCmd 4;
BA_ "SPN" SG_ 2365471486 Valve10StateCmd 2284;
BA_ "SPN" SG_ 2365471486 Valve10PortFlowCmd 2283;
BA_ "SigType" SG_ 2365471486 Valve10PortFlowCmd 1;
BA_ "SPN" SG_ 2365471230 Valve9FailSaveModeCmd 2273;
BA_ "SigType" SG_ 2365471230 Valve9FailSaveModeCmd 4;
BA_ "SPN" SG_ 2365471230 Valve9StateCmd 2272;
BA_ "SPN" SG_ 2365471230 Valve9PortFlowCmd 2271;
BA_ "SigType" SG_ 2365471230 Valve9PortFlowCmd 1;
BA_ "SPN" SG_ 2365470974 Valve8FailSaveModeCmd 2261;
BA_ "SigType" SG_ 2365470974 Valve8FailSaveModeCmd 4;
BA_ "SPN" SG_ 2365470974 Valve8StateCmd 2260;
BA_ "SPN" SG_ 2365470974 Valve8PortFlowCmd 2259;
BA_ "SigType" SG_ 2365470974 Valve8PortFlowCmd 1;
BA_ "SPN" SG_ 2365470718 Valve7FailSaveModeCmd 1993;
BA_ "SigType" SG_ 2365470718 Valve7FailSaveModeCmd 4;
BA_ "SPN" SG_ 2365470718 Valve7StateCmd 1992;
BA_ "SPN" SG_ 2365470718 Valve7PortFlowCmd 1991;
BA_ "SigType" SG_ 2365470718 Valve7PortFlowCmd 1;
BA_ "SPN" SG_ 2365470462 Valve6FailSaveModeCmd 1981;
BA_ "SigType" SG_ 2365470462 Valve6FailSaveModeCmd 4;
BA_ "SPN" SG_ 2365470462 Valve6StateCmd 1980;
BA_ "SPN" SG_ 2365470462 Valve6PortFlowCmd 1979;
BA_ "SigType" SG_ 2365470462 Valve6PortFlowCmd 1;
BA_ "SPN" SG_ 2365470206 Valve5FailSaveModeCmd 1969;
BA_ "SigType" SG_ 2365470206 Valve5FailSaveModeCmd 4;
BA_ "SPN" SG_ 2365470206 Valve5StateCmd 1968;
BA_ "SPN" SG_ 2365470206 Valve5PortFlowCmd 1967;
BA_ "SigType" SG_ 2365470206 Valve5PortFlowCmd 1;
BA_ "SPN" SG_ 2365469950 Valve4FailSaveModeCmd 1957;
BA_ "SigType" SG_ 2365469950 Valve4FailSaveModeCmd 4;
BA_ "SPN" SG_ 2365469950 Valve4StateCmd 1956;
BA_ "SPN" SG_ 2365469950 Valve4PortFlowCmd 1955;
BA_ "SigType" SG_ 2365469950 Valve4PortFlowCmd 1;
BA_ "SPN" SG_ 2365469694 Valve3FailSaveModeCmd 1945;
BA_ "SigType" SG_ 2365469694 Valve3FailSaveModeCmd 4;
BA_ "SPN" SG_ 2365469694 Valve3StateCmd 1944;
BA_ "SPN" SG_ 2365469694 Valve3PortFlowCmd 1943;
BA_ "SigType" SG_ 2365469694 Valve3PortFlowCmd 1;
BA_ "SPN" SG_ 2365469438 Valve2FailSaveModeCmd 1933;
BA_ "SigType" SG_ 2365469438 Valve2FailSaveModeCmd 4;
BA_ "SPN" SG_ 2365469438 Valve2StateCmd 1932;
BA_ "SPN" SG_ 2365469438 Valve2PortFlowCmd 1931;
BA_ "SigType" SG_ 2365469438 Valve2PortFlowCmd 1;
BA_ "SigType" SG_ 2365469182 Valve1FailSaveModeCmd 4;
BA_ "SPN" SG_ 2365469182 Valve1StateCmd 1920;
BA_ "SPN" SG_ 2365469182 Valve1PortFlowCmd 1919;
BA_ "SigType" SG_ 2365469182 Valve1PortFlowCmd 1;
BA_ "SPN" SG_ 2365468926 Valve0FailSaveModeCmd 1909;
BA_ "SigType" SG_ 2365468926 Valve0FailSaveModeCmd 4;
BA_ "SPN" SG_ 2365468926 Valve0StateCmd 1908;
BA_ "SPN" SG_ 2365468926 Valve0PortFlowCmd 1907;
BA_ "SigType" SG_ 2365468926 Valve0PortFlowCmd 1;
BA_ "SPN" SG_ 2365468670 Valve15LimitStatus 5190;
BA_ "SPN" SG_ 2365468670 Valve15ReturnPortPressure 2342;
BA_ "SigType" SG_ 2365468670 Valve15ReturnPortPressure 1;
BA_ "SPN" SG_ 2365468670 Valve15RetractPortPressure 2341;
BA_ "SigType" SG_ 2365468670 Valve15RetractPortPressure 1;
BA_ "SPN" SG_ 2365468670 Valve15ExtendedPortPressure 2340;
BA_ "SigType" SG_ 2365468670 Valve15ExtendedPortPressure 1;
BA_ "SPN" SG_ 2365468670 Valve15RetractPortMeasuredFlow 2336;
BA_ "SigType" SG_ 2365468670 Valve15RetractPortMeasuredFlow 1;
BA_ "SPN" SG_ 2365468670 Valve15ExtendedPortMeasuredFlow 2335;
BA_ "SigType" SG_ 2365468670 Valve15ExtendedPortMeasuredFlow 1;
BA_ "SPN" SG_ 2365468414 Valve14LimitStatus 5188;
BA_ "SPN" SG_ 2365468414 Valve14ReturnPortPressure 2330;
BA_ "SigType" SG_ 2365468414 Valve14ReturnPortPressure 1;
BA_ "SPN" SG_ 2365468414 Valve14RetractPortPressure 2329;
BA_ "SigType" SG_ 2365468414 Valve14RetractPortPressure 1;
BA_ "SPN" SG_ 2365468414 Valve14ExtendedPortPressure 2328;
BA_ "SigType" SG_ 2365468414 Valve14ExtendedPortPressure 1;
BA_ "SPN" SG_ 2365468414 Valve14RetractPortMeasuredFlow 2324;
BA_ "SigType" SG_ 2365468414 Valve14RetractPortMeasuredFlow 1;
BA_ "SPN" SG_ 2365468414 Valve14ExtendedPortMeasuredFlow 2323;
BA_ "SigType" SG_ 2365468414 Valve14ExtendedPortMeasuredFlow 1;
BA_ "SPN" SG_ 2365468158 Valve13LimitStatus 5186;
BA_ "SPN" SG_ 2365468158 Valve13ReturnPortPressure 2318;
BA_ "SigType" SG_ 2365468158 Valve13ReturnPortPressure 1;
BA_ "SPN" SG_ 2365468158 Valve13RetractPortPressure 2317;
BA_ "SigType" SG_ 2365468158 Valve13RetractPortPressure 1;
BA_ "SPN" SG_ 2365468158 Valve13ExtendedPortPressure 2316;
BA_ "SigType" SG_ 2365468158 Valve13ExtendedPortPressure 1;
BA_ "SPN" SG_ 2365468158 Valve13RetractPortMeasuredFlow 2312;
BA_ "SigType" SG_ 2365468158 Valve13RetractPortMeasuredFlow 1;
BA_ "SPN" SG_ 2365468158 Valve13ExtendedPortMeasuredFlow 2311;
BA_ "SigType" SG_ 2365468158 Valve13ExtendedPortMeasuredFlow 1;
BA_ "SPN" SG_ 2365467902 Valve12LimitStatus 5184;
BA_ "SPN" SG_ 2365467902 Valve12ReturnPortPressure 2306;
BA_ "SigType" SG_ 2365467902 Valve12ReturnPortPressure 1;
BA_ "SPN" SG_ 2365467902 Valve12RetractPortPressure 2305;
BA_ "SigType" SG_ 2365467902 Valve12RetractPortPressure 1;
BA_ "SPN" SG_ 2365467902 Valve12ExtendedPortPressure 2304;
BA_ "SigType" SG_ 2365467902 Valve12ExtendedPortPressure 1;
BA_ "SPN" SG_ 2365467902 Valve12RetractPortMeasuredFlow 2300;
BA_ "SigType" SG_ 2365467902 Valve12RetractPortMeasuredFlow 1;
BA_ "SPN" SG_ 2365467902 Valve12ExtendedPortMeasuredFlow 2299;
BA_ "SigType" SG_ 2365467902 Valve12ExtendedPortMeasuredFlow 1;
BA_ "SPN" SG_ 2365467646 Valve11LimitStatus 5182;
BA_ "SPN" SG_ 2365467646 Valve11ReturnPortPressure 2294;
BA_ "SigType" SG_ 2365467646 Valve11ReturnPortPressure 1;
BA_ "SPN" SG_ 2365467646 Valve11RetractPortPressure 2293;
BA_ "SigType" SG_ 2365467646 Valve11RetractPortPressure 1;
BA_ "SPN" SG_ 2365467646 Valve11ExtendedPortPressure 2292;
BA_ "SigType" SG_ 2365467646 Valve11ExtendedPortPressure 1;
BA_ "SPN" SG_ 2365467646 Valve11RetractPortMeasuredFlow 2288;
BA_ "SigType" SG_ 2365467646 Valve11RetractPortMeasuredFlow 1;
BA_ "SPN" SG_ 2365467646 Valve11ExtendedPortMeasuredFlow 2287;
BA_ "SigType" SG_ 2365467646 Valve11ExtendedPortMeasuredFlow 1;
BA_ "SPN" SG_ 2365467390 Valve10LimitStatus 5180;
BA_ "SPN" SG_ 2365467390 Valve10ReturnPortPressure 2282;
BA_ "SigType" SG_ 2365467390 Valve10ReturnPortPressure 1;
BA_ "SPN" SG_ 2365467390 Valve10RetractPortPressure 2281;
BA_ "SigType" SG_ 2365467390 Valve10RetractPortPressure 1;
BA_ "SPN" SG_ 2365467390 Valve10ExtendedPortPressure 2280;
BA_ "SigType" SG_ 2365467390 Valve10ExtendedPortPressure 1;
BA_ "SPN" SG_ 2365467390 Valve10RetractPortMeasuredFlow 2276;
BA_ "SigType" SG_ 2365467390 Valve10RetractPortMeasuredFlow 1;
BA_ "SPN" SG_ 2365467390 Valve10ExtendedPortMeasuredFlow 2275;
BA_ "SigType" SG_ 2365467390 Valve10ExtendedPortMeasuredFlow 1;
BA_ "SPN" SG_ 2365467134 Valve9LimitStatus 5178;
BA_ "SPN" SG_ 2365467134 Valve9ReturnPortPressure 2270;
BA_ "SigType" SG_ 2365467134 Valve9ReturnPortPressure 1;
BA_ "SPN" SG_ 2365467134 Valve9RetractPortPressure 2269;
BA_ "SigType" SG_ 2365467134 Valve9RetractPortPressure 1;
BA_ "SPN" SG_ 2365467134 Valve9ExtendedPortPressure 2268;
BA_ "SigType" SG_ 2365467134 Valve9ExtendedPortPressure 1;
BA_ "SPN" SG_ 2365467134 Valve9RetractPortMeasuredFlow 2264;
BA_ "SigType" SG_ 2365467134 Valve9RetractPortMeasuredFlow 1;
BA_ "SPN" SG_ 2365467134 Valve9ExtendedPortMeasuredFlow 2263;
BA_ "SigType" SG_ 2365467134 Valve9ExtendedPortMeasuredFlow 1;
BA_ "SPN" SG_ 2365466878 Valve8LimitStatus 5176;
BA_ "SPN" SG_ 2365466878 Valve8ReturnPortPressure 2258;
BA_ "SigType" SG_ 2365466878 Valve8ReturnPortPressure 1;
BA_ "SPN" SG_ 2365466878 Valve8RetractPortPressure 2257;
BA_ "SigType" SG_ 2365466878 Valve8RetractPortPressure 1;
BA_ "SPN" SG_ 2365466878 Valve8ExtendedPortPressure 2256;
BA_ "SigType" SG_ 2365466878 Valve8ExtendedPortPressure 1;
BA_ "SPN" SG_ 2365466878 Valve8RetractPortMeasuredFlow 1996;
BA_ "SigType" SG_ 2365466878 Valve8RetractPortMeasuredFlow 1;
BA_ "SPN" SG_ 2365466878 Valve8ExtendedPortMeasuredFlow 1995;
BA_ "SigType" SG_ 2365466878 Valve8ExtendedPortMeasuredFlow 1;
BA_ "SPN" SG_ 2365466622 Valve7LimitStatus 5174;
BA_ "SPN" SG_ 2365466622 Valve7ReturnPortPressure 1990;
BA_ "SigType" SG_ 2365466622 Valve7ReturnPortPressure 1;
BA_ "SPN" SG_ 2365466622 Valve7RetractPortPressure 1989;
BA_ "SigType" SG_ 2365466622 Valve7RetractPortPressure 1;
BA_ "SPN" SG_ 2365466622 Valve7ExtendedPortPressure 1988;
BA_ "SigType" SG_ 2365466622 Valve7ExtendedPortPressure 1;
BA_ "SPN" SG_ 2365466622 Valve7RetractPortMeasuredFlow 1984;
BA_ "SigType" SG_ 2365466622 Valve7RetractPortMeasuredFlow 1;
BA_ "SPN" SG_ 2365466622 Valve7ExtendedPortMeasuredFlow 1983;
BA_ "SigType" SG_ 2365466622 Valve7ExtendedPortMeasuredFlow 1;
BA_ "SPN" SG_ 2365466366 Valve6LimitStatus 5172;
BA_ "SPN" SG_ 2365466366 Valve6ReturnPortPressure 1978;
BA_ "SigType" SG_ 2365466366 Valve6ReturnPortPressure 1;
BA_ "SPN" SG_ 2365466366 Valve6RetractPortPressure 1977;
BA_ "SigType" SG_ 2365466366 Valve6RetractPortPressure 1;
BA_ "SPN" SG_ 2365466366 Valve6ExtendedPortPressure 1976;
BA_ "SigType" SG_ 2365466366 Valve6ExtendedPortPressure 1;
BA_ "SPN" SG_ 2365466366 Valve6RetractPortMeasuredFlow 1972;
BA_ "SigType" SG_ 2365466366 Valve6RetractPortMeasuredFlow 1;
BA_ "SPN" SG_ 2365466366 Valve6ExtendedPortMeasuredFlow 1971;
BA_ "SigType" SG_ 2365466366 Valve6ExtendedPortMeasuredFlow 1;
BA_ "SPN" SG_ 2365466110 Valve5LimitStatus 5170;
BA_ "SPN" SG_ 2365466110 Valve5ReturnPortPressure 1966;
BA_ "SigType" SG_ 2365466110 Valve5ReturnPortPressure 1;
BA_ "SPN" SG_ 2365466110 Valve5RetractPortPressure 1965;
BA_ "SigType" SG_ 2365466110 Valve5RetractPortPressure 1;
BA_ "SPN" SG_ 2365466110 Valve5ExtendedPortPressure 1964;
BA_ "SigType" SG_ 2365466110 Valve5ExtendedPortPressure 1;
BA_ "SPN" SG_ 2365466110 Valve5RetractPortMeasuredFlow 1960;
BA_ "SigType" SG_ 2365466110 Valve5RetractPortMeasuredFlow 1;
BA_ "SPN" SG_ 2365466110 Valve5ExtendedPortMeasuredFlow 1959;
BA_ "SigType" SG_ 2365466110 Valve5ExtendedPortMeasuredFlow 1;
BA_ "SPN" SG_ 2365465854 Valve4LimitStatus 5168;
BA_ "SPN" SG_ 2365465854 Valve4ReturnPortPressure 1954;
BA_ "SigType" SG_ 2365465854 Valve4ReturnPortPressure 1;
BA_ "SPN" SG_ 2365465854 Valve4RetractPortPressure 1953;
BA_ "SigType" SG_ 2365465854 Valve4RetractPortPressure 1;
BA_ "SPN" SG_ 2365465854 Valve4ExtendedPortPressure 1952;
BA_ "SigType" SG_ 2365465854 Valve4ExtendedPortPressure 1;
BA_ "SPN" SG_ 2365465854 Valve4RetractPortMeasuredFlow 1948;
BA_ "SigType" SG_ 2365465854 Valve4RetractPortMeasuredFlow 1;
BA_ "SPN" SG_ 2365465854 Valve4ExtendedPortMeasuredFlow 1947;
BA_ "SigType" SG_ 2365465854 Valve4ExtendedPortMeasuredFlow 1;
BA_ "SPN" SG_ 2365465598 Valve3LimitStatus 5166;
BA_ "SPN" SG_ 2365465598 Valve3ReturnPortPressure 1942;
BA_ "SigType" SG_ 2365465598 Valve3ReturnPortPressure 1;
BA_ "SPN" SG_ 2365465598 Valve3RetractPortPressure 1941;
BA_ "SigType" SG_ 2365465598 Valve3RetractPortPressure 1;
BA_ "SPN" SG_ 2365465598 Valve3ExtendedPortPressure 1940;
BA_ "SigType" SG_ 2365465598 Valve3ExtendedPortPressure 1;
BA_ "SPN" SG_ 2365465598 Valve3RetractPortMeasuredFlow 1936;
BA_ "SigType" SG_ 2365465598 Valve3RetractPortMeasuredFlow 1;
BA_ "SPN" SG_ 2365465598 Valve3ExtendedPortMeasuredFlow 1935;
BA_ "SigType" SG_ 2365465598 Valve3ExtendedPortMeasuredFlow 1;
BA_ "SPN" SG_ 2365465342 Valve2LimitStatus 5164;
BA_ "SPN" SG_ 2365465342 Valve2ReturnPortPressure 1930;
BA_ "SigType" SG_ 2365465342 Valve2ReturnPortPressure 1;
BA_ "SPN" SG_ 2365465342 Valve2RetractPortPressure 1929;
BA_ "SigType" SG_ 2365465342 Valve2RetractPortPressure 1;
BA_ "SPN" SG_ 2365465342 Valve2ExtendedPortPressure 1928;
BA_ "SigType" SG_ 2365465342 Valve2ExtendedPortPressure 1;
BA_ "SPN" SG_ 2365465342 Valve2RetractPortMeasuredFlow 1924;
BA_ "SigType" SG_ 2365465342 Valve2RetractPortMeasuredFlow 1;
BA_ "SPN" SG_ 2365465342 Valve2ExtendedPortMeasuredFlow 1923;
BA_ "SigType" SG_ 2365465342 Valve2ExtendedPortMeasuredFlow 1;
BA_ "SPN" SG_ 2365465086 Valve1LimitStatus 5162;
BA_ "SPN" SG_ 2365465086 Valve1ReturnPortPressure 1918;
BA_ "SigType" SG_ 2365465086 Valve1ReturnPortPressure 1;
BA_ "SPN" SG_ 2365465086 Valve1RetractPortPressure 1917;
BA_ "SigType" SG_ 2365465086 Valve1RetractPortPressure 1;
BA_ "SPN" SG_ 2365465086 Valve1ExtendedPortPressure 1916;
BA_ "SigType" SG_ 2365465086 Valve1ExtendedPortPressure 1;
BA_ "SPN" SG_ 2365465086 Valve1RetractPortMeasuredFlow 1912;
BA_ "SigType" SG_ 2365465086 Valve1RetractPortMeasuredFlow 1;
BA_ "SPN" SG_ 2365465086 Valve1ExtendedPortMeasuredFlow 1911;
BA_ "SigType" SG_ 2365465086 Valve1ExtendedPortMeasuredFlow 1;
BA_ "SPN" SG_ 2365464830 Valve0LimitStatus 5160;
BA_ "SPN" SG_ 2365464830 Valve0ReturnPortPressure 1906;
BA_ "SigType" SG_ 2365464830 Valve0ReturnPortPressure 1;
BA_ "SPN" SG_ 2365464830 Valve0RetractPortPressure 1905;
BA_ "SigType" SG_ 2365464830 Valve0RetractPortPressure 1;
BA_ "SPN" SG_ 2365464830 Valve0ExtendedPortPressure 1904;
BA_ "SigType" SG_ 2365464830 Valve0ExtendedPortPressure 1;
BA_ "SigType" SG_ 2365464830 Valve0RetractPortMeasuredFlow 1;
BA_ "SPN" SG_ 2365464830 Valve0RetractPortMeasuredFlow 1900;
BA_ "SigType" SG_ 2365464830 Valve0ExtendedPortMeasuredFlow 1;
BA_ "SPN" SG_ 2365464830 Valve0ExtendedPortMeasuredFlow 1899;
BA_ "SPN" SG_ 2365464574 AuxValve15ExitReasonCode 5815;
BA_ "SPN" SG_ 2365464574 Valve15LimitStatus 5191;
BA_ "SPN" SG_ 2365464574 Valve15FailSafeMode 2346;
BA_ "SigType" SG_ 2365464574 Valve15FailSafeMode 4;
BA_ "SPN" SG_ 2365464574 Valve15ValveState 2339;
BA_ "SPN" SG_ 2365464574 Valve15RetractPortEstimatedFlow 2338;
BA_ "SigType" SG_ 2365464574 Valve15RetractPortEstimatedFlow 1;
BA_ "SPN" SG_ 2365464574 Valve15ExtendedPortEstimatedFlow 2337;
BA_ "SigType" SG_ 2365464574 Valve15ExtendedPortEstimatedFlow 1;
BA_ "SPN" SG_ 2365464318 Valve14LimitStatus 5189;
BA_ "SPN" SG_ 2365464318 Valve14FailSafeMode 2334;
BA_ "SigType" SG_ 2365464318 Valve14FailSafeMode 4;
BA_ "SPN" SG_ 2365464318 Valve14ValveState 2327;
BA_ "SPN" SG_ 2365464318 Valve14RetractPortEstimatedFlow 2326;
BA_ "SigType" SG_ 2365464318 Valve14RetractPortEstimatedFlow 1;
BA_ "SPN" SG_ 2365464318 Valve14ExtendedPortEstimatedFlow 2325;
BA_ "SigType" SG_ 2365464318 Valve14ExtendedPortEstimatedFlow 1;
BA_ "SPN" SG_ 2365464062 Valve13LimitStatus 5187;
BA_ "SPN" SG_ 2365464062 Valve13FailSafeMode 2322;
BA_ "SigType" SG_ 2365464062 Valve13FailSafeMode 4;
BA_ "SPN" SG_ 2365464062 Valve13ValveState 2315;
BA_ "SPN" SG_ 2365464062 Valve13RetractPortEstimatedFlow 2314;
BA_ "SigType" SG_ 2365464062 Valve13RetractPortEstimatedFlow 1;
BA_ "SPN" SG_ 2365464062 Valve13ExtendedPortEstimatedFlow 2313;
BA_ "SigType" SG_ 2365464062 Valve13ExtendedPortEstimatedFlow 1;
BA_ "SPN" SG_ 2365463806 Valve12LimitStatus 5185;
BA_ "SPN" SG_ 2365463806 Valve12FailSafeMode 2310;
BA_ "SigType" SG_ 2365463806 Valve12FailSafeMode 4;
BA_ "SPN" SG_ 2365463806 Valve12ValveState 2303;
BA_ "SPN" SG_ 2365463806 Valve12RetractPortEstimatedFlow 2302;
BA_ "SigType" SG_ 2365463806 Valve12RetractPortEstimatedFlow 1;
BA_ "SPN" SG_ 2365463806 Valve12ExtendedPortEstimatedFlow 2301;
BA_ "SigType" SG_ 2365463806 Valve12ExtendedPortEstimatedFlow 1;
BA_ "SPN" SG_ 2365463550 Valve11LimitStatus 5183;
BA_ "SPN" SG_ 2365463550 Valve11FailSafeMode 2298;
BA_ "SigType" SG_ 2365463550 Valve11FailSafeMode 4;
BA_ "SPN" SG_ 2365463550 Valve11ValveState 2291;
BA_ "SPN" SG_ 2365463550 Valve11RetractPortEstimatedFlow 2290;
BA_ "SigType" SG_ 2365463550 Valve11RetractPortEstimatedFlow 1;
BA_ "SPN" SG_ 2365463550 Valve11ExtendedPortEstimatedFlow 2289;
BA_ "SigType" SG_ 2365463550 Valve11ExtendedPortEstimatedFlow 1;
BA_ "SPN" SG_ 2365463294 Valve10LimitStatus 5181;
BA_ "SPN" SG_ 2365463294 Valve10FailSafeMode 2286;
BA_ "SigType" SG_ 2365463294 Valve10FailSafeMode 4;
BA_ "SPN" SG_ 2365463294 Valve10ValveState 2279;
BA_ "SPN" SG_ 2365463294 Valve10RetractPortEstimatedFlow 2278;
BA_ "SigType" SG_ 2365463294 Valve10RetractPortEstimatedFlow 1;
BA_ "SPN" SG_ 2365463294 Valve10ExtendedPortEstimatedFlow 2277;
BA_ "SigType" SG_ 2365463294 Valve10ExtendedPortEstimatedFlow 1;
BA_ "SPN" SG_ 2365463038 Valve9LimitStatus 5179;
BA_ "SPN" SG_ 2365463038 Valve9FailSafeMode 2274;
BA_ "SigType" SG_ 2365463038 Valve9FailSafeMode 4;
BA_ "SPN" SG_ 2365463038 Valve9ValveState 2267;
BA_ "SPN" SG_ 2365463038 Valve9RetractPortEstimatedFlow 2266;
BA_ "SigType" SG_ 2365463038 Valve9RetractPortEstimatedFlow 1;
BA_ "SPN" SG_ 2365463038 Valve9ExtendedPortEstimatedFlow 2265;
BA_ "SigType" SG_ 2365463038 Valve9ExtendedPortEstimatedFlow 1;
BA_ "SPN" SG_ 2365462782 Valve8LimitStatus 5177;
BA_ "SPN" SG_ 2365462782 Valve8FailSafeMode 2262;
BA_ "SigType" SG_ 2365462782 Valve8FailSafeMode 4;
BA_ "SPN" SG_ 2365462782 Valve8ValveState 1999;
BA_ "SPN" SG_ 2365462782 Valve8RetractPortEstimatedFlow 1998;
BA_ "SigType" SG_ 2365462782 Valve8RetractPortEstimatedFlow 1;
BA_ "SPN" SG_ 2365462782 Valve8ExtendedPortEstimatedFlow 1997;
BA_ "SigType" SG_ 2365462782 Valve8ExtendedPortEstimatedFlow 1;
BA_ "SPN" SG_ 2365462526 Valve7LimitStatus 5175;
BA_ "SPN" SG_ 2365462526 Valve7FailSafeMode 1994;
BA_ "SigType" SG_ 2365462526 Valve7FailSafeMode 4;
BA_ "SPN" SG_ 2365462526 Valve7ValveState 1987;
BA_ "SPN" SG_ 2365462526 Valve7RetractPortEstimatedFlow 1986;
BA_ "SigType" SG_ 2365462526 Valve7RetractPortEstimatedFlow 1;
BA_ "SPN" SG_ 2365462526 Valve7ExtendedPortEstimatedFlow 1985;
BA_ "SigType" SG_ 2365462526 Valve7ExtendedPortEstimatedFlow 1;
BA_ "SPN" SG_ 2365462270 Valve6LimitStatus 5173;
BA_ "SPN" SG_ 2365462270 Valve6FailSafeMode 1982;
BA_ "SigType" SG_ 2365462270 Valve6FailSafeMode 4;
BA_ "SPN" SG_ 2365462270 Valve6ValveState 1975;
BA_ "SPN" SG_ 2365462270 Valve6RetractPortEstimatedFlow 1974;
BA_ "SigType" SG_ 2365462270 Valve6RetractPortEstimatedFlow 1;
BA_ "SPN" SG_ 2365462270 Valve6ExtendedPortEstimatedFlow 1973;
BA_ "SigType" SG_ 2365462270 Valve6ExtendedPortEstimatedFlow 1;
BA_ "SPN" SG_ 2365462014 Valve5LimitStatus 5171;
BA_ "SPN" SG_ 2365462014 Valve5FailSafeMode 1970;
BA_ "SigType" SG_ 2365462014 Valve5FailSafeMode 4;
BA_ "SPN" SG_ 2365462014 Valve5ValveState 1963;
BA_ "SPN" SG_ 2365462014 Valve5RetractPortEstimatedFlow 1962;
BA_ "SigType" SG_ 2365462014 Valve5RetractPortEstimatedFlow 1;
BA_ "SPN" SG_ 2365462014 Valve5ExtendedPortEstimatedFlow 1961;
BA_ "SigType" SG_ 2365462014 Valve5ExtendedPortEstimatedFlow 1;
BA_ "SPN" SG_ 2365461758 Valve4LimitStatus 5169;
BA_ "SPN" SG_ 2365461758 Valve4FailSafeMode 1958;
BA_ "SigType" SG_ 2365461758 Valve4FailSafeMode 4;
BA_ "SPN" SG_ 2365461758 Valve4ValveState 1951;
BA_ "SPN" SG_ 2365461758 Valve4RetractPortEstimatedFlow 1950;
BA_ "SigType" SG_ 2365461758 Valve4RetractPortEstimatedFlow 1;
BA_ "SPN" SG_ 2365461758 Valve4ExtendedPortEstimatedFlow 1949;
BA_ "SigType" SG_ 2365461758 Valve4ExtendedPortEstimatedFlow 1;
BA_ "SPN" SG_ 2365461502 Valve3LimitStatus 5167;
BA_ "SPN" SG_ 2365461502 Valve3FailSafeMode 1946;
BA_ "SigType" SG_ 2365461502 Valve3FailSafeMode 4;
BA_ "SPN" SG_ 2365461502 Valve3ValveState 1939;
BA_ "SPN" SG_ 2365461502 Valve3RetractPortEstimatedFlow 1938;
BA_ "SigType" SG_ 2365461502 Valve3RetractPortEstimatedFlow 1;
BA_ "SPN" SG_ 2365461502 Valve3ExtendedPortEstimatedFlow 1937;
BA_ "SigType" SG_ 2365461502 Valve3ExtendedPortEstimatedFlow 1;
BA_ "SPN" SG_ 2365461246 Valve2LimitStatus 5165;
BA_ "SPN" SG_ 2365461246 Valve2FailSafeMode 1934;
BA_ "SigType" SG_ 2365461246 Valve2FailSafeMode 4;
BA_ "SPN" SG_ 2365461246 Valve2ValveState 1927;
BA_ "SPN" SG_ 2365461246 Valve2RetractPortEstimatedFlow 1926;
BA_ "SigType" SG_ 2365461246 Valve2RetractPortEstimatedFlow 1;
BA_ "SPN" SG_ 2365461246 Valve2ExtendedPortEstimatedFlow 1925;
BA_ "SigType" SG_ 2365461246 Valve2ExtendedPortEstimatedFlow 1;
VAL_ 2624585470 LwAPossible 1 "SetOrTrue" 0 "UnsetOrFalse" ;
VAL_ 2624585470 TestlabCertIsValid 1 "SetOrTrue" 0 "UnsetOrFalse" ;
VAL_ 2624585470 ReStartAuth 1 "SetOrTrue" 0 "UnsetOrFalse" ;
VAL_ 2624585470 ManufactSeriesCertIsValid 1 "SetOrTrue" 0 "UnsetOrFalse" ;
VAL_ 2624585470 ManufactCertIsValid 1 "SetOrTrue" 0 "UnsetOrFalse" ;
VAL_ 2624585470 DeviceCertIsValid 1 "SetOrTrue" 0 "UnsetOrFalse" ;
VAL_ 2624585470 ChallengeSigned 1 "SetOrTrue" 0 "UnsetOrFalse" ;
VAL_ 2624585470 AuthenticationStatus 15 "NotAvailable" 14 "Error" 1 "Authenticated" 0 "NotAuthenticated" ;
VAL_ 2624585470 ErrorCode 39 "LwAPossibleBitMismatch" 38 "AuthenticationAbortedDueToGeneralPeerError" 37 "AuthenticationAbortedByPeerDueToError" 36 "ChallengeDataCorrupt" 35 "InvalidChallengeLength" 34 "FunctionFacilityNotCertified" 33 "RequestNotAllowed" 32 "Reserved_0x20" 31 "AuthenticationTimeout" 30 "CertificateTypeInvalid" 29 "DeviceCertificateRevoked" 28 "ManufacturerSeriesCertificateRevoked" 27 "ManufacturerCertificateRevoked" 26 "LabCertificateRevoked" 25 "RootCertificateRevoked" 24 "CertificateTypeMismatch" 23 "CertificateChainInvalid" 22 "ECU_CCID_Mismatch" 21 "NAME_Mismatch" 20 "ECC_PublicKeyValidationFailed" 19 "UnexpectedRestartAuthenticationBitSet" 18 "AuthenticationStatusInvalid" 17 "AuthenticationTypeNotSupported" 16 "AuthenticationStatusLost" 15 "DeviceCertificateDataCorrupt" 14 "ManufacturerSeriesCertificateDataCorrupt" 13 "ManufacturerCertificateDataCorrupt" 12 "TestLabCertificateDataCorrupt" 11 "RootCertificateDataCorrupt" 10 "InternalError" 9 "ChallengesDontMatch" 8 "DeviceCertificateSignatureInvalid" 7 "ManufacturerSeriesCertificateSignatureInvalid" 6 "ManufacturerCertificateSignatureInvalid" 5 "LabCertificateSignatureInvalid" 4 "RootCertificateSignatureInvalid" 3 "NotAuthenticationServerOrClient" 2 "CertificateFormatNotSupported" 1 "ParticipantBusy" 0 "NoError" ;
VAL_ 2624585470 CertType 255 "NotAvailable" 6 "CRLCertificate" 5 "CRLSigningCertificate" 4 "DeviceCertificate" 3 "ManufacturerSeriesCertificate" 2 "ManufacturerCertificate" 1 "TestlabCertificate" 0 "AEFRootCertificate" ;
VAL_ 2624585470 CertificateFormat 255 "NotAvailable" 0 "DER_BinaryInASN_1" ;
VAL_ 2624585470 AuthenticationType 15 "NotAvailable" 14 "Error" 0 "TIM_Authentication" ;
VAL_ 2624585470 MessageCode 9 "ClientAuthenticationInfoResponse" 8 "ServerAuthenticationInfoRequest" 250 "ClientAuthenticationStatus" 7 "ClientSignedChallengeResponse" 6 "ServerSignedChallengeRequest" 5 "ClientRandomChallengeResponse" 4 "ServerRandomChallengeRequest" 3 "ClientCertificateResponse" 2 "ServerCertificateRequest" ;
VAL_ 2624651006 AuthenticationStatus 15 "NotAvailable" 14 "Error" 1 "Authenticated" 0 "NotAuthenticated" ;
VAL_ 2624651006 ChallengeSigned 1 "SetOrTrue" 0 "UnsetOrFalse" ;
VAL_ 2624651006 DeviceCertIsValid 1 "SetOrTrue" 0 "UnsetOrFalse" ;
VAL_ 2624651006 ManufactSeriesCertIsValid 1 "SetOrTrue" 0 "UnsetOrFalse" ;
VAL_ 2624651006 ManufactCertIsValid 1 "SetOrTrue" 0 "UnsetOrFalse" ;
VAL_ 2624651006 TestlabCertIsValid 1 "SetOrTrue" 0 "UnsetOrFalse" ;
VAL_ 2624651006 LwAPossible 1 "SetOrTrue" 0 "UnsetOrFalse" ;
VAL_ 2624651006 ReStartAuth 1 "SetOrTrue" 0 "UnsetOrFalse" ;
VAL_ 2624651006 CertType 255 "NotAvailable" 6 "CRLCertificate" 5 "CRLSigningCertificate" 4 "DeviceCertificate" 3 "ManufacturerSeriesCertificate" 2 "ManufacturerCertificate" 1 "TestlabCertificate" 0 "AEFRootCertificate" ;
VAL_ 2624651006 CertificateFormat 255 "NotAvailable" 0 "DER_BinaryInASN1" ;
VAL_ 2624651006 AuthenticationType 15 "NotAvailable" 14 "Error" 0 "TIM_Authentication" ;
VAL_ 2624651006 MessageCode 9 "ClientAuthenticationInfoRequest" 8 "ServerAuthenticationInfoResponse" 249 "ServerAuthenticationStatus" 7 "ClientSignedChallengeRequest" 6 "ServerSignedChallengeResponse" 5 "ClientRandomChallengeRequest" 4 "ServerRandomChallengeResponse" 3 "ClientCertificateRequest" 2 "ServerCertificateResponse" ;
VAL_ 2624651006 ErrorCode 39 "LwAPossibleBitMismatch" 38 "AuthenticationAbortedDueToGeneralPeerError" 37 "AuthenticationAbortedByPeerDueToError" 36 "ChallengeDataCorrupt" 35 "InvalidChallengeLength" 34 "FunctionFacilityNotCertified" 33 "RequestNotAllowed" 32 "Reserved_0x20" 31 "AuthenticationTimeout" 30 "CertificateTypeInvalid" 29 "DeviceCertificateRevoked" 28 "ManufacturerSeriesCertificateRevoked" 27 "ManufacturerCertificateRevoked" 26 "LabCertificateRevoked" 25 "RootCertificateRevoked" 24 "CertificateTypeMismatch" 23 "CertificateChainInvalid" 22 "ECU_CCID_Mismatch" 21 "NAME_Mismatch" 20 "ECC_PublicKeyValidationFailed" 19 "UnexpectedRestartAuthenticationBitSet" 18 "AuthenticationStatusInvalid" 17 "AuthenticationTypeNotSupported" 16 "AuthenticationStatusLost" 15 "DeviceCertificateDataCorrupt" 14 "ManufacturerSeriesCertificateDataCorrupt" 13 "ManufacturerCertificateDataCorrupt" 12 "TestLabCertificateDataCorrupt" 11 "RootCertificateDataCorrupt" 10 "InternalError" 9 "ChallengesDontMatch" 8 "DeviceCertificateSignatureInvalid" 7 "ManufacturerSeriesCertificateSignatureInvalid" 6 "ManufacturerCertificateSignatureInvalid" 5 "LabCertificateSignatureInvalid" 4 "RootCertificateSignatureInvalid" 3 "NotAuthenticationServerOrClient" 2 "CertificateFormatNotSupported" 1 "ParticipantBusy" 0 "NoError" ;
VAL_ 2619670270 CurvatureRequest 64511 "ReadyToControl" 64509 "RequestingOperatorAwareness" 32128 "Straight" ;
VAL_ 2619670270 VehicleSpeedRequest 64511 "ReadyToControl" 64510 "AcceptFunctionWithoutOperatorAwareness" 64509 "RequestingOperatorAwareness" 64256 "ForwardSpeedSetByTimServer" 32128 "Stop" 0 "ReverseSpeedSetByTimServer" ;
VAL_ 2619670270 HitchPosReq 10000 "FullRaise" 64259 "RaiseUntilStopRequest" 64258 "LowerUntilStopRequest" 0 "FullLower" 64511 "ReadyToControl" 64509 "ReleaseControlRequestingOperatorAction" 64257 "Stop" 64256 "Float" ;
VAL_ 2619670270 PTOSpeedRequest 64511 "ReadyToControl" 64509 "RequestingOperatorAction" 64256 "On_SpeedClockwiseSetByTimServer" 32128 "Off" 0 "On_SpeedCounterClockwiseSetByTimServer" ;
VAL_ 2619670270 RequestCounter 15 "NotAvailable_DontCare " 14 "Reserved" ;
VAL_ 2619670270 AuxValveFlowReq 64511 "ReadyToControl" 64509 "ReleasedControlRequestingOperatorActionBeforeFunctionValueIncreases" 64257 "Float" 64256 "ValveFullyOpened_Retract" 32128 "Block" 0 "ValveFullyOpened_Extend" ;
VAL_ 2619670270 TIMClientState 13 "AutomationFault" 5 "AutomationActive" 15 "NotAvailable" 14 "Error" 3 "AutomationEnabled" 2 "AutomationReadyToEnable" 1 "AutomationNotReady" 0 "AutomationUnavailable" ;
VAL_ 2619670270 ClientHearbeatCounter 255 "GracefulShutdown" 254 "ErrorConditionOnSender" 251 "ResetOfHeartbeatCounter" ;
VAL_ 2619670270 TIMFunctionId_4 32 "AuxValve32" 70 "ExternalGuidance" 68 "VehicleSpeed" 67 "RearHitch" 66 "FrontHitch" 65 "RearPTO" 64 "FrontPTO" 31 "AuxValve31" 30 "AuxValve30" 29 "AuxValve29" 28 "AuxValve28" 27 "AuxValve27" 26 "AuxValve26" 25 "AuxValve25" 24 "AuxValve24" 23 "AuxValve23" 22 "AuxValve22" 21 "AuxValve21" 20 "AuxValve20" 19 "AuxValve19" 18 "AuxValve18" 17 "AuxValve17" 16 "AuxValve16" 15 "AuxValve15" 14 "AuxValve14" 13 "AuxValve13" 12 "AuxValve12" 11 "AuxValve11" 10 "AuxValve10" 9 "AuxValve9" 8 "AuxValve8" 7 "AuxValve7" 6 "AuxValve6" 5 "AuxValve5" 4 "AuxValve4" 3 "AuxValve3" 2 "AuxValve2" 1 "AuxValve1" ;
VAL_ 2619670270 TIMFunctionId_3 32 "AuxValve32" 70 "ExternalGuidance" 68 "VehicleSpeed" 67 "RearHitch" 66 "FrontHitch" 65 "RearPTO" 64 "FrontPTO" 31 "AuxValve31" 30 "AuxValve30" 29 "AuxValve29" 28 "AuxValve28" 27 "AuxValve27" 26 "AuxValve26" 25 "AuxValve25" 24 "AuxValve24" 23 "AuxValve23" 22 "AuxValve22" 21 "AuxValve21" 20 "AuxValve20" 19 "AuxValve19" 18 "AuxValve18" 17 "AuxValve17" 16 "AuxValve16" 15 "AuxValve15" 14 "AuxValve14" 13 "AuxValve13" 12 "AuxValve12" 11 "AuxValve11" 10 "AuxValve10" 9 "AuxValve9" 8 "AuxValve8" 7 "AuxValve7" 6 "AuxValve6" 5 "AuxValve5" 4 "AuxValve4" 3 "AuxValve3" 2 "AuxValve2" 1 "AuxValve1" ;
VAL_ 2619670270 TIMFunctionId_2 32 "AuxValve32" 70 "ExternalGuidance" 68 "VehicleSpeed" 67 "RearHitch" 66 "FrontHitch" 65 "RearPTO" 64 "FrontPTO" 31 "AuxValve31" 30 "AuxValve30" 29 "AuxValve29" 28 "AuxValve28" 27 "AuxValve27" 26 "AuxValve26" 25 "AuxValve25" 24 "AuxValve24" 23 "AuxValve23" 22 "AuxValve22" 21 "AuxValve21" 20 "AuxValve20" 19 "AuxValve19" 18 "AuxValve18" 17 "AuxValve17" 16 "AuxValve16" 15 "AuxValve15" 14 "AuxValve14" 13 "AuxValve13" 12 "AuxValve12" 11 "AuxValve11" 10 "AuxValve10" 9 "AuxValve9" 8 "AuxValve8" 7 "AuxValve7" 6 "AuxValve6" 5 "AuxValve5" 4 "AuxValve4" 3 "AuxValve3" 2 "AuxValve2" 1 "AuxValve1" ;
VAL_ 2619670270 TIMFunctionId_1 32 "AuxValve32" 70 "ExternalGuidance" 68 "VehicleSpeed" 67 "RearHitch" 66 "FrontHitch" 65 "RearPTO" 64 "FrontPTO" 31 "AuxValve31" 30 "AuxValve30" 29 "AuxValve29" 28 "AuxValve28" 27 "AuxValve27" 26 "AuxValve26" 25 "AuxValve25" 24 "AuxValve24" 23 "AuxValve23" 22 "AuxValve22" 21 "AuxValve21" 20 "AuxValve20" 19 "AuxValve19" 18 "AuxValve18" 17 "AuxValve17" 16 "AuxValve16" 15 "AuxValve15" 14 "AuxValve14" 13 "AuxValve13" 12 "AuxValve12" 11 "AuxValve11" 10 "AuxValve10" 9 "AuxValve9" 8 "AuxValve8" 7 "AuxValve7" 6 "AuxValve6" 5 "AuxValve5" 4 "AuxValve4" 3 "AuxValve3" 2 "AuxValve2" 1 "AuxValve1" ;
VAL_ 2619670270 RequestType_4 7 "DontCare" 6 "Error" 1 "AssignToRequestingClient" 0 "ReleaseAssignmentOfRequestingClient" ;
VAL_ 2619670270 RequestType_3 7 "DontCare" 6 "Error" 1 "AssignToRequestingClient" 0 "ReleaseAssignmentOfRequestingClient" ;
VAL_ 2619670270 RequestType_2 7 "DontCare" 6 "Error" 1 "AssignToRequestingClient" 0 "ReleaseAssignmentOfRequestingClient" ;
VAL_ 2619670270 RequestType_1 7 "DontCare" 6 "Error" 1 "AssignToRequestingClient" 0 "ReleaseAssignmentOfRequestingClient" ;
VAL_ 2619670270 TIMMessageType 1 "TIMFunctionStatus" 0 "TIMFunctionRequest" ;
VAL_ 2619670270 GroupFunctionValue 32 "TIM_AuxValve32Request" 249 "ClientStatus" 248 "ServerVersionRequest" 247 "ClientVersionResponse" 246 "ConnectionVersionRequest" 245 "FunctionsAssignmentRequest" 244 "FunctionsSupportRequest" 243 "FunctionsAssignmentStatusRequest" 70 "ExternalGuidanceRequest" 68 "VehicleSpeedRequest" 67 "RearHitchRequest" 66 "FrontHitchRequest" 65 "RearPTORequest" 64 "FrontPTORequest" 31 "TIM_AuxValve31Request" 30 "TIM_AuxValve30Request" 29 "TIM_AuxValve29Request" 28 "TIM_AuxValve28Request" 27 "TIM_AuxValve27Request" 26 "TIM_AuxValve26Request" 25 "TIM_AuxValve25Request" 24 "TIM_AuxValve24Request" 23 "TIM_AuxValve23Request" 22 "TIM_AuxValve22Request" 21 "TIM_AuxValve21Request" 20 "TIM_AuxValve20Request" 19 "TIM_AuxValve19Request" 18 "TIM_AuxValve18Request" 17 "TIM_AuxValve17Request" 16 "TIM_AuxValve16Request" 15 "TIM_AuxValve15Request" 14 "TIM_AuxValve14Request" 13 "TIM_AuxValve13Request" 12 "TIM_AuxValve12Request" 11 "TIM_AuxValve11Request" 10 "TIM_AuxValve10Request" 9 "TIM_AuxValve9Request" 8 "TIM_AuxValve8Request" 7 "TIM_AuxValve7Request" 6 "TIM_AuxValve6Request" 5 "TIM_AuxValve5Request" 4 "TIM_AuxValve4Request" 3 "TIM_AuxValve3Request" 2 "TIM_AuxValve2Request" 1 "TIM_AuxValve1Request" ;
VAL_ 2619604734 Curvature 32128 "Straight" ;
VAL_ 2619604734 GuidanceExitReasonCode 21 "HydraulicOilLevelTooLow" 20 "HydraulicOilTemperatureTooLow" 19 "VehicleTransmissionGearDoesntAllowRemoteCommands" 18 "VehicleSpeedTooLow" 17 "VehicleSpeedTooHigh" 16 "AlternateGuidanceSystemActive" 31 "NotAvailable" 30 "Error" 15 "ControlUnitInDiagnosticMode" 9 "FunctionFault" 8 "OperatorControlFault" 5 "RemoteCommandTimeout" 4 "OperatorControlNotInValidPosition" 3 "OperatorOverrideOfFunction" 2 "ImplementReleasedControlOfFunction" 7 "FunctionNotCalibrated" 6 "RemoteCommandOutOfRangeOrInvalid" 1 "RequiredLevelOfOperatorPresence_AwarenessNotDetected" 0 "NoReason_AllClear" ;
VAL_ 2619604734 SpeedExitReasonCode 31 "NotAvailable" 30 "Error" 15 "VehicleTransmissionGearDoesntAllowRemoteCommands " 9 "FunctionFault" 8 "OperatorControlFault" 5 "RemoteCommandTimeout" 4 "OperatorControlNotInValidPosition" 3 "OperatorOverrideOfFunction" 2 "ImplementReleasedControlOfFunction" 7 "FunctionNotCalibrated" 6 "RemoteCommandOutOfRangeOrInvalid" 1 "RequiredLevelOfOperatorPresence_AwarenessNotDetected" 0 "NoReason_AllClear" ;
VAL_ 2619604734 HitchPosition 64259 "Raising" 64258 "Lowering" 64257 "Stop" 10000 "FullRaise" 0 "FullLower" 64256 "Float" ;
VAL_ 2619604734 HitchExitReasonCode 16 "HitchLockedOut" 31 "NotAvailable" 30 "Error" 15 "HydraulicOilLevelLow" 9 "FunctionFault" 8 "OperatorControlFault" 5 "RemoteCommandTimeout" 4 "OperatorControlNotInValidPosition" 3 "OperatorOverrideOfFunction" 2 "ImplementReleasedControlOfFunction" 7 "FunctionNotCalibrated" 6 "RemoteCommandOutOfRangeOrInvalid" 1 "RequiredLevelOfOperatorPresence_AwarenessNotDetected" 0 "NoReason_AllClear" ;
VAL_ 2619604734 PTOExitReasonCode 31 "NotAvailable" 30 "Error" 15 "InvalidPtoGear" 9 "FunctionFault" 8 "OperatorControlFault" 5 "RemoteCommandTimeout" 4 "OperatorControlNotInValidPosition" 3 "OperatorOverrideOfFunction" 2 "ImplementReleasedControlOfFunction" 7 "FunctionNotCalibrated" 6 "RemoteCommandOutOfRange_Invalid" 1 "RequiredLevelOfOperatorPresence_AwarenessNotDetected" 0 "NoReason_AllClear" ;
VAL_ 2619604734 TIMAuxValveFlow 64257 "Float" 64256 "ValveFullyOpened_Retract" 32128 "NoFlow_Block" 0 "ValveFullyOpened_Extend" ;
VAL_ 2619604734 FlowType 3 "NotAvailable" 2 "Error" 1 "Measured" 0 "Estimated" ;
VAL_ 2619604734 ReflectedRequestCounter 15 "NotAvailable_DontCare " 14 "Reserved" ;
VAL_ 2619604734 AuxValveExitReasonCode 31 "NotAvailable" 30 "Error" 16 "ValveLockedOut_TransportLock" 15 "HydraulicOilLevelLow" 9 "FunctionFault" 8 "OperatorControlFault" 5 "RemoteCommandTimeout" 4 "OperatorControlNotInValidPosition" 3 "OperatorOverrideOfFunction" 2 "ImplementReleasedControlOfFunction" 7 "FunctionNotCalibrated" 6 "RemoteCommandOutOfRange_Invalid" 1 "RequiredLevelOfOperatorPresence_AwarenessNotDetected" 0 "NoReason_AllClear" ;
VAL_ 2619604734 AutomationStatus 13 "AutomationFault" 7 "ActiveLimitedLow" 6 "ActiveLimitedHigh" 5 "ActiveNotLimited" 0 "AutomationUnavailable" 1 "AutomationNotReady" 2 "AutomationReadyToEnable" 3 "AutomationEnabled" 4 "AutomationPending" 14 "NonRecoverableFault" 15 "NotAvailable" ;
VAL_ 2619604734 TIMSystemOperationState 15 "NotAvailable" 14 "Error" 3 "RequirementsStationaryFulfilled" 2 "RequirementsStandstillFulfilled" 1 "RequirementsNormalFulfilled" 0 "RequirementsNotFulfilled" ;
VAL_ 2619604734 TIMServerState 13 "AutomationFault" 5 "AutomationActive" 3 "AutomationEnabled" 15 "NotAvailable" 14 "Error" 1 "AutomationNotReady" 0 "AutomationUnavailable" ;
VAL_ 2619604734 TIMSystemState 15 "NotAvailable" 14 "Error" 5 "AutomationActive" 1 "NoAutomationActive" ;
VAL_ 2619604734 TIMServerMasterIndication 15 "NotAvailable" 14 "Error" 1 "IsMasterAndAutomationAllowed" 0 "IsMasterButAutomationNotAllowed" ;
VAL_ 2619604734 ServerHeartbeatCounter 255 "GracefulShutdown" 254 "ErrorConditionOnSender" 251 "ResetOfHeartbeatCounter" ;
VAL_ 2619604734 AssignmentResult_4 7 "NotAvailable" 6 "Error" 5 "AssignmentNotSuccessful" 1 "IsAssigned" 0 "IsNotAssigned" ;
VAL_ 2619604734 AssignmentResult_3 7 "NotAvailable" 6 "Error" 5 "AssignmentNotSuccessful" 1 "IsAssigned" 0 "IsNotAssigned" ;
VAL_ 2619604734 AssignmentResult_2 7 "NotAvailable" 6 "Error" 5 "AssignmentNotSuccessful" 1 "IsAssigned" 0 "IsNotAssigned" ;
VAL_ 2619604734 AssignmentErrorReason_4 31 "NotAvailable" 30 "AnyOtherError" 8 "ClientNotAuthenticated" 7 "NoMatchingFacility" 6 "ServerBusyWithAssignmentRequest" 5 "ClientNotCertifiedForFunction" 4 "ErrorInRequestMessage" 3 "UnknownRequestType" 2 "IsAssignedToAnotherClient" 1 "FunctionNotSupportedByServer" 0 "AllClearNoReason" ;
VAL_ 2619604734 AssignmentErrorReason_3 31 "NotAvailable" 30 "AnyOtherError" 8 "ClientNotAuthenticated" 7 "NoMatchingFacility" 6 "ServerBusyWithAssignmentRequest" 5 "ClientNotCertifiedForFunction" 4 "ErrorInRequestMessage" 3 "UnknownRequestType" 2 "IsAssignedToAnotherClient" 1 "FunctionNotSupportedByServer" 0 "AllClearNoReason" ;
VAL_ 2619604734 AssignmentErrorReason_2 31 "NotAvailable" 30 "AnyOtherError" 8 "ClientNotAuthenticated" 7 "NoMatchingFacility" 6 "ServerBusyWithAssignmentRequest" 5 "ClientNotCertifiedForFunction" 4 "ErrorInRequestMessage" 3 "UnknownRequestType" 2 "IsAssignedToAnotherClient" 1 "FunctionNotSupportedByServer" 0 "AllClearNoReason" ;
VAL_ 2619604734 AssignmentErrorReason_1 31 "NotAvailable" 30 "AnyOtherError" 8 "ClientNotAuthenticated" 7 "NoMatchingFacility" 6 "ServerBusyWithAssignmentRequest" 5 "ClientNotCertifiedForFunction" 4 "ErrorInRequestMessage" 3 "UnknownRequestType" 2 "IsAssignedToAnotherClient" 1 "FunctionNotSupportedByServer" 0 "AllClearNoReason" ;
VAL_ 2619604734 AssignmentResult_1 7 "NotAvailable" 6 "Error" 5 "AssignmentNotSuccessful" 1 "IsAssigned" 0 "IsNotAssigned" ;
VAL_ 2619604734 TIMFunctionId_4 32 "AuxValve32" 70 "ExternalGuidance" 68 "VehicleSpeed" 67 "RearHitch" 66 "FrontHitch" 65 "RearPTO" 64 "FrontPTO" 31 "AuxValve31" 30 "AuxValve30" 29 "AuxValve29" 28 "AuxValve28" 27 "AuxValve27" 26 "AuxValve26" 25 "AuxValve25" 24 "AuxValve24" 23 "AuxValve23" 22 "AuxValve22" 21 "AuxValve21" 20 "AuxValve20" 19 "AuxValve19" 18 "AuxValve18" 17 "AuxValve17" 16 "AuxValve16" 15 "AuxValve15" 14 "AuxValve14" 13 "AuxValve13" 12 "AuxValve12" 11 "AuxValve11" 10 "AuxValve10" 9 "AuxValve9" 8 "AuxValve8" 7 "AuxValve7" 6 "AuxValve6" 5 "AuxValve5" 4 "AuxValve4" 3 "AuxValve3" 2 "AuxValve2" 1 "AuxValve1" ;
VAL_ 2619604734 TIMFunctionId_3 32 "AuxValve32" 70 "ExternalGuidance" 68 "VehicleSpeed" 67 "RearHitch" 66 "FrontHitch" 65 "RearPTO" 64 "FrontPTO" 31 "AuxValve31" 30 "AuxValve30" 29 "AuxValve29" 28 "AuxValve28" 27 "AuxValve27" 26 "AuxValve26" 25 "AuxValve25" 24 "AuxValve24" 23 "AuxValve23" 22 "AuxValve22" 21 "AuxValve21" 20 "AuxValve20" 19 "AuxValve19" 18 "AuxValve18" 17 "AuxValve17" 16 "AuxValve16" 15 "AuxValve15" 14 "AuxValve14" 13 "AuxValve13" 12 "AuxValve12" 11 "AuxValve11" 10 "AuxValve10" 9 "AuxValve9" 8 "AuxValve8" 7 "AuxValve7" 6 "AuxValve6" 5 "AuxValve5" 4 "AuxValve4" 3 "AuxValve3" 2 "AuxValve2" 1 "AuxValve1" ;
VAL_ 2619604734 TIMFunctionId_2 32 "AuxValve32" 70 "ExternalGuidance" 68 "VehicleSpeed" 67 "RearHitch" 66 "FrontHitch" 65 "RearPTO" 64 "FrontPTO" 31 "AuxValve31" 30 "AuxValve30" 29 "AuxValve29" 28 "AuxValve28" 27 "AuxValve27" 26 "AuxValve26" 25 "AuxValve25" 24 "AuxValve24" 23 "AuxValve23" 22 "AuxValve22" 21 "AuxValve21" 20 "AuxValve20" 19 "AuxValve19" 18 "AuxValve18" 17 "AuxValve17" 16 "AuxValve16" 15 "AuxValve15" 14 "AuxValve14" 13 "AuxValve13" 12 "AuxValve12" 11 "AuxValve11" 10 "AuxValve10" 9 "AuxValve9" 8 "AuxValve8" 7 "AuxValve7" 6 "AuxValve6" 5 "AuxValve5" 4 "AuxValve4" 3 "AuxValve3" 2 "AuxValve2" 1 "AuxValve1" ;
VAL_ 2619604734 TIMFunctionId_1 32 "AuxValve32" 70 "ExternalGuidance" 68 "VehicleSpeed" 67 "RearHitch" 66 "FrontHitch" 65 "RearPTO" 64 "FrontPTO" 31 "AuxValve31" 30 "AuxValve30" 29 "AuxValve29" 28 "AuxValve28" 27 "AuxValve27" 26 "AuxValve26" 25 "AuxValve25" 24 "AuxValve24" 23 "AuxValve23" 22 "AuxValve22" 21 "AuxValve21" 20 "AuxValve20" 19 "AuxValve19" 18 "AuxValve18" 17 "AuxValve17" 16 "AuxValve16" 15 "AuxValve15" 14 "AuxValve14" 13 "AuxValve13" 12 "AuxValve12" 11 "AuxValve11" 10 "AuxValve10" 9 "AuxValve9" 8 "AuxValve8" 7 "AuxValve7" 6 "AuxValve6" 5 "AuxValve5" 4 "AuxValve4" 3 "AuxValve3" 2 "AuxValve2" 1 "AuxValve1" ;
VAL_ 2619604734 TIMConnectionVersion 255 "IncompatibleTIMServerAndClientVersions" ;
VAL_ 2619604734 ErrorCode 1 "IncompatibleTIMServerAndClientVersions" 0 "NoError" ;
VAL_ 2619604734 TIMMessageType 1 "TIMFunctionStatus" 0 "TIMFunctionRequest" ;
VAL_ 2619604734 GroupFunctionValue 32 "TIM_AuxValve32Status" 243 "FunctionsAssignmentStatusResponse" 250 "ServerStatus" 248 "ServerVersionResponse" 247 "ClientVersionRequest" 246 "ConnectionVersionResponse" 245 "FunctionsAssignmentResponse" 244 "FunctionsSupportResponse" 70 "ExternalGuidanceStatus" 68 "VehicleSpeedStatus" 67 "RearHitchStatus" 66 "FrontHitchStatus" 65 "RearPTOStatus" 64 "FrontPTOStatus" 31 "TIM_AuxValve31Status" 30 "TIM_AuxValve30Status" 29 "TIM_AuxValve29Status" 28 "TIM_AuxValve28Status" 27 "TIM_AuxValve27Status" 26 "TIM_AuxValve26Status" 25 "TIM_AuxValve25Status" 24 "TIM_AuxValve24Status" 23 "TIM_AuxValve23Status" 22 "TIM_AuxValve22Status" 21 "TIM_AuxValve21Status" 20 "TIM_AuxValve20Status" 19 "TIM_AuxValve19Status" 18 "TIM_AuxValve18Status" 17 "TIM_AuxValve17Status" 16 "TIM_AuxValve16Status" 15 "TIM_AuxValve15Status" 14 "TIM_AuxValve14Status" 13 "TIM_AuxValve13Status" 12 "TIM_AuxValve12Status" 11 "TIM_AuxValve11Status" 10 "TIM_AuxValve10Status" 9 "TIM_AuxValve9Status" 8 "TIM_AuxValve8Status" 7 "TIM_AuxValve7Status" 6 "TIM_AuxValve6Status" 5 "TIM_AuxValve5Status" 4 "TIM_AuxValve4Status" 3 "TIM_AuxValve3Status" 2 "TIM_AuxValve2Status" 1 "TIM_AuxValve1Status" ;
VAL_ 2360147710 GuidSysComExitReasonCode 0 "No reason/all clear " 1 "Operator presence not detected" 2 "Implement released control of function " 3 "Operator override of function" 4 "Operator control not in valid position" 5 "Remote command timeout" 6 "Remote command out of range/invalid" 7 "Function not calibrated" 8 "Operator control fault" 9 "Function fault" 20 "Hydraulic oil level too low " 21 "Hydraulic oil temperature too low" 22 "Vehicle transmission gear does not allow remote commands" 23 "Vehicle speed too low " 24 "Vehicle speed too high" 25 "Alternate guidance system active" 26 "Control unit in diagnostic mode" 62 "Error " 63 "Not available (parameter not supported)" ;
VAL_ 2360147710 GuidanceLimitStatus 0 "Not limited" 1 "Operator limited/controlled (request cannot be implemented) " 2 "Limited high (only lower command values result in a change) " 3 "Limited low (only higher command values result in a change)" 4 "Reserved" 5 "Reserved" 6 "Non-recoverable fault " 7 "Not available (parameter not supported) " ;
VAL_ 2360147710 RequestResetCommandStatus 3 "NotAvailable" 2 "Error" 1 "ResetRequired" 0 "ResetNotRequired" ;
VAL_ 2360147710 SteeringInputPositionStatus 3 "NotAvailable" 2 "Error" 1 "CorrectPosition" 0 "NotTheCorrectPosition" ;
VAL_ 2360147710 SteeringSystemReadiness 3 "NotAvailable" 2 "Error" 1 "SystemIsReady" 0 "SystemIsNotReady" ;
VAL_ 2360147710 MechanicalSystemLockout 3 "NotAvailable" 2 "Error" 1 "Active" 0 "NotActive" ;
VAL_ 2360213246 CurvatureCommandStatus 3 "NotAvailable" 2 "Error" 1 "IntendedToSteer" 0 "NotIntendedToSteer" ;
VAL_ 2563047166 FailSaveModeCmd 3 "DoNotCare" 1 "Float" 0 "Block" ;
VAL_ 2563047166 StateCmd 15 "Reserved" 3 "Float" 2 "Retract" 1 "Extend" 0 "Block" ;
VAL_ 2563112702 ValveLimitStatus 0 "Not limited" 1 "Operator Limited" 2 "Limited High" 3 "Limited Low" 4 "Reserved" 5 "Reserver" 6 "Non-recoverable Fault" 7 "Not available" ;
VAL_ 2563178238 ValveLimitStatus 0 "Not limited" 1 "Operator Limited" 2 "Limited High" 3 "Limited Low" 4 "Reserved" 5 "Reserver" 6 "Non-recoverable Fault" 7 "Not available" ;
VAL_ 2563178238 FailSafeMode 3 "NotAvailable" 2 "ErrorIndication" 1 "Float" 0 "Block" ;
VAL_ 2563178238 ValveState 15 "DoNotCare" 14 "ErrorIndication" 3 "Floating" 2 "Retract" 1 "Extend" 0 "Blocked" ;
VAL_ 2628452094 SA_ATTR_SupportsLongFilenames 0 "Does not support long file names" 1 "Supports long file names" ;
VAL_ 2628452094 SA_ATTR_VolumeSupportsHidden 0 "No support of hidden attribute" 1 "Supports hidden attribute" ;
VAL_ 2628452094 SA_ATTR_VolumeIsRemovable 0 "Is not removable" 1 "Is removable" ;
VAL_ 2628452094 SA_ATTR_VolumeIsCaseSensitive 0 "Is case-insensitive" 1 "Is case-sensitive" ;
VAL_ 2628452094 SA_ATTR_IsVolume 0 "Does not specify a volume " 1 "Specifies a volume" ;
VAL_ 2628452094 SA_ATTR_IsDirectory 0 "Does not specify a directory" 1 "Specifies a directory" ;
VAL_ 2628452094 RF_ReportHiddenFiles 0 "DoNotReportHiddenFiles" 1 "ReportHiddenFiles" 255 "NotAvailable" ;
VAL_ 2628452094 SF_PositionMode 0 "From the beginning of the file" 1 "From the current pointer pos" 2 "From the end of the file" ;
VAL_ 2628452094 OF_FlagExclusiveAccess 0 "Open file for shared read access" 1 "Open file with exclusive access" ;
VAL_ 2628452094 OF_FlagAppend 0 "Open file for random access" 1 "Open file for appending data" ;
VAL_ 2628452094 SA_ATTR_Hidden 0 "'Hidden' attribute is not set" 1 "'Hidden' attribute is set" ;
VAL_ 2628452094 OF_FlagCreateNew 0 "Open an existing file" 1 "Create new file if not existing" ;
VAL_ 2628452094 MF_MoveModeRecursive 0 "'recursive' mode is not set" 1 "'recursive' mode is set" ;
VAL_ 2628452094 DF_DeleteModeRecursive 0 "'recursive' mode is not set" 1 "'recursive' mode is set" ;
VAL_ 2628452094 MF_MoveModeForce 0 "'force' mode is not set" 1 "'force' mode is set" ;
VAL_ 2628452094 DF_DeleteModeForce 0 "'force' mode is not set" 1 "'force' mode is set" ;
VAL_ 2628452094 SA_ATTR_ReadOnly 0 "'Read-only' attribute is not set" 1 "'Read-only' attribute is set" ;
VAL_ 2628452094 OF_FlagReadWrite 0 "Open file for reading only" 1 "Open file for writing only" 2 "Open file for reading & writing" 3 "Open directory for reading" ;
VAL_ 2628452094 MF_MoveModeCopy 0 "'copy' mode is not set" 1 "'copy' mode is set" ;
VAL_ 2628452094 DF_DeleteMode 0 "'copy' mode is not set" 1 "'copy' mode is set" ;
VAL_ 2628452094 VS_RequestVolumeToPrepareForRemo 1 "RequestVolumeToPrepareForRemoval" ;
VAL_ 2628452094 VS_ReportVolumeUsedByClient 0 "ReportVolumeNotInUseByClient" 1 "ReportVolumeInUseByClient" ;
VAL_ 2628452094 CM_VersionNumber 0 "DIS" 1 "FDIS" 2 "FirstPublishedEditionOfIS" 3 "SecondPublishedEditionOfIS" 255 "CompliantToVersion2AndPrior" ;
VAL_ 2628452094 FSClientCommand 0 "ConnectionMaintenance" 16 "GetCurrentDirectoryRequest" 32 "OpenFileRequest" 33 "SeekFileRequest" 34 "ReadFileRequest" 35 "WriteFileRequest" 36 "CloseFileRequest" 48 "MoveFileRequest" 49 "DeleteFileRequest" 50 "GetFileAttributesRequest" 51 "SetFileAttributesRequest" 17 "ChangeCurrentDirectoryRequest" 52 "GetFileDateTimeRequest" 64 "VolumeInitializationRequest" 1 "GetFileServerProperties" 2 "VolumeStatusRequest" ;
VAL_ 2628517630 OF_ATTR_VolumeSupportsHidden 0 "No support of hidden attribute" 1 "Supports hidden attribute" ;
VAL_ 2628517630 OF_ATTR_VolumeIsCaseSensitive 0 "Is case-insensitive" 1 "Is case-sensitive" ;
VAL_ 2628517630 OF_ATTR_VolumeIsRemovable 0 "Is removable" 1 "Is not removable" ;
VAL_ 2628517630 OF_ATTR_SupportsLongFilenames 0 "Does not support long filename" 1 "Supports long filenames" ;
VAL_ 2628517630 OF_ATTR_IsDirectory 0 "Does not specifiy a directory" 1 "Specifes a directory" ;
VAL_ 2628517630 OF_ATTR_IsVolume 0 "Does not specifiy a volume" 1 "Specifies a volume" ;
VAL_ 2628517630 OF_ATTR_Hidden 0 "'Hidden' attribute is not set" 1 "'Hidden' attribute is set" ;
VAL_ 2628517630 OF_ATTR_ReadOnly 0 "'Read-only' attribute is not set" 1 "'Read-only' attribute is set" ;
VAL_ 2628517630 GA_ATTR_VolumeIsCaseSensitive 0 "Is case-insensitive" 1 "Is case-sensitive" ;
VAL_ 2628517630 VI_ATTR_VolumeRemovable 0 "Is removable" 1 "Is not removable" ;
VAL_ 2628517630 GA_ATTR_VolumeIsRemovable 0 "Is removable" 1 "Is not removable" ;
VAL_ 2628517630 VI_ATTR_SupportsLongFilenames 0 "Does not support long filename" 1 "Supports long filenames" ;
VAL_ 2628517630 GA_ATTR_SupportsLongFilenames 0 "Does not support long filename" 1 "Supports long filenames" ;
VAL_ 2628517630 GA_ATTR_IsDirectory 0 "Does not specifiy a directory" 1 "Specifes a directory" ;
VAL_ 2628517630 VI_ATTR_IsDirectory 0 "Does not specify a directory" 1 "Secifies a directory" ;
VAL_ 2628517630 VI_ATTR_IsVolume 0 "Does not specifiy a volume" 1 "Specifies a volume" ;
VAL_ 2628517630 GA_ATTR_IsVolume 0 "Does not specifiy a volume" 1 "Specifies a volume" ;
VAL_ 2628517630 VI_ATTR_VolumeSupportsHidden 0 "No support of hidden attribute" 1 "Supports hidden attribute" ;
VAL_ 2628517630 GA_ATTR_VolumeSupportsHidden 0 "No support of hidden attribute" 1 "Supports hidden attribute" ;
VAL_ 2628517630 VI_ATTR_Hidden 0 "'Hidden' attribute is not set" 1 "'Hidden' attribute is set" ;
VAL_ 2628517630 GA_ATTR_Hidden 0 "'Hidden' attribute is not set" 1 "'Hidden' attribute is set" ;
VAL_ 2628517630 VI_ATTR_ReadOnly 0 "'Read-only' attribute is not set" 1 "'Read-only' attribute is set" ;
VAL_ 2628517630 GA_ATTR_ReadOnly 0 "'Read-only' attribute is not set" 1 "'Read-only' attribute is set" ;
VAL_ 2628517630 GSP_SupportMultipleVolumes 0 "Beschreibung für den Wert '0'" ;
VAL_ 2628517630 FDT_ErrorCode 0 "Success" 1 "Access Denied" 3 "Too many files open" 4 "File, path or volume not found" 6 "Invalid given source name" 10 "Media is not present" 44 "Any other error" 43 "Out ot memory" 11 "Failure during a read operation" 13 " Volume possibly not initialized" ;
VAL_ 2628517630 RF_ErrorCode 45 "File pointer at end of file" 44 "Any other error" 42 "Invalid request length" 5 "Invalid handle" 0 "Success" 11 "Failure during read operation" 43 "Out of memory" 1 "Access denied" ;
VAL_ 2628517630 SF_ErrorCode 0 "Success" 5 "Invalid handle" 42 "Invalid request length" 44 "Any other error" 45 "File pointer at end of file" 11 "Failure during read operation" 43 "Out of memory" ;
VAL_ 2628517630 OF_ErrorCode 0 "Success" 1 "Access Denied" 2 "Invalid Access" 3 "Too many files open" 4 "File, path or volume not found" 6 "Invalid given source name" 8 "Volume out of free space" 10 "Media is not present" 44 "Any other error" 43 "Out of memory" 13 "Volume possibly not initialized" ;
VAL_ 2628517630 WF_ErrorCode 0 "Success" 1 "Access Denied" 5 "Invalid handle" 8 "Volume out of free space" 9 "Failure during a write operation" 42 "Invalid request length" 44 "Any other error" 43 "Out of memory" ;
VAL_ 2628517630 CF_ErrorCode 0 "Success" 1 "Access Denied" 5 "Invalid handle" 8 "Volume out of free space" 9 "Failure during a write operation" 44 "Any other error" 43 "Out ot memory" ;
VAL_ 2628517630 MF_ErrorCode 0 "Success" 1 "Access Denied" 3 "Too many files open" 6 "Invalid given source name" 7 "Invalid given destination name" 8 "Volume out of free space" 9 "Verify failure during a write op" 10 "Media is not present" 44 "Any other error" 43 "Out of memory" 4 "File, path or volume not found" 13 "Volume possibly not initialized" ;
VAL_ 2628517630 GA_ErrorCode 0 "Success" 1 "Access Denied" 3 "Too many files open" 4 "File, path or volume not found" 6 "Invalid given source name" 10 "Media is not present" 44 "Any other error" 43 "Out of memory" 11 "Failure during read operation" 13 "Volume possibly not initialized" ;
VAL_ 2628517630 SA_ErrorCode 0 "Success" 1 "Access Denied" 3 "Too many files open" 4 "File, path or volume not found" 6 "Invalid given source name" 8 "Volume out of free space" 9 "Failure during write operation" 10 "Media is not present" 44 "Any other error" 43 "Out of memory" 11 "Failure during read operation" 13 "Volume possibly not initialized" ;
VAL_ 2628517630 GCD_ErrorCode 0 "Success" 10 "Media is not present" 44 "Any other error" 43 "Out of Memory" 13 "Volume possibly not initialized" ;
VAL_ 2628517630 CCD_ErrorCode 0 "Success" 10 "Media is not present" 44 "Any other error" 43 "Out of memory" 13 "Volume possibly not initialized" 1 "Access denied" 2 "Invalid Access" 4 "File, path or volume not found" 7 "Invalid destination name given" ;
VAL_ 2628517630 DF_ErrorCode 0 "Success" 1 "Access Denied" 4 "File, path or volume not found" 6 "Invalid given source name" 10 "Media is not present" 44 "Any other error" 43 "Out of memory" 9 "Failure during write operation" 11 "Failure during read operation" 13 "Volume possibly not initialized" ;
VAL_ 2628517630 VI_ErrorCode 0 "Success" 1 "Access Denied" 4 "File, path or volume not found" 6 "Invalid given source name" 8 "Volume out of free space" 9 "Failure during write operation" 42 "Invalid request length" 44 "Any other error" 43 "Out of memory" 10 "Media is not present" 11 "Failure during read operation" 13 "Volume possibly not initialized" ;
VAL_ 2628517630 GSP_VersionNumber 0 "DIS" 1 "FDIS" 2 "FirstPublishedEditionOfIS" 3 "SecondPublishedEditionOfIS" 255 "CompliantToVersion2AndPrior" ;
VAL_ 2628517630 VS_VolumeStatus 0 "Present" 1 "InUse" 2 "PreparingForRemoval" 3 "Removed" ;
VAL_ 2628517630 FSServerCommand 0 "FileServerStatus" 16 "GetCurrentDirectoryResponse" 32 "OpenFileResponse" 33 "SeekFileResponse" 34 "ReadFileResponse" 35 "WriteFileResponse" 36 "CloseFileResponse" 48 "MoveFileResponse" 49 "DeleteFileResponse" 50 "GetFileAttributesResponse" 51 "SetFileAttributeResponse" 17 "ChangeCurrentDirectoryResponse" 52 "GetFileDateTimeResponse" 64 "VolumeInitializationResponse" 1 "GetFileServerPropertiesResponse" 2 "VolumeStatusResponse" ;
VAL_ 2364540158 EngStarterMode 15 "not available" 14 "error" 12 "starter inhibited  reason unknown" 9 "starter inhibited due to intake air shutoff valve being active" 8 "starter inhibited due to starter overtemp" 7 "starter inhibited due to active immobilizer" 6 "starter inhibited due to driveline engaged or other transmission inhibit" 5 "starter inhibited due to engine not ready for start preheating" 4 "starter inhibited due to engine already running" 3 "start finished starter not active after having been actively engaged after 50ms mode goes to 0000" 2 "starter active gear engaged" 1 "starter active gear not engaged" 0 "start not requested" 10 "starter inhibited due to active SCR inducement" 11 "Reserved" 13 "error legacy implementation only use 1110" ;
VAL_ 2364540158 ActlEngPrcntTorqueHighResolution 0 "0000" 1 "0125" 7 "0875" 8 "1111  not available" ;
VAL_ 2563309310 PGNumber 255 "NotAvailable" ;
VAL_ 2563309310 ControlByte 255 "EAbort" 20 "ERTS" 21 "ECTS" 22 "EDPO" 23 "EEoMACK" 24 "EAbort" ;
VAL_ 2563309310 ConnectionAbortReason 15 "ECTS requested packets exceeds message size" 14 "Unexpected ECTS PGN (PGN in ECTS is bad)" 13 "Deprecated use 254 instead" 12 "Bad EDPO offset" 11 "EDPO number of packets is greater than CTS" 10 "Unexpected EDPO PGN (PGN in EDPO is bad)" 9 "Unexpected EDPO packet" 8 "Duplicate sequence number" 1 "Already in one or more connection-managed sessions" 2 "System resources were needed for another task" 3 "Timeout occurred" 4 "CTS messages received when data transfer is in progress" 5 "Maximum retransmit request limit reached" 6 "Unexpected data transfer packet" 7 "Bad sequence number" ;
VAL_ 2583168510 RefrenceStationType1 14 "Error" 1 "GLONASS" 0 "GPS" ;
VAL_ 2583168510 GNSSIntegrity 3 "Unsafe" 2 "Caution" 1 "Safe" 0 "No integrity checking" ;
VAL_ 2583168510 GNSSMethod 14 "Error" 8 "Simulate mode" 7 "Manual input" 6 "Estimated (DR) mode" 5 "RTK float" 4 "RTK fixed integer" 3 "Precise GNSS" 2 "DGNSS fix" 1 "GNSS fix" 0 "no GPS" ;
VAL_ 2583168510 TypeOfSystem 4 "GPS and SBAS and GLONASS" 3 "GPS and SBAS(WAAS)" 2 "GPS and GLONASS" 1 "GLONASS" 0 "GPS" ;
VAL_ 2566849534 ManufacturerSpecific8 255 "NotAvailable" ;
VAL_ 2566849534 ManufacturerSpecific7 255 "NotAvailable" ;
VAL_ 2566849534 ManufacturerSpecific6 255 "NotAvailable" ;
VAL_ 2566849534 ManufacturerSpecific5 255 "NotAvailable" ;
VAL_ 2566849534 ManufacturerSpecific4 255 "NotAvailable" ;
VAL_ 2566849534 ManufacturerSpecific3 255 "NotAvailable" ;
VAL_ 2566849534 ManufacturerSpecific2 255 "NotAvailable" ;
VAL_ 2566849534 ManufacturerSpecific1 255 "NotAvailable" ;
VAL_ 2566849278 ManufacturerSpecific8 255 "NotAvailable" ;
VAL_ 2566849278 ManufacturerSpecific7 255 "NotAvailable" ;
VAL_ 2566849278 ManufacturerSpecific6 255 "NotAvailable" ;
VAL_ 2566849278 ManufacturerSpecific5 255 "NotAvailable" ;
VAL_ 2566849278 ManufacturerSpecific4 255 "NotAvailable" ;
VAL_ 2566849278 ManufacturerSpecific3 255 "NotAvailable" ;
VAL_ 2566849278 ManufacturerSpecific2 255 "NotAvailable" ;
VAL_ 2566849278 ManufacturerSpecific1 255 "NotAvailable" ;
VAL_ 2566849022 ManufacturerSpecific8 255 "NotAvailable" ;
VAL_ 2566849022 ManufacturerSpecific7 255 "NotAvailable" ;
VAL_ 2566849022 ManufacturerSpecific6 255 "NotAvailable" ;
VAL_ 2566849022 ManufacturerSpecific5 255 "NotAvailable" ;
VAL_ 2566849022 ManufacturerSpecific4 255 "NotAvailable" ;
VAL_ 2566849022 ManufacturerSpecific3 255 "NotAvailable" ;
VAL_ 2566849022 ManufacturerSpecific2 255 "NotAvailable" ;
VAL_ 2566849022 ManufacturerSpecific1 255 "NotAvailable" ;
VAL_ 2566848766 ManufacturerSpecific8 255 "NotAvailable" ;
VAL_ 2566848766 ManufacturerSpecific7 255 "NotAvailable" ;
VAL_ 2566848766 ManufacturerSpecific6 255 "NotAvailable" ;
VAL_ 2566848766 ManufacturerSpecific5 255 "NotAvailable" ;
VAL_ 2566848766 ManufacturerSpecific4 255 "NotAvailable" ;
VAL_ 2566848766 ManufacturerSpecific3 255 "NotAvailable" ;
VAL_ 2566848766 ManufacturerSpecific2 255 "NotAvailable" ;
VAL_ 2566848766 ManufacturerSpecific1 255 "NotAvailable" ;
VAL_ 2365475326 GroundBasedMachineDirection 3 "NotAvailable" 2 "ErrorIndication" 1 "Forward" 0 "Reverse" ;
VAL_ 2365475070 OperatorDirectionReversed 0 "Not reversed" 1 "Reversed" 2 "Error" 3 "Not available" ;
VAL_ 2365475070 StartStopState 3 "Don't Care" 2 "Reserved" 1 "Start or enable implement work" 0 "Stop or disable implement work" ;
VAL_ 2365475070 KeySwitchState 3 "NotAvailable" 2 "ErrorIndication" 1 "KeySwitchNotOff" 0 "KeySwitchOff" ;
VAL_ 2365475070 WheelBasedMachineDirection 3 "NotAvailable" 2 "ErrorIndicator" 1 "Forward" 0 "Reverse" ;
VAL_ 2566801406 ImplementInWorkState 3 "Not available" 2 "Error indication" 1 "Implement is in work state" 0 "Implement is not in work state" ;
VAL_ 2566801406 ImplementTransportState 3 "Not available" 2 "Error indication" 1 "Implement may be transported" 0 "Implement may not be transported" ;
VAL_ 2566801406 ImplementParkState 3 "Not available" 2 "Error indication" 1 "Implement may be disconnected" 0 "Implement may not be disconnected" ;
VAL_ 2566801406 ImplementReadyToWorkState 3 "Not available" 2 "Error indication" 1 "Implement is ready for field work" 0 "Implement is not ready for field work" ;
VAL_ 2566801406 MaintainECUPower 3 "DoNotCare" 1 "RequireForTwoMoreSecOfECU_PWR" 0 "NoFurtherRequireForECU_PWR" ;
VAL_ 2566801406 MaintainActuatorPower 3 "DoNotCare" 1 "RequireForTwoMoreSecOfPWR" 0 "NoFurtherRequirementForPWR" ;
VAL_ 2365474558 FrontHitchExitReasonCode 0 "No reason/all clear " 1 "Operator presence not detected" 2 "Implement released control of function" 3 "Operator override of function " 4 "Operator control not in valid position " 5 "Remote command timeout " 6 "Remote command out of range/invalid " 7 "Function not calibrated " 8 "Operator control fault " 9 "Function fault " 20 "Hydraulic oil level too low " 21 "Hitch locked out " 62 "Error" 63 "Not available (parameter not supported) " ;
VAL_ 2365474558 FrontHitchInWorkIndication 3 "NotAvailable" 2 "ErrorIndication" 1 "HitchPositionIsInWorl" 0 "HitchPositionIsOutOfWork" ;
VAL_ 2365474558 FrontHitchPositionLimitStatus 0 "Not limited" 1 "Operator Limited" 2 "Limited High" 3 "Limited Low" 4 "Reserved" 5 "Reserver" 6 "Non-recoverable Fault" 7 "Not available" ;
VAL_ 2365474302 RearHitchExitReasonCode 0 "No reason/all clear " 1 "Operator presence not detected" 2 "Implement released control of function" 3 "Operator override of function " 4 "Operator control not in valid position " 5 "Remote command timeout " 6 "Remote command out of range/invalid " 7 "Function not calibrated " 8 "Operator control fault " 9 "Function fault " 20 "Hydraulic oil level too low " 21 "Hitch locked out " 62 "Error" 63 "Not available (parameter not supported) " ;
VAL_ 2365474302 RearHitchInWorkIndication 3 "NotAvailable" 2 "ErrorIndication" 1 "HitchPositionIsInWork" 0 "HitchPositionIsOutOfWork" ;
VAL_ 2365474302 RearHitchPositionLimitStatus 0 "Not limited" 1 "Operator Limited" 2 "Limited High" 3 "Limited Low" 4 "Reserved" 5 "Reserver" 6 "Non-recoverable Fault" 7 "Not available" ;
VAL_ 2365474046 FrontPTOExitReasonCode 0 "No reason/all clear" 1 "Operator presence not detected" 2 "Implement released control of function" 3 "Operator override of function " 4 "Operator control not in valid position " 5 "Remote command timeout " 6 "Remote command out of range/invalid " 7 "Function not calibrated " 8 "Operator control fault " 9 "Function fault " 20 "Invalid PTO gear" 62 "Error " 63 "Not available (parameter not supported)" ;
VAL_ 2365474046 FrontPTOModeRqStatus 0 "External Request accepted" 1 "Control Override" 2 "Error" 3 "Not available" ;
VAL_ 2365474046 FrontPTOEconomyModeRqStatus 0 "External Request accepted" 1 "Control Override" 2 "Error" 3 "Not available" ;
VAL_ 2365474046 FrontPTOShaftSpeedLimitStatus 0 "Not limited" 1 "Operator Limited" 2 "Limited High" 3 "Limited Low" 4 "Reserved" 5 "Reserver" 6 "Non-recoverable Fault" 7 "Not available" ;
VAL_ 2365474046 FrontPTOEngagement 3 "NotAvailable" 2 "ErrorIndication" 1 "PTOEngaged" 0 "PTODisengaged" ;
VAL_ 2365474046 FrontPTOMode 3 "NotAvailable" 2 "ErrorIndication" 1 "PTOModeIs1000" 0 "PTOModeIs540" ;
VAL_ 2365474046 FrontPTOEconomyMode 3 "NotAvailable" 2 "ErrorIndication" 1 "PTOEconomyModeIsEngaged" 0 "PTOEconomyModeIsDisengaged" ;
VAL_ 2365474046 FrontPTOEngagementRqStatus 0 "External Request accepted" 1 "Control Override" 2 "Error" 3 "Not available" ;
VAL_ 2365473790 RearPTOExitReasonCode 0 "No reason/all clear" 1 "Operator presence not detected" 2 "Implement released control of function" 3 "Operator override of function " 4 "Operator control not in valid position " 5 "Remote command timeout " 6 "Remote command out of range/invalid " 7 "Function not calibrated " 8 "Operator control fault " 9 "Function fault " 20 "Invalid PTO gear" 62 "Error " 63 "Not available (parameter not supported)" ;
VAL_ 2365473790 RearPTOModeRqStatus 0 "External Request accepted" 1 "Control Override" 2 "Error" 3 "Not available" ;
VAL_ 2365473790 RearPTOEconomyModeRqStatus 0 "External Request accepted" 1 "Control Override" 2 "Error" 3 "Not available" ;
VAL_ 2365473790 RearPTOShaftSpeedLimitStatus 0 "Not limited" 1 "Operator Limited" 2 "Limited High" 3 "Limited Low" 4 "Reserved" 5 "Reserver" 6 "Non-recoverable Fault" 7 "Not available" ;
VAL_ 2365473790 RearPTOEngagement 3 "NotAvailable" 2 "ErrorIndication" 1 "PTOEngaged" 0 "PTODisengaged" ;
VAL_ 2365473790 RearPTOMode 3 "NotAvailable" 2 "ErrorIndication" 1 "PTOModeIs1000" 0 "PTOModeIs540" ;
VAL_ 2365473790 RearPTOEconomyMode 3 "NotAvailabel" 2 "ErrorIndication" 1 "PTOEconomyModeIsEngaged" 0 "PTOEconomyModeIsDisengaged" ;
VAL_ 2365473790 RearPTOEngagementRqStatus 0 "External Request accepted" 1 "Control Override" 2 "Error" 3 "Not available" ;
VAL_ 2365473534 FrontPTOModeCmd 3 "DoNotCare" 1 "Select1000rpmMode" 0 "Select540rpmMode" ;
VAL_ 2365473534 RearPTOModeCmd 3 "DoNotCare" 1 "Select1000rpmMode" 0 "Select540rpmMode" ;
VAL_ 2365473534 FrontPTOEconomyModeCmd 3 "DoNotCare" 1 "EngagePTOEconomyMode" 0 "DisengagePTOEconomyMode" ;
VAL_ 2365473534 RearPTOEconomyModeCmd 3 "DoNotCare" 1 "EngagePTOEconomyMode" 0 "DisengagePTOEconomyMode" ;
VAL_ 2365473534 FrontPTOEngagementCmd 3 "DoNotCare" 1 "EngagePTO" 0 "DisengagePTO" ;
VAL_ 2365473534 RearPTOEngagementCmd 3 "DoNotCare" 1 "EngangePTO" 0 "DisengagePTO" ;
VAL_ 2365473278 ImplementRearWorkLightCmd 0 "Deactivate" 1 "Activate" 2 "Reserved" 3 "Dont Care" ;
VAL_ 2365473278 ImplementLeftFacingWorkLightCmd 3 "Dont Care" 1 "Activate" 0 "Deactivate" 2 "Reserved" ;
VAL_ 2365473278 ImplementRightFacingWorkLightCmd 0 "Deactivate" 1 "Activate" 2 "Reserved" 3 "Dont Care" ;
VAL_ 2365473278 LightingDataRequestCmd 3 "DoNotCare" 1 "Acitvate" 0 "Deactivate" ;
VAL_ 2365473278 ImplementLeftForwardLightCmd 3 "DoNotCare" 1 "Acitvate" 0 "Deactivate" ;
VAL_ 2365473278 ImplementRightForwardLightCmd 3 "DoNotCare" 1 "Acitvate" 0 "Deactivate" ;
VAL_ 2365473278 ImplementOEMOption1LightCmd 0 "Deactivate" 1 "Activate" 2 "Reserved" 3 "Dont Care" ;
VAL_ 2365473278 ImplementOEMOption2LightCmd 0 "Deactivate" 1 "Activate" 2 "Reserved" 3 "Dont Care" ;
VAL_ 2365473278 TractorFrontHighWorkLightCmd 3 "DoNotCare" 1 "Acitvate" 0 "Deactivate" ;
VAL_ 2365473278 TractorFrontLowWorkLightCmd 3 "DoNotCare" 1 "Acitvate" 0 "Deactivate" ;
VAL_ 2365473278 TractorSideHighWorkLightCmd 3 "DoNotCare" 1 "Acitvate" 0 "Deactivate" ;
VAL_ 2365473278 TractorSideLowWorkLightCmd 3 "DoNotCare" 1 "Acitvate" 0 "Deactivate" ;
VAL_ 2365473278 TractorRearHighWorkLightCmd 3 "DoNotCare" 1 "Acitvate" 0 "Deactivate" ;
VAL_ 2365473278 TractorRearLowWorkLightCmd 3 "DoNotCare" 1 "Acitvate" 0 "Deactivate" ;
VAL_ 2365473278 TractorUndersideWorkLightCmd 3 "DoNotCare" 1 "Acitvate" 0 "Deactivate" ;
VAL_ 2365473278 RearFogLightCmd 3 "Dont Care" 1 "Activate" 0 "Deactivate" 2 "Reserved" ;
VAL_ 2365473278 TractorMarkerLightCmd 3 "Dont Care" 1 "Activate" 0 "Deactivate" 2 "Reserved" ;
VAL_ 2365473278 ImplementMarkerLightCmd 3 "Dont Care" 1 "Activate" 0 "Deactivate" 2 "Reserved" ;
VAL_ 2365473278 TractorClearanceLightCmd 3 "Dont Care" 1 "Activate" 0 "Deactivate" 2 "Reserved" ;
VAL_ 2365473278 ImplementClearanceLightCmd 3 "Dont Care" 1 "Activate" 0 "Deactivate" 2 "Reserved" ;
VAL_ 2365473278 LeftStopLightCmd 3 "Dont Care" 1 "Activate" 0 "Deactivate" 2 "Reserved" ;
VAL_ 2365473278 RightStopLightCmd 0 "Deactivate" 1 "Activate" 2 "Reserved" 3 "Dont Care" ;
VAL_ 2365473278 CentreStopLightCmd 3 "DoNotCare" 1 "Acitvate" 0 "Deactivate" ;
VAL_ 2365473278 BackUpLightAndAlarmHornCmd 3 "Dont Care" 1 "Activate" 0 "Deactivate" 2 "Reserved" ;
VAL_ 2365473278 LeftTurnSignalLightCmd 3 "DoNotCare" 1 "Activate" 0 "Deactivate" ;
VAL_ 2365473278 RightTurnSignalLightCmd 3 "DoNotCare" 1 "Activate" 0 "Deactivate" ;
VAL_ 2365473278 RotatingBeaconLightCmd 0 "Deactivate" 1 "Activate" 2 "Reserved" 3 "Dont Care" ;
VAL_ 2365473278 TractorFrontFogLightCmd 3 "DoNotCare" 1 "Activate" 0 "Deactivate" ;
VAL_ 2365473278 HighBeamHeadLightCmd 3 "Dont Care" 1 "Activate" 0 "Deactivate" 2 "Reserved" ;
VAL_ 2365473278 LowBeamHeadLightCmd 3 "Dont Care" 1 "Activate" 0 "Deactivate" 2 "Reserved" ;
VAL_ 2365473278 AlternateHeadLightCmd 3 "DoNotCare" 1 "Activate" 0 "Deactivate" ;
VAL_ 2365473278 DaytimeRunningLightCmd 3 "DoNotCare" 1 "Activate" 0 "Deactivate" ;
VAL_ 2566799614 ImplementRearWorkLightData 3 "NotAvailable" 2 "FaultDetected" 1 "Activated" 0 "Deactivated" ;
VAL_ 2566799614 ImplLeftFacingWorkLightData 3 "NotAvailable" 2 "FaultDetected" 1 "Activated" 0 "Deactivated" ;
VAL_ 2566799614 ImplRightFacingWorkLightData 3 "NotAvailable" 2 "FaultDetected" 1 "Activated" 0 "Deactivated" ;
VAL_ 2566799614 ImplementLeftForwardLightData 3 "NotAvailable" 2 "FaultDetected" 1 "Activated" 0 "Deactivated" ;
VAL_ 2566799614 ImplementRightForwardLightData 3 "NotAvailable" 2 "FaultDetected" 1 "Activated" 0 "Deactivated" ;
VAL_ 2566799614 ImplementOEMOption1LightData 3 "NotAvailable" 2 "FaultDetected" 1 "Activated" 0 "Deactivated" ;
VAL_ 2566799614 ImplementOEMOption2LightData 3 "NotAvailable" 2 "FaultDetected" 1 "Activated" 0 "Deactivated" ;
VAL_ 2566799614 TractorFrontHighWorkLightData 3 "NotAvailable" 2 "FaultDetected" 1 "Activated" 0 "Deactivated" ;
VAL_ 2566799614 TractorFrontLowWorkLightData 3 "NotAvailable" 2 "FaultDetected" 1 "Activated" 0 "Deactivated" ;
VAL_ 2566799614 TractorSideHighWorkLightData 3 "NotAvailable" 2 "FaultDetected" 1 "Activated" 0 "Deactivated" ;
VAL_ 2566799614 TractorSideLowWorkLightData 3 "NotAvailable" 2 "FaultDetected" 1 "Activated" 0 "Deactivated" ;
VAL_ 2566799614 TractorRearHighWorkLightData 3 "NotAvailable" 2 "FaultDetected" 1 "Activated" 0 "Deactivated" ;
VAL_ 2566799614 TractorRearLowWorkLightData 3 "NotAvailable" 2 "FaultDetected" 1 "Activated" 0 "Deactivated" ;
VAL_ 2566799614 TractorUndersideWorkLightData 3 "NotAvailable" 2 "FaultDetected" 1 "Activated" 0 "Deactivated" ;
VAL_ 2566799614 RearFogLightData 3 "NotAvailable" 2 "FaultDetected" 1 "Activated" 0 "Deactivated" ;
VAL_ 2566799614 TractorMarkerLightData 3 "NotAvailable" 2 "FaultDetected" 1 "Activated" 0 "Deactivated" ;
VAL_ 2566799614 ImplementMarkerLightData 3 "NotAvailable" 2 "FaultDetected" 1 "Activated" 0 "Deactivated" ;
VAL_ 2566799614 TractorClearanceLightData 3 "NotAvailable" 2 "FaultDetected" 1 "Activated" 0 "Deactivated" ;
VAL_ 2566799614 ImplementClearanceLightData 3 "NotAvailable" 2 "FaultDetected" 1 "Activated" 0 "Deactivated" ;
VAL_ 2566799614 LefttStopLightData 3 "NotAvailable" 2 "FaultDetected" 1 "Activated" 0 "Deactivated" ;
VAL_ 2566799614 RightStopLightData 3 "NotAvailable" 2 "FaultDetected" 1 "Activated" 0 "Deactivated" ;
VAL_ 2566799614 CentreStopLightData 3 "NotAvailable" 2 "FaultDetected" 1 "Activated" 0 "Deactivated" ;
VAL_ 2566799614 BackUpLightAndAlarmHornData 3 "NotAvailable" 2 "FaultDetected" 1 "Activated" 0 "Deactivated" ;
VAL_ 2566799614 LeftTurnSignalLightData 3 "NotAvailable" 2 "FaultDetected" 1 "Activated" 0 "Deactivated" ;
VAL_ 2566799614 RightTurnSignalLightData 3 "NotAvailable" 2 "FaultDetected" 1 "Activated" 0 "Deactivated" ;
VAL_ 2566799614 RotationBeaconLightData 3 "NotAvailable" 2 "FaultDetected" 1 "Activated" 0 "Deactivated" ;
VAL_ 2566799614 TractorFrontFogLightData 3 "NotAvailable" 2 "FaultDetected" 1 "Activated" 0 "Deactivated" ;
VAL_ 2566799614 HighBeamHeadLightData 3 "Not Available" 2 "Fault Detected" 1 "Activated" 0 "Deactivated" ;
VAL_ 2566799614 LowBeamHeadLightData 3 "Not Available" 2 "Fault Detected" 1 "Activated" 0 "Deactivated" ;
VAL_ 2566799614 AlternateHeadLightData 3 "NotAvailable" 2 "FaultDetected" 1 "Activated" 0 "Deactivated" ;
VAL_ 2566799614 DaytimeRunningLightData 3 "NotAvailable" 2 "FaultDetected" 1 "Activated" 0 "Deactivated" ;
VAL_ 2365472766 Valve15FailSaveModeCmd 3 "DoNotCare" 1 "Float" 0 "Block" ;
VAL_ 2365472766 Valve15StateCmd 15 "Reserved" 3 "Float" 2 "Retract" 1 "Extend" 0 "Block" ;
VAL_ 2365472510 Valve14FailSaveModeCmd 3 "DoNotCare" 1 "Float" 0 "Block" ;
VAL_ 2365472510 Valve14StateCmd 15 "Reserved" 3 "Float" 2 "Retract" 1 "Extend" 0 "Block" ;
VAL_ 2365472254 Valve13FailSaveModeCmd 3 "DoNotCare" 1 "Float" 0 "Block" ;
VAL_ 2365472254 Valve13StateCmd 15 "Reserved" 3 "Float" 2 "Retract" 1 "Extend" 0 "Block" ;
VAL_ 2365471998 Valve12FailSaveModeCmd 3 "DoNotCare" 1 "Float" 0 "Block" ;
VAL_ 2365471998 Valve12StateCmd 15 "Reserved" 3 "Float" 2 "Retract" 1 "Extend" 0 "Block" ;
VAL_ 2365471742 Valve11FailSaveModeCmd 3 "DoNotCare" 1 "Float" 0 "Block" ;
VAL_ 2365471742 Valve11StateCmd 15 "Reserved" 3 "Float" 2 "Retract" 1 "Extend" 0 "Block" ;
VAL_ 2365471486 Valve10FailSaveModeCmd 3 "DoNotCare" 1 "Float" 0 "Block" ;
VAL_ 2365471486 Valve10StateCmd 15 "Reserved" 3 "Float" 2 "Retract" 1 "Extend" 0 "Block" ;
VAL_ 2365471230 Valve9FailSaveModeCmd 3 "DoNotCare" 1 "Float" 0 "Block" ;
VAL_ 2365471230 Valve9StateCmd 15 "Reserved" 3 "Float" 2 "Retract" 1 "Extend" 0 "Block" ;
VAL_ 2365470974 Valve8FailSaveModeCmd 3 "DoNotCare" 1 "Float" 0 "Block" ;
VAL_ 2365470974 Valve8StateCmd 15 "Reserved" 3 "Float" 2 "Retract" 1 "Extend" 0 "Block" ;
VAL_ 2365470718 Valve7FailSaveModeCmd 3 "DoNotCare" 1 "Float" 0 "Block" ;
VAL_ 2365470718 Valve7StateCmd 15 "Reserved" 3 "Float" 2 "Retract" 1 "Extend" 0 "Block" ;
VAL_ 2365470462 Valve6FailSaveModeCmd 3 "DoNotCare" 1 "Float" 0 "Block" ;
VAL_ 2365470462 Valve6StateCmd 15 "Reserved" 3 "Float" 2 "Retract" 1 "Extend" 0 "Block" ;
VAL_ 2365470206 Valve5FailSaveModeCmd 3 "DoNotCare" 1 "Float" 0 "Block" ;
VAL_ 2365470206 Valve5StateCmd 15 "Reserved" 3 "Float" 2 "Retract" 1 "Extend" 0 "Block" ;
VAL_ 2365469950 Valve4FailSaveModeCmd 3 "DoNotCare" 1 "Float" 0 "Block" ;
VAL_ 2365469950 Valve4StateCmd 15 "Reserved" 3 "Float" 2 "Retract" 1 "Extend" 0 "Block" ;
VAL_ 2365469694 Valve3FailSaveModeCmd 3 "DoNotCare" 1 "Float" 0 "Block" ;
VAL_ 2365469694 Valve3StateCmd 15 "Reserved" 3 "Float" 2 "Retract" 1 "Extend" 0 "Block" ;
VAL_ 2365469438 Valve2FailSaveModeCmd 3 "DoNotCare" 1 "Float" 0 "Block" ;
VAL_ 2365469438 Valve2StateCmd 15 "Reserved" 3 "Float" 2 "Retract" 1 "Extend" 0 "Block" ;
VAL_ 2365469182 Valve1FailSaveModeCmd 3 "DoNotCare" 1 "Float" 0 "Block" ;
VAL_ 2365469182 Valve1StateCmd 15 "Reserved" 3 "Float" 2 "Retract" 1 "Extend" 0 "Block" ;
VAL_ 2365468926 Valve0FailSaveModeCmd 3 "DoNotCare" 1 "Float" 0 "Block" ;
VAL_ 2365468926 Valve0StateCmd 15 "Reserved" 3 "Float" 2 "Retract" 1 "Extend" 0 "Block" ;
VAL_ 2365468670 Valve15LimitStatus 0 "Not limited" 1 "Operator Limited" 2 "Limited High" 3 "Limited Low" 4 "Reserved" 5 "Reserver" 6 "Non-recoverable Fault" 7 "Not available" ;
VAL_ 2365468414 Valve14LimitStatus 0 "Not limited" 1 "Operator Limited" 2 "Limited High" 3 "Limited Low" 4 "Reserved" 5 "Reserver" 6 "Non-recoverable Fault" 7 "Not available" ;
VAL_ 2365468158 Valve13LimitStatus 0 "Not limited" 1 "Operator Limited" 2 "Limited High" 3 "Limited Low" 4 "Reserved" 5 "Reserver" 6 "Non-recoverable Fault" 7 "Not available" ;
VAL_ 2365467902 Valve12LimitStatus 0 "Not limited" 1 "Operator Limited" 2 "Limited High" 3 "Limited Low" 4 "Reserved" 5 "Reserver" 6 "Non-recoverable Fault" 7 "Not available" ;
VAL_ 2365467646 Valve11LimitStatus 0 "Not limited" 1 "Operator Limited" 2 "Limited High" 3 "Limited Low" 4 "Reserved" 5 "Reserver" 6 "Non-recoverable Fault" 7 "Not available" ;
VAL_ 2365467390 Valve10LimitStatus 0 "Not limited" 1 "Operator Limited" 2 "Limited High" 3 "Limited Low" 4 "Reserved" 5 "Reserver" 6 "Non-recoverable Fault" 7 "Not available" ;
VAL_ 2365467134 Valve9LimitStatus 0 "Not limited" 1 "Operator Limited" 2 "Limited High" 3 "Limited Low" 4 "Reserved" 5 "Reserver" 6 "Non-recoverable Fault" 7 "Not available" ;
VAL_ 2365466878 Valve8LimitStatus 0 "Not limited" 1 "Operator Limited" 2 "Limited High" 3 "Limited Low" 4 "Reserved" 5 "Reserver" 6 "Non-recoverable Fault" 7 "Not available" ;
VAL_ 2365466622 Valve7LimitStatus 0 "Not limited" 1 "Operator Limited" 2 "Limited High" 3 "Limited Low" 4 "Reserved" 5 "Reserver" 6 "Non-recoverable Fault" 7 "Not available" ;
VAL_ 2365466366 Valve6LimitStatus 0 "Not limited" 1 "Operator Limited" 2 "Limited High" 3 "Limited Low" 4 "Reserved" 5 "Reserver" 6 "Non-recoverable Fault" 7 "Not available" ;
VAL_ 2365466110 Valve5LimitStatus 0 "Not limited" 1 "Operator Limited" 2 "Limited High" 3 "Limited Low" 4 "Reserved" 5 "Reserver" 6 "Non-recoverable Fault" 7 "Not available" ;
VAL_ 2365465854 Valve4LimitStatus 0 "Not limited" 1 "Operator Limited" 2 "Limited High" 3 "Limited Low" 4 "Reserved" 5 "Reserver" 6 "Non-recoverable Fault" 7 "Not available" ;
VAL_ 2365465598 Valve3LimitStatus 0 "Not limited" 1 "Operator Limited" 2 "Limited High" 3 "Limited Low" 4 "Reserved" 5 "Reserver" 6 "Non-recoverable Fault" 7 "Not available" ;
VAL_ 2365465342 Valve2LimitStatus 0 "Not limited" 1 "Operator Limited" 2 "Limited High" 3 "Limited Low" 4 "Reserved" 5 "Reserver" 6 "Non-recoverable Fault" 7 "Not available" ;
VAL_ 2365465086 Valve1LimitStatus 0 "Not limited" 1 "Operator Limited" 2 "Limited High" 3 "Limited Low" 4 "Reserved" 5 "Reserver" 6 "Non-recoverable Fault" 7 "Not available" ;
VAL_ 2365464830 Valve0LimitStatus 0 "Not limited" 1 "Operator Limited" 2 "Limited High" 3 "Limited Low" 4 "Reserved" 5 "Reserver" 6 "Non-recoverable Fault" 7 "Not available" ;
VAL_ 2365464574 AuxValve15ExitReasonCode 0 "No reason/all clear " 1 "Operator presence not detected " 2 "Implement released control of function" 3 "Operator override of function" 4 "Operator control not in valid position" 5 "Remote command timeout " 6 "Remote command out of range/invalid " 7 "Function not calibrated" 8 "Operator control fault " 9 "Function fault " 20 "Hydraulic oil level too low " 21 "Valve locked out " 62 "Error " 63 "Not available (parameter not supported)" ;
VAL_ 2365464574 Valve15LimitStatus 0 "Not limited" 1 "Operator Limited" 2 "Limited High" 3 "Limited Low" 4 "Reserved" 5 "Reserver" 6 "Non-recoverable Fault" 7 "Not available" ;
VAL_ 2365464574 Valve15FailSafeMode 3 "NotAvailable" 2 "ErrorIndication" 1 "Float" 0 "Block" ;
VAL_ 2365464574 Valve15ValveState 15 "DoNotCare" 14 "ErrorIndication" 3 "Floating" 2 "Retract" 1 "Extend" 0 "Blocked" ;
VAL_ 2365464318 Valve14LimitStatus 0 "Not limited" 1 "Operator Limited" 2 "Limited High" 3 "Limited Low" 4 "Reserved" 5 "Reserver" 6 "Non-recoverable Fault" 7 "Not available" ;
VAL_ 2365464318 Valve14FailSafeMode 3 "NotAvailable" 2 "ErrorIndication" 1 "Float" 0 "Block" ;
VAL_ 2365464318 Valve14ValveState 15 "DoNotCare" 14 "ErrorIndication" 3 "Floating" 2 "Retract" 1 "Extend" 0 "Blocked" ;
VAL_ 2365464062 Valve13LimitStatus 0 "Not limited" 1 "Operator Limited" 2 "Limited High" 3 "Limited Low" 4 "Reserved" 5 "Reserver" 6 "Non-recoverable Fault" 7 "Not available" ;
VAL_ 2365464062 Valve13FailSafeMode 3 "NotAvailable" 2 "ErrorIndication" 1 "Float" 0 "Block" ;
VAL_ 2365464062 Valve13ValveState 15 "DoNotCare" 14 "ErrorIndication" 3 "Floating" 2 "Retract" 1 "Extend" 0 "Blocked" ;
VAL_ 2365463806 Valve12LimitStatus 0 "Not limited" 1 "Operator Limited" 2 "Limited High" 3 "Limited Low" 4 "Reserved" 5 "Reserver" 6 "Non-recoverable Fault" 7 "Not available" ;
VAL_ 2365463806 Valve12FailSafeMode 3 "NotAvailable" 2 "ErrorIndication" 1 "Float" 0 "Block" ;
VAL_ 2365463806 Valve12ValveState 15 "DoNotCare" 14 "ErrorIndication" 3 "Floating" 2 "Retract" 1 "Extend" 0 "Blocked" ;
VAL_ 2365463550 Valve11LimitStatus 0 "Not limited" 1 "Operator Limited" 2 "Limited High" 3 "Limited Low" 4 "Reserved" 5 "Reserver" 6 "Non-recoverable Fault" 7 "Not available" ;
VAL_ 2365463550 Valve11FailSafeMode 3 "NotAvailable" 2 "ErrorIndication" 1 "Float" 0 "Block" ;
VAL_ 2365463550 Valve11ValveState 15 "DoNotCare" 14 "ErrorIndication" 3 "Floating" 2 "Retract" 1 "Extend" 0 "Blocked" ;
VAL_ 2365463294 Valve10LimitStatus 0 "Not limited" 1 "Operator Limited" 2 "Limited High" 3 "Limited Low" 4 "Reserved" 5 "Reserver" 6 "Non-recoverable Fault" 7 "Not available" ;
VAL_ 2365463294 Valve10FailSafeMode 3 "NotAvailable" 2 "ErrorIndication" 1 "Float" 0 "Block" ;
VAL_ 2365463294 Valve10ValveState 15 "DoNotCare" 14 "ErrorIndication" 3 "Floating" 2 "Retract" 1 "Extend" 0 "Blocked" ;
VAL_ 2365463038 Valve9LimitStatus 0 "Not limited" 1 "Operator Limited" 2 "Limited High" 3 "Limited Low" 4 "Reserved" 5 "Reserver" 6 "Non-recoverable Fault" 7 "Not available" ;
VAL_ 2365463038 Valve9FailSafeMode 3 "NotAvailable" 2 "ErrorIndication" 1 "Float" 0 "Block" ;
VAL_ 2365463038 Valve9ValveState 15 "DoNotCare" 14 "ErrorIndication" 3 "Floating" 2 "Retract" 1 "Extend" 0 "Blocked" ;
VAL_ 2365462782 Valve8LimitStatus 0 "Not limited" 1 "Operator Limited" 2 "Limited High" 3 "Limited Low" 4 "Reserved" 5 "Reserver" 6 "Non-recoverable Fault" 7 "Not available" ;
VAL_ 2365462782 Valve8FailSafeMode 3 "NotAvailable" 2 "ErrorIndication" 1 "Float" 0 "Block" ;
VAL_ 2365462782 Valve8ValveState 15 "DoNotCare" 14 "ErrorIndication" 3 "Floating" 2 "Retract" 1 "Extend" 0 "Blocked" ;
VAL_ 2365462526 Valve7LimitStatus 0 "Not limited" 1 "Operator Limited" 2 "Limited High" 3 "Limited Low" 4 "Reserved" 5 "Reserver" 6 "Non-recoverable Fault" 7 "Not available" ;
VAL_ 2365462526 Valve7FailSafeMode 3 "NotAvailable" 2 "ErrorIndication" 1 "Float" 0 "Block" ;
VAL_ 2365462526 Valve7ValveState 15 "DoNotCare" 14 "ErrorIndication" 3 "Floating" 2 "Retract" 1 "Extend" 0 "Blocked" ;
VAL_ 2365462270 Valve6LimitStatus 0 "Not limited" 1 "Operator Limited" 2 "Limited High" 3 "Limited Low" 4 "Reserved" 5 "Reserver" 6 "Non-recoverable Fault" 7 "Not available" ;
VAL_ 2365462270 Valve6FailSafeMode 3 "NotAvailable" 2 "ErrorIndication" 1 "Float" 0 "Block" ;
VAL_ 2365462270 Valve6ValveState 15 "DoNotCare" 14 "ErrorIndication" 3 "Floating" 2 "Retract" 1 "Extend" 0 "Blocked" ;
VAL_ 2365462014 Valve5LimitStatus 0 "Not limited" 1 "Operator Limited" 2 "Limited High" 3 "Limited Low" 4 "Reserved" 5 "Reserver" 6 "Non-recoverable Fault" 7 "Not available" ;
VAL_ 2365462014 Valve5FailSafeMode 3 "NotAvailable" 2 "ErrorIndication" 1 "Float" 0 "Block" ;
VAL_ 2365462014 Valve5ValveState 15 "DoNotCare" 14 "ErrorIndication" 3 "Floating" 2 "Retract" 1 "Extend" 0 "Blocked" ;
VAL_ 2365461758 Valve4LimitStatus 0 "Not limited" 1 "Operator Limited" 2 "Limited High" 3 "Limited Low" 4 "Reserved" 5 "Reserver" 6 "Non-recoverable Fault" 7 "Not available" ;
VAL_ 2365461758 Valve4FailSafeMode 3 "NotAvailable" 2 "ErrorIndication" 1 "Float" 0 "Block" ;
VAL_ 2365461758 Valve4ValveState 15 "DoNotCare" 14 "ErrorIndication" 3 "Floating" 2 "Retract" 1 "Extend" 0 "Blocked" ;
VAL_ 2365461502 Valve3LimitStatus 0 "Not limited" 1 "Operator Limited" 2 "Limited High" 3 "Limited Low" 4 "Reserved" 5 "Reserver" 6 "Non-recoverable Fault" 7 "Not available" ;
VAL_ 2365461502 Valve3FailSafeMode 3 "NotAvailable" 2 "ErrorIndication" 1 "Float" 0 "Block" ;
VAL_ 2365461502 Valve3ValveState 15 "DoNotCare" 14 "ErrorIndication" 3 "Floating" 2 "Retract" 1 "Extend" 0 "Blocked" ;
VAL_ 2365461246 Valve2LimitStatus 0 "Not limited" 1 "Operator Limited" 2 "Limited High" 3 "Limited Low" 4 "Reserved" 5 "Reserver" 6 "Non-recoverable Fault" 7 "Not available" ;
VAL_ 2365461246 Valve2FailSafeMode 3 "NotAvailable" 2 "ErrorIndication" 1 "Float" 0 "Block" ;
VAL_ 2365461246 Valve2ValveState 15 "DoNotCare" 14 "ErrorIndication" 3 "Floating" 2 "Retract" 1 "Extend" 0 "Blocked" ;

SG_MUL_VAL_ 2624585470 ChallengeData MessageCode 5-5, 7-7;
SG_MUL_VAL_ 2624585470 ErrorCode MessageCode 3-3, 5-5, 7-7, 250-250;
SG_MUL_VAL_ 2624585470 CertType MessageCode 2-2, 3-3;
SG_MUL_VAL_ 2624585470 CertificateFormat MessageCode 2-2, 3-3;
SG_MUL_VAL_ 2624585470 AuthenticationType MessageCode 2-8, 250-250;
SG_MUL_VAL_ 2624651006 ChallengeData MessageCode 4-4, 6-6;
SG_MUL_VAL_ 2624651006 CertType MessageCode 2-2, 3-3;
SG_MUL_VAL_ 2624651006 CertificateFormat MessageCode 2-2, 3-3;
SG_MUL_VAL_ 2624651006 AuthenticationType MessageCode 2-7, 9-9, 249-249;
SG_MUL_VAL_ 2624651006 ErrorCode MessageCode 2-2, 4-4, 6-6, 249-249;
SG_MUL_VAL_ 2619670270 HitchPosReq GroupFunctionValue 66-67;
SG_MUL_VAL_ 2619670270 PTOSpeedRequest GroupFunctionValue 64-65;
SG_MUL_VAL_ 2619670270 RequestCounter GroupFunctionValue 1-32, 64-68, 70-70;
SG_MUL_VAL_ 2619670270 AuxValveFlowReq GroupFunctionValue 1-32;
SG_MUL_VAL_ 2619670270 MinimumTIMVersionNr GroupFunctionValue 246-246, 247-247;
SG_MUL_VAL_ 2619670270 ImplementedTIMVersionNr GroupFunctionValue 246-246, 247-247;
SG_MUL_VAL_ 2619670270 TIMMessageType GroupFunctionValue 1-32, 64-68, 70-70;
SG_MUL_VAL_ 2619604734 HitchPosition GroupFunctionValue 66-67;
SG_MUL_VAL_ 2619604734 HitchExitReasonCode GroupFunctionValue 66-67;
SG_MUL_VAL_ 2619604734 PTOSpeed GroupFunctionValue 64-64, 65-65;
SG_MUL_VAL_ 2619604734 PTOExitReasonCode GroupFunctionValue 64-65;
SG_MUL_VAL_ 2619604734 TIMAuxValveFlow GroupFunctionValue 1-32;
SG_MUL_VAL_ 2619604734 FlowType GroupFunctionValue 1-32;
SG_MUL_VAL_ 2619604734 ReflectedRequestCounter GroupFunctionValue 1-32, 64-68, 70-70;
SG_MUL_VAL_ 2619604734 AuxValveExitReasonCode GroupFunctionValue 1-32;
SG_MUL_VAL_ 2619604734 AutomationStatus GroupFunctionValue 1-32, 64-68, 70-70;
SG_MUL_VAL_ 2619604734 TIMMessageType GroupFunctionValue 1-32, 64-68, 70-70;
